VERSION ""

NS_ :

BS_:

BU_: PowertrainControlModule AtmosphericSensor SafetyRestraintSystem2 Aftertreatment_2_GasOutlet Aftertreatment_2_GasIntake DieselParticulateFilterControl Turbocharger SafetyRestraintSystem1 CabDisplay2 Aftertreatment_1_GasOutlet Aftertreatment_1_GasIntake OnBoardDataLogger OffBoardDiagnosticTool2 OffBoardDiagnosticTool1 FileServer ParkingBrakeController SeatController2 FanDriveController SteeringColumnUnit CommunicationUnitRadio CommunicationUnitSatellite CommunicationUnitCellular PropulsionBatteryCharger ChassisController2 ChassisController1 EngineValveControl AuxiliaryHeater2 AuxiliaryHeater1 ClutchUnit RampControl InformationSystem1 SuspensionSystemController2 OilSensor VehicleDynamicStability ExhaustEmissionController TransmissionDisplay2 TransmissionDisplay1 ClimateControl2 WaterPumpController RearAxleSteeringController LightingOperatorControl SeatController1 IgnitionController2 IgnitionController1 TirePressureController CabController2 CabController1 PneumaticSystemController SuspensionSystemController1 HydraulicPumpController EnduranceBrakingSystem RetarderExhaustEngine2 OnBoardDiagnosticUnit HeadwayController RetarderExhaustEngine1 CabDisplay1 ManagementComputer VirtualTerminal OffVehicleGateway PowerTakeOffFront HitchControl AuxiliaryValveControl BodyController TractorTrailerBridge1 StarterSystem ElectricalSystem VehicleSecurity VehicleNavigation AerodynamicControl ElectricalChargingSystem ClimateControl1 TripRecorder InstrumentCluster SuspensionDriveAxle2 SuspensionDriveAxle1 SuspensionSteerAxle SteeringController FuelSystem CruiseControl RetarderDriveline RetarderEngine BrakesDriveAxle2 BrakesDriveAxle1 BrakesSystemController BrakesSteerAxle AxleDrive2 AxleDrive1 AxleSteering PowerTakeOff ShiftConsoleSecondary ShiftConsolePrimary Transmission2 Transmission1 Engine2 Engine1

BO_ 2566834942 DM01: 22 Vector__XXX
 SG_ FlashRedStopLamp : 12|2@1+ (1,0) [0|3] "" Vector__XXX
 SG_ FlashProtectLamp : 8|2@1+ (1,0) [0|3] "" Vector__XXX
 SG_ FlashMalfuncIndicatorLamp : 14|2@1+ (1,0) [0|3] "" Vector__XXX
 SG_ FlashAmberWarningLamp : 10|2@1+ (1,0) [0|3] "" Vector__XXX
 SG_ MalfunctionIndicatorLampStatus : 6|2@1+ (1,0) [0|3] "" Vector__XXX
 SG_ AmberWarningLampStatus : 2|2@1+ (1,0) [0|3] "" Vector__XXX
 SG_ RedStopLampState : 4|2@1+ (1,0) [0|3] "" Vector__XXX
 SG_ ProtectLampStatus : 0|2@1+ (1,0) [0|3] "" Vector__XXX
 SG_ DTC5 : 144|32@1+ (1,0) [0|4294967295] "" Vector__XXX
 SG_ DTC4 : 112|32@1+ (1,0) [0|4294967295] "" Vector__XXX
 SG_ DTC3 : 80|32@1+ (1,0) [0|4294967295] "" Vector__XXX
 SG_ DTC2 : 48|32@1+ (1,0) [0|4294967295] "" Vector__XXX
 SG_ DTC1 : 16|32@1+ (1,0) [0|4294967295] "" Vector__XXX

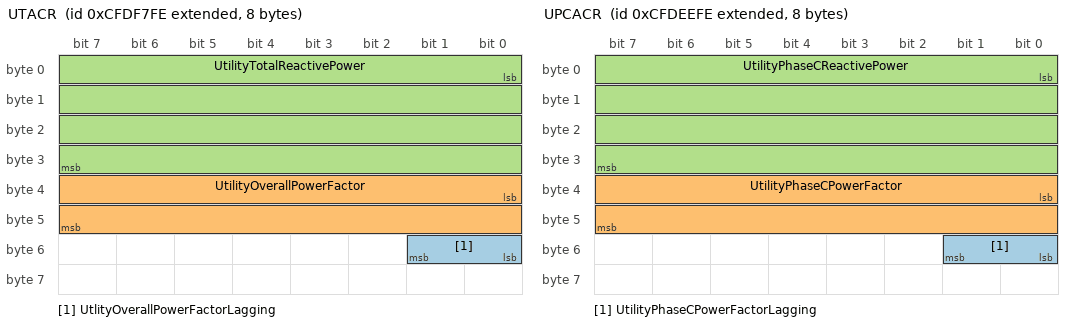
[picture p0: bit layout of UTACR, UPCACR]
BO_ 2365454334 UTACR: 8 Vector__XXX
 SG_ UtlityOverallPowerFactorLagging : 48|2@1+ (1,0) [0|3] "" Vector__XXX
 SG_ UtilityOverallPowerFactor : 32|16@1+ (6.103515625E-005,-1) [-1|2.921814] "" Vector__XXX
 SG_ UtilityTotalReactivePower : 0|32@1+ (1,-2000000000) [-2000000000|2211081215] "VAr" Vector__XXX

BO_ 2365454590 UTACP: 8 Vector__XXX
 SG_ UtilityTotalApparentPower : 32|32@1+ (1,-2000000000) [-2000000000|2211081215] "VA" Vector__XXX
 SG_ UtilityTotalRealPower : 0|32@1+ (1,-2000000000) [-2000000000|2211081215] "W" Vector__XXX

BO_ 2365451774 UTACE: 8 Vector__XXX
 SG_ UtilityTotalKWHoursImport : 32|32@1+ (1,0) [0|4211081215] "kWh" Vector__XXX
 SG_ UtilityTotalKWHoursExport : 0|32@1+ (1,0) [0|4211081215] "kWh" Vector__XXX

BO_ 2365452030 UPCACR: 8 Vector__XXX
 SG_ UtilityPhaseCPowerFactorLagging : 48|2@1+ (1,0) [0|3] "" Vector__XXX
 SG_ UtilityPhaseCPowerFactor : 32|16@1+ (6.103515625E-005,-1) [-1|2.921814] "" Vector__XXX
 SG_ UtilityPhaseCReactivePower : 0|32@1+ (1,-2000000000) [-2000000000|2211081215] "VAr" Vector__XXX

BO_ 2365452286 UPCACP: 8 Vector__XXX
 SG_ UtilityPhaseCApparentPower : 32|32@1+ (1,-2000000000) [-2000000000|2211081215] "VA" Vector__XXX
 SG_ UtilityPhaseCRealPower : 0|32@1+ (1,-2000000000) [-2000000000|2211081215] "W" Vector__XXX

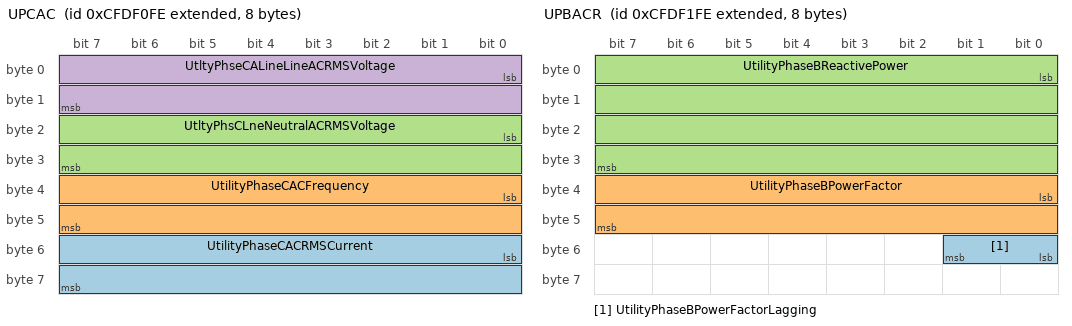
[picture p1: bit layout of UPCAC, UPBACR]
BO_ 2365452542 UPCAC: 8 Vector__XXX
 SG_ UtilityPhaseCACRMSCurrent : 48|16@1+ (1,0) [0|64255] "A" Vector__XXX
 SG_ UtilityPhaseCACFrequency : 32|16@1+ (0.0078125,0) [0|501.9921875] "Hz" Vector__XXX
 SG_ UtltyPhsCLneNeutralACRMSVoltage : 16|16@1+ (1,0) [0|64255] "V" Vector__XXX
 SG_ UtltyPhseCALineLineACRMSVoltage : 0|16@1+ (1,0) [0|64255] "V" Vector__XXX

BO_ 2365452798 UPBACR: 8 Vector__XXX
 SG_ UtilityPhaseBPowerFactorLagging : 48|2@1+ (1,0) [0|3] "" Vector__XXX
 SG_ UtilityPhaseBPowerFactor : 32|16@1+ (6.103515625E-005,-1) [-1|2.921814] "" Vector__XXX
 SG_ UtilityPhaseBReactivePower : 0|32@1+ (1,-2000000000) [-2000000000|2211081215] "VAr" Vector__XXX

BO_ 2365453054 UPBACP: 8 Vector__XXX
 SG_ UtilityPhaseBApparentPower : 32|32@1+ (1,-2000000000) [-2000000000|2211081215] "VA" Vector__XXX
 SG_ UtilityPhaseBRealPower : 0|32@1+ (1,-2000000000) [-2000000000|2211081215] "W" Vector__XXX

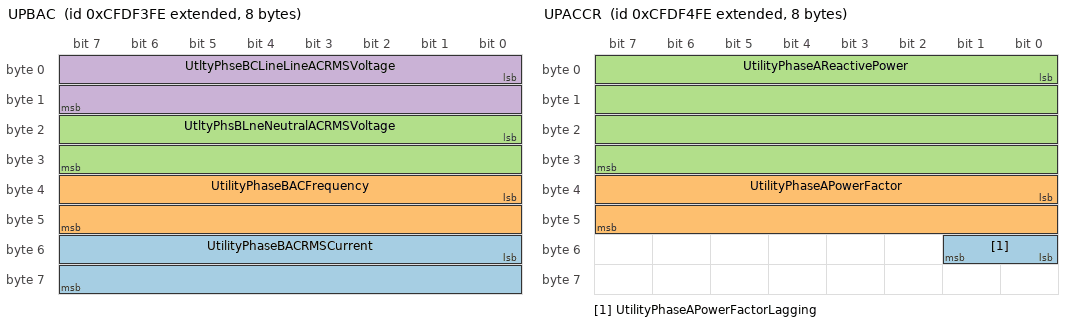
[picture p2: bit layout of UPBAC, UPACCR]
BO_ 2365453310 UPBAC: 8 Vector__XXX
 SG_ UtilityPhaseBACRMSCurrent : 48|16@1+ (1,0) [0|64255] "A" Vector__XXX
 SG_ UtilityPhaseBACFrequency : 32|16@1+ (0.0078125,0) [0|501.9921875] "Hz" Vector__XXX
 SG_ UtltyPhsBLneNeutralACRMSVoltage : 16|16@1+ (1,0) [0|64255] "V" Vector__XXX
 SG_ UtltyPhseBCLineLineACRMSVoltage : 0|16@1+ (1,0) [0|64255] "V" Vector__XXX

BO_ 2365453566 UPACCR: 8 Vector__XXX
 SG_ UtilityPhaseAPowerFactorLagging : 48|2@1+ (1,0) [0|3] "" Vector__XXX
 SG_ UtilityPhaseAPowerFactor : 32|16@1+ (6.103515625E-005,-1) [-1|2.921814] "" Vector__XXX
 SG_ UtilityPhaseAReactivePower : 0|32@1+ (1,-2000000000) [-2000000000|2211081215] "VAr" Vector__XXX

BO_ 2365453822 UPAACP: 8 Vector__XXX
 SG_ UtilityPhaseAApparentPower : 32|32@1+ (1,-2000000000) [-2000000000|2211081215] "VA" Vector__XXX
 SG_ UtilityPhaseARealPower : 0|32@1+ (1,-2000000000) [-2000000000|2211081215] "W" Vector__XXX

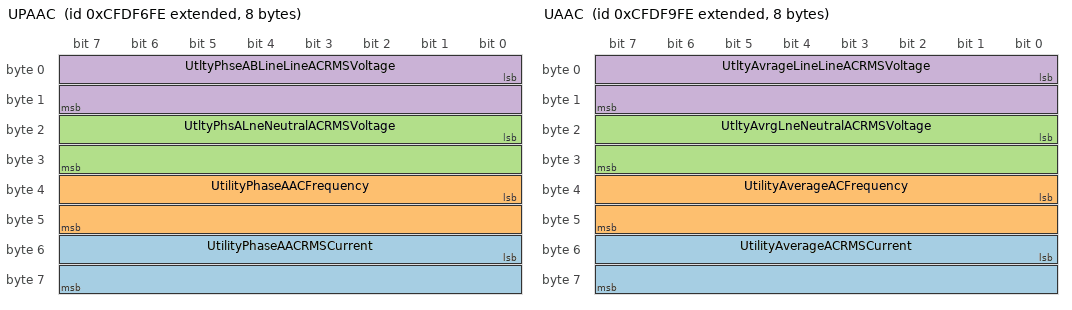
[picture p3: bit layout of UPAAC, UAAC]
BO_ 2365454078 UPAAC: 8 Vector__XXX
 SG_ UtilityPhaseAACRMSCurrent : 48|16@1+ (1,0) [0|64255] "A" Vector__XXX
 SG_ UtilityPhaseAACFrequency : 32|16@1+ (0.0078125,0) [0|501.9921875] "Hz" Vector__XXX
 SG_ UtltyPhsALneNeutralACRMSVoltage : 16|16@1+ (1,0) [0|64255] "V" Vector__XXX
 SG_ UtltyPhseABLineLineACRMSVoltage : 0|16@1+ (1,0) [0|64255] "V" Vector__XXX

BO_ 2365454846 UAAC: 8 Vector__XXX
 SG_ UtilityAverageACRMSCurrent : 48|16@1+ (1,0) [0|64255] "A" Vector__XXX
 SG_ UtilityAverageACFrequency : 32|16@1+ (0.0078125,0) [0|501.9921875] "Hz" Vector__XXX
 SG_ UtltyAvrgLneNeutralACRMSVoltage : 16|16@1+ (1,0) [0|64255] "V" Vector__XXX
 SG_ UtltyAvrageLineLineACRMSVoltage : 0|16@1+ (1,0) [0|64255] "V" Vector__XXX

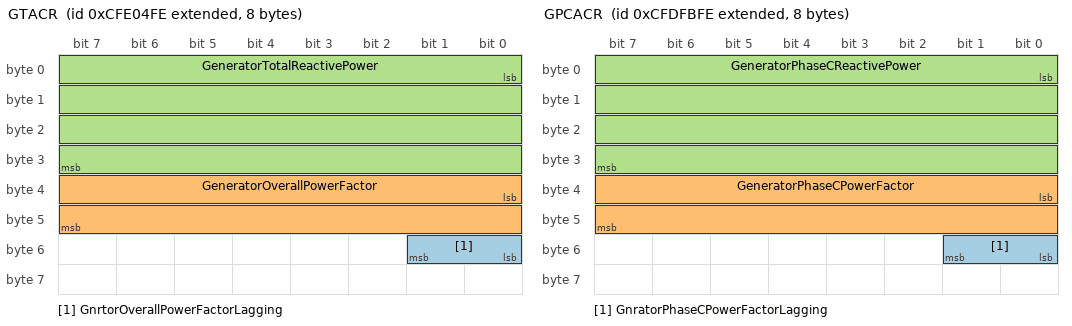
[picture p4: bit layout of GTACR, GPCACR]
BO_ 2365457662 GTACR: 8 Vector__XXX
 SG_ GnrtorOverallPowerFactorLagging : 48|2@1+ (1,0) [0|3] "" Vector__XXX
 SG_ GeneratorOverallPowerFactor : 32|16@1+ (6.103515625E-005,-1) [-1|1] "" Vector__XXX
 SG_ GeneratorTotalReactivePower : 0|32@1+ (1,-2000000000) [-2000000000|2211081215] "VAr" Vector__XXX

BO_ 2365457918 GTACP: 8 Vector__XXX
 SG_ GeneratorTotalApparentPower : 32|32@1+ (1,-2000000000) [-2000000000|2211081215] "VA" Vector__XXX
 SG_ GeneratorTotalRealPower : 0|32@1+ (1,-2000000000) [-2000000000|2211081215] "W" Vector__XXX

BO_ 2365455102 GTACE: 8 Vector__XXX
 SG_ GeneratorTotalKWHoursImport : 32|32@1+ (1,0) [0|4211081215] "kWh" Vector__XXX
 SG_ GeneratorTotalKWHoursExport : 0|32@1+ (1,0) [0|4211081215] "kWh" Vector__XXX

BO_ 2365455358 GPCACR: 8 Vector__XXX
 SG_ GnratorPhaseCPowerFactorLagging : 48|2@1+ (1,0) [0|3] "" Vector__XXX
 SG_ GeneratorPhaseCPowerFactor : 32|16@1+ (6.103515625E-005,-1) [-1|1] "" Vector__XXX
 SG_ GeneratorPhaseCReactivePower : 0|32@1+ (1,-2000000000) [-2000000000|2211081215] "VAr" Vector__XXX

BO_ 2365455614 GPCACP: 8 Vector__XXX
 SG_ GeneratorPhaseCApparentPower : 32|32@1+ (1,-2000000000) [-2000000000|2211081215] "VA" Vector__XXX
 SG_ GeneratorPhaseCRealPower : 0|32@1+ (1,-2000000000) [-2000000000|2211081215] "W" Vector__XXX

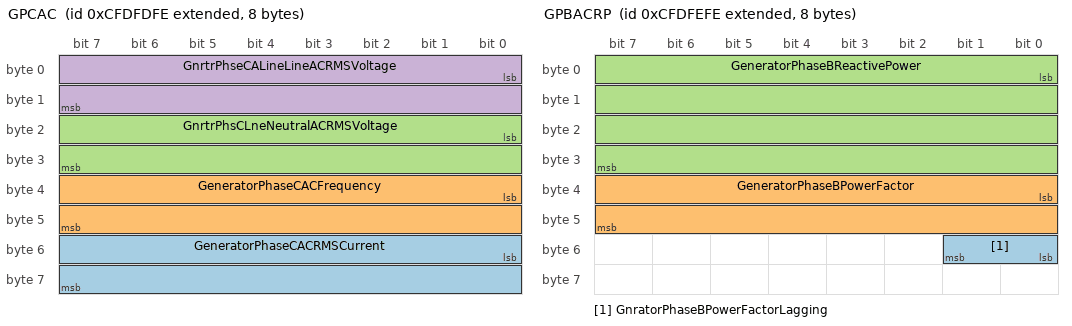
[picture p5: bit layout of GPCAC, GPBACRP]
BO_ 2365455870 GPCAC: 8 Vector__XXX
 SG_ GeneratorPhaseCACRMSCurrent : 48|16@1+ (1,0) [0|64255] "A" Vector__XXX
 SG_ GeneratorPhaseCACFrequency : 32|16@1+ (0.0078125,0) [0|501.9921875] "Hz" Vector__XXX
 SG_ GnrtrPhsCLneNeutralACRMSVoltage : 16|16@1+ (1,0) [0|64255] "V" Vector__XXX
 SG_ GnrtrPhseCALineLineACRMSVoltage : 0|16@1+ (1,0) [0|64255] "V" Vector__XXX

BO_ 2365456126 GPBACRP: 8 Vector__XXX
 SG_ GnratorPhaseBPowerFactorLagging : 48|2@1+ (1,0) [0|3] "" Vector__XXX
 SG_ GeneratorPhaseBPowerFactor : 32|16@1+ (6.103515625E-005,-1) [-1|1] "" Vector__XXX
 SG_ GeneratorPhaseBReactivePower : 0|32@1+ (1,-2000000000) [-2000000000|2211081215] "VAr" Vector__XXX

BO_ 2365456382 GPBACP: 8 Vector__XXX
 SG_ GeneratorPhaseBApparentPower : 32|32@1+ (1,-2000000000) [-2000000000|2211081215] "VA" Vector__XXX
 SG_ GeneratorPhaseBRealPower : 0|32@1+ (1,-2000000000) [-2000000000|2211081215] "W" Vector__XXX

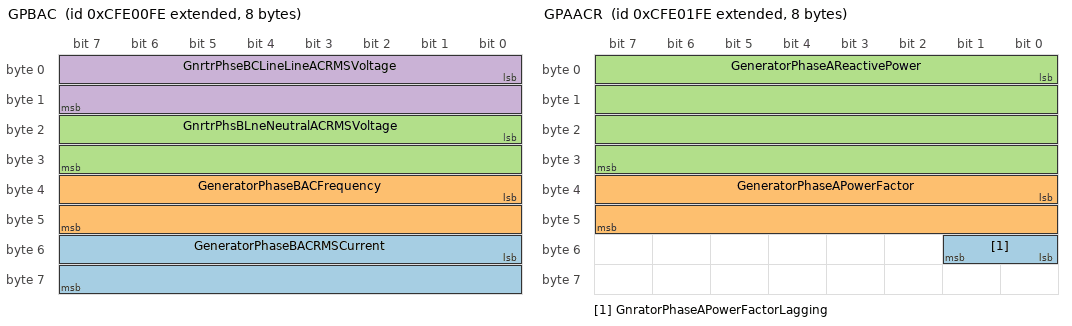
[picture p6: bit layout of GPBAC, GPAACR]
BO_ 2365456638 GPBAC: 8 Vector__XXX
 SG_ GeneratorPhaseBACRMSCurrent : 48|16@1+ (1,0) [0|64255] "A" Vector__XXX
 SG_ GeneratorPhaseBACFrequency : 32|16@1+ (0.0078125,0) [0|501.9921875] "Hz" Vector__XXX
 SG_ GnrtrPhsBLneNeutralACRMSVoltage : 16|16@1+ (1,0) [0|64255] "V" Vector__XXX
 SG_ GnrtrPhseBCLineLineACRMSVoltage : 0|16@1+ (1,0) [0|64255] "V" Vector__XXX

BO_ 2365456894 GPAACR: 8 Vector__XXX
 SG_ GnratorPhaseAPowerFactorLagging : 48|2@1+ (1,0) [0|3] "" Vector__XXX
 SG_ GeneratorPhaseAPowerFactor : 32|16@1+ (6.103515625E-005,-1) [-1|1] "" Vector__XXX
 SG_ GeneratorPhaseAReactivePower : 0|32@1+ (1,-2000000000) [-2000000000|2211081215] "VAr" Vector__XXX

BO_ 2365457150 GPAACP: 8 Vector__XXX
 SG_ GeneratorPhaseAApparentPower : 32|32@1+ (1,-2000000000) [-2000000000|2211081215] "VA" Vector__XXX
 SG_ GeneratorPhaseARealPower : 0|32@1+ (1,-2000000000) [-2000000000|2211081215] "W" Vector__XXX

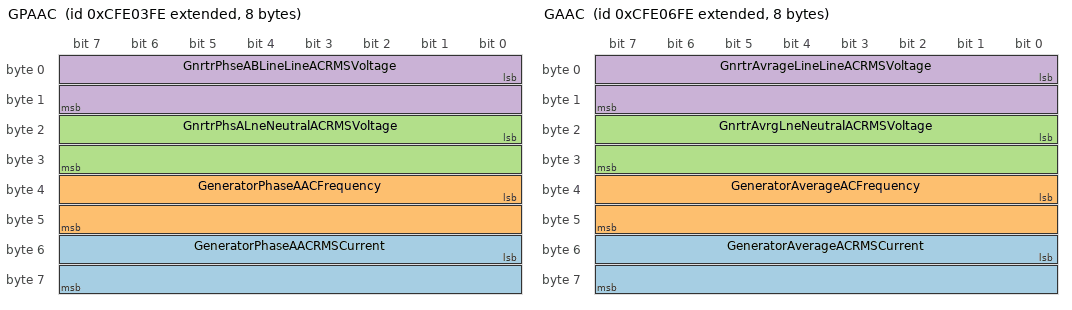
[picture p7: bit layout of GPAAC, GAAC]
BO_ 2365457406 GPAAC: 8 Vector__XXX
 SG_ GeneratorPhaseAACRMSCurrent : 48|16@1+ (1,0) [0|64255] "A" Vector__XXX
 SG_ GeneratorPhaseAACFrequency : 32|16@1+ (0.0078125,0) [0|501.9921875] "Hz" Vector__XXX
 SG_ GnrtrPhsALneNeutralACRMSVoltage : 16|16@1+ (1,0) [0|64255] "V" Vector__XXX
 SG_ GnrtrPhseABLineLineACRMSVoltage : 0|16@1+ (1,0) [0|64255] "V" Vector__XXX

BO_ 2365458174 GAAC: 8 Vector__XXX
 SG_ GeneratorAverageACRMSCurrent : 48|16@1+ (1,0) [0|64255] "A" Vector__XXX
 SG_ GeneratorAverageACFrequency : 32|16@1+ (0.0078125,0) [0|501.9921875] "Hz" Vector__XXX
 SG_ GnrtrAvrgLneNeutralACRMSVoltage : 16|16@1+ (1,0) [0|64255] "V" Vector__XXX
 SG_ GnrtrAvrageLineLineACRMSVoltage : 0|16@1+ (1,0) [0|64255] "V" Vector__XXX

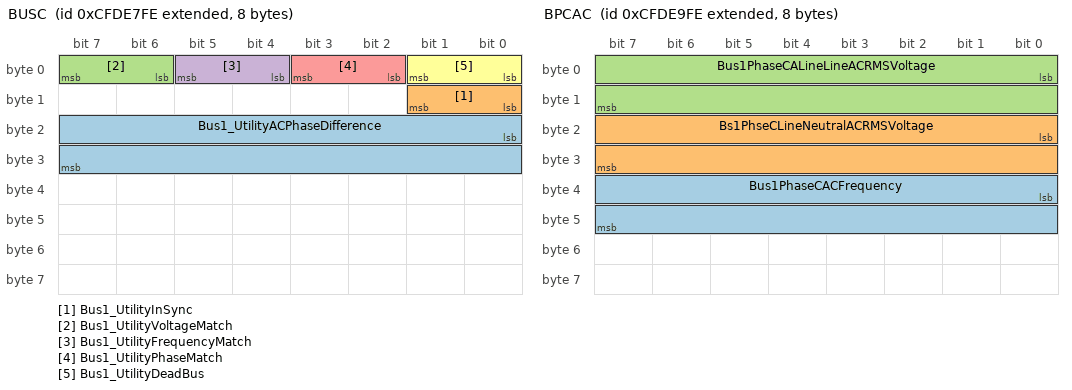
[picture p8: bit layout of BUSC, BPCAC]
BO_ 2365450238 BUSC: 8 Vector__XXX
 SG_ Bus1_UtilityACPhaseDifference : 16|16@1+ (0.0078125,-200) [-200|301.99] "deg" Vector__XXX
 SG_ Bus1_UtilityInSync : 8|2@1+ (1,0) [0|3] "" Vector__XXX
 SG_ Bus1_UtilityVoltageMatch : 6|2@1+ (1,0) [0|3] "" Vector__XXX
 SG_ Bus1_UtilityFrequencyMatch : 4|2@1+ (1,0) [0|3] "" Vector__XXX
 SG_ Bus1_UtilityPhaseMatch : 2|2@1+ (1,0) [0|3] "" Vector__XXX
 SG_ Bus1_UtilityDeadBus : 0|2@1+ (1,0) [0|3] "" Vector__XXX

BO_ 2365450750 BPCAC: 8 Vector__XXX
 SG_ Bus1PhaseCACFrequency : 32|16@1+ (0.0078125,0) [0|501.9921875] "Hz" Vector__XXX
 SG_ Bs1PhseCLineNeutralACRMSVoltage : 16|16@1+ (1,0) [0|64255] "V" Vector__XXX
 SG_ Bus1PhaseCALineLineACRMSVoltage : 0|16@1+ (1,0) [0|64255] "V" Vector__XXX

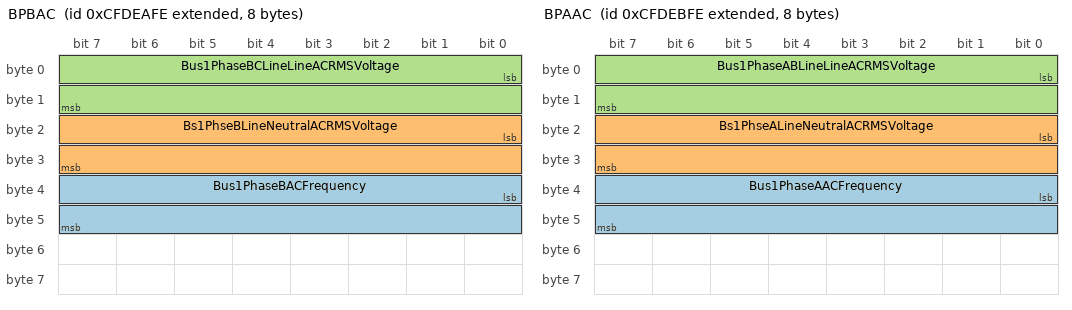
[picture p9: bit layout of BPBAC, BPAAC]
BO_ 2365451006 BPBAC: 8 Vector__XXX
 SG_ Bus1PhaseBACFrequency : 32|16@1+ (0.0078125,0) [0|501.9921875] "Hz" Vector__XXX
 SG_ Bs1PhseBLineNeutralACRMSVoltage : 16|16@1+ (1,0) [0|64255] "V" Vector__XXX
 SG_ Bus1PhaseBCLineLineACRMSVoltage : 0|16@1+ (1,0) [0|64255] "V" Vector__XXX

BO_ 2365451262 BPAAC: 8 Vector__XXX
 SG_ Bus1PhaseAACFrequency : 32|16@1+ (0.0078125,0) [0|501.9921875] "Hz" Vector__XXX
 SG_ Bs1PhseALineNeutralACRMSVoltage : 16|16@1+ (1,0) [0|64255] "V" Vector__XXX
 SG_ Bus1PhaseABLineLineACRMSVoltage : 0|16@1+ (1,0) [0|64255] "V" Vector__XXX

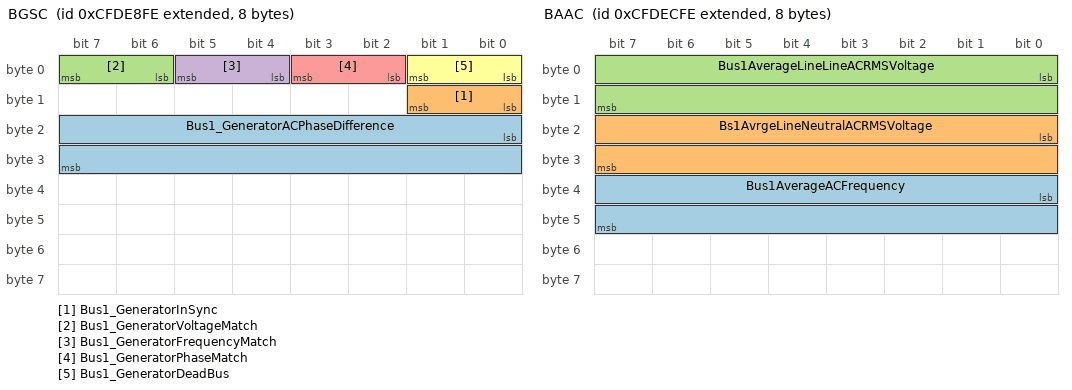
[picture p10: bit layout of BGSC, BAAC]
BO_ 2365450494 BGSC: 8 Vector__XXX
 SG_ Bus1_GeneratorACPhaseDifference : 16|16@1+ (0.0078125,-200) [-200|301.99] "deg" Vector__XXX
 SG_ Bus1_GeneratorInSync : 8|2@1+ (1,0) [0|3] "" Vector__XXX
 SG_ Bus1_GeneratorVoltageMatch : 6|2@1+ (1,0) [0|3] "" Vector__XXX
 SG_ Bus1_GeneratorFrequencyMatch : 4|2@1+ (1,0) [0|3] "" Vector__XXX
 SG_ Bus1_GeneratorPhaseMatch : 2|2@1+ (1,0) [0|3] "" Vector__XXX
 SG_ Bus1_GeneratorDeadBus : 0|2@1+ (1,0) [0|3] "" Vector__XXX

BO_ 2365451518 BAAC: 8 Vector__XXX
 SG_ Bus1AverageACFrequency : 32|16@1+ (0.0078125,0) [0|501.9921875] "Hz" Vector__XXX
 SG_ Bs1AvrgeLineNeutralACRMSVoltage : 16|16@1+ (1,0) [0|64255] "V" Vector__XXX
 SG_ Bus1AverageLineLineACRMSVoltage : 0|16@1+ (1,0) [0|64255] "V" Vector__XXX

BO_ 2566786558 WSMSTR: 8 Vector__XXX
 SG_ NumberOfMembers : 0|8@1+ (1,0) [0|0] "" Vector__XXX

BO_ 2566838526 CA: 9 Vector__XXX
 SG_ ReservedBit : 48|1@1+ (1,0) [0|0] "" Vector__XXX
 SG_ AddressAssignment : 64|8@1+ (1,0) [0|255] "" Vector__XXX
 SG_ ArbitraryAddressCapable : 63|1@1+ (1,0) [0|1] "" Vector__XXX
 SG_ IndustryGroup M : 60|3@1+ (1,0) [0|7] "" Vector__XXX
 SG_ VehicleSystemInstance : 56|4@1+ (1,0) [0|15] "" Vector__XXX
 SG_ Function : 40|8@1+ (1,0) [0|255] "" Vector__XXX
 SG_ VehicleSystem m0 : 49|7@1+ (1,0) [0|127] "" Vector__XXX
 SG_ FunctionInstance : 35|5@1+ (1,0) [0|31] "" Vector__XXX
 SG_ ECUInstance : 32|3@1+ (1,0) [0|7] "" Vector__XXX
 SG_ ManufacturerCode : 21|11@1+ (1,0) [0|2047] "" Vector__XXX
 SG_ IdentityNumber : 0|21@1+ (1,0) [0|2097152] "" Vector__XXX
 SG_ VehicleSystem5 m5 : 49|7@1+ (1,0) [0|127] "" Vector__XXX
 SG_ VehicleSystem4 m4 : 49|7@1+ (1,0) [0|127] "" Vector__XXX
 SG_ VehicleSystem3 m3 : 49|7@1+ (1,0) [0|127] "" Vector__XXX
 SG_ VehicleSystem2 m2 : 49|7@1+ (1,0) [0|127] "" Vector__XXX
 SG_ VehicleSystem1 m1 : 49|7@1+ (1,0) [0|127] "" Vector__XXX

BO_ 2565799678 AC: 8 Vector__XXX
 SG_ ReservedBit : 48|1@1+ (1,0) [0|0] "" Vector__XXX
 SG_ ArbitraryAddressCapable : 63|1@1+ (1,0) [0|1] "" Vector__XXX
 SG_ IndustryGroup M : 60|3@1+ (1,0) [0|7] "" Vector__XXX
 SG_ VehicleSystemInstance : 56|4@1+ (1,0) [0|15] "" Vector__XXX
 SG_ Function : 40|8@1+ (1,0) [0|255] "" Vector__XXX
 SG_ FunctionInstance : 35|5@1+ (1,0) [0|31] "" Vector__XXX
 SG_ ECUInstance : 32|3@1+ (1,0) [0|7] "" Vector__XXX
 SG_ ManufacturerCode : 21|11@1+ (1,0) [0|2047] "" Vector__XXX
 SG_ IdentityNumber : 0|21@1+ (1,0) [0|2097152] "" Vector__XXX
 SG_ VehicleSystem m0 : 49|7@1+ (1,0) [0|127] "" Vector__XXX
 SG_ VehicleSystem5 m5 : 49|7@1+ (1,0) [0|127] "" Vector__XXX
 SG_ VehicleSystem4 m4 : 49|7@1+ (1,0) [0|127] "" Vector__XXX
 SG_ VehicleSystem3 m3 : 49|7@1+ (1,0) [0|127] "" Vector__XXX
 SG_ VehicleSystem2 m2 : 49|7@1+ (1,0) [0|127] "" Vector__XXX
 SG_ VehicleSystem1 m1 : 49|7@1+ (1,0) [0|127] "" Vector__XXX

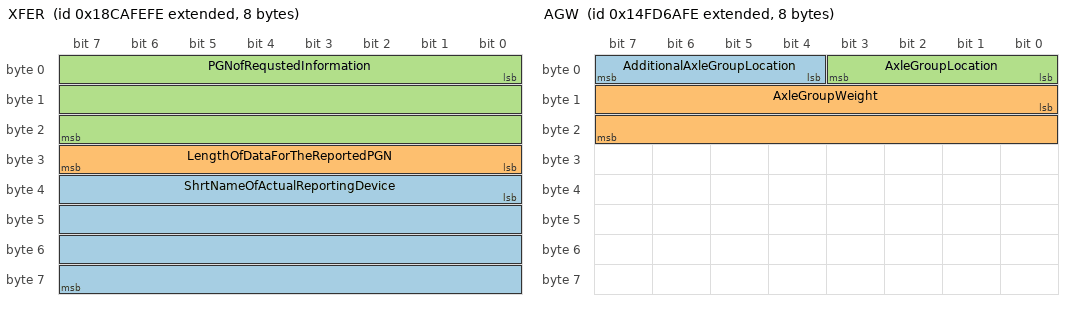
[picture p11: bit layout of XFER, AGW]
BO_ 2563440382 XFER: 8 Vector__XXX
 SG_ ShrtNameOfActualReportingDevice : 32|32@1+ (1,0) [0|0] "" Vector__XXX
 SG_ LengthOfDataForTheReportedPGN : 24|8@1+ (1,0) [0|255] "" Vector__XXX
 SG_ PGNofRequstedInformation : 0|24@1+ (1,0) [0|16777215] "" Vector__XXX

BO_ 2565603070 TPDT: 8 Vector__XXX
 SG_ SequenceNumber : 0|8@1+ (1,0) [0|255] "" Vector__XXX

BO_ 2565668606 TPCMxx: 8 Vector__XXX
 SG_ TotalNumberOfPacketsEoMA m19 : 24|8@1+ (1,0) [0|255] "" Vector__XXX
 SG_ TotalMessageSizeEoMA m19 : 8|16@1+ (1,0) [0|64255] "" Vector__XXX
 SG_ TotalMessageSizeBAM m32 : 8|16@1+ (1,0) [0|64255] "" Vector__XXX
 SG_ TotalNumberOfPacketsBAM m32 : 24|8@1+ (1,0) [0|255] "" Vector__XXX
 SG_ ConnectionAbortReason m255 : 8|8@1+ (1,0) [0|255] "" Vector__XXX
 SG_ NextPacketNumberToBeSent m17 : 16|8@1+ (1,0) [0|255] "" Vector__XXX
 SG_ NumberOfPacketsThatCanBeSent m17 : 8|8@1+ (1,0) [0|255] "" Vector__XXX
 SG_ PGNumber : 40|24@1+ (1,0) [0|16777200] "" Vector__XXX
 SG_ MaximumNumberOfPackets m16 : 32|8@1+ (1,0) [0|255] "" Vector__XXX
 SG_ TotalNumberOfPackets m16 : 24|8@1+ (1,0) [0|255] "" Vector__XXX
 SG_ TotalMessageSize m16 : 8|16@1+ (1,0) [0|64255] "" Vector__XXX
 SG_ ControlByte M : 0|8@1+ (1,0) [0|255] "" Vector__XXX

BO_ 2563374846 RQST2: 8 Vector__XXX
 SG_ ParameterGroupNumber : 0|24@1+ (1,0) [0|16777215] "" Vector__XXX
 SG_ UseTransferMode : 24|2@1+ (1,0) [0|3] "" Vector__XXX

BO_ 2565537534 RQST: 3 Vector__XXX
 SG_ ParameterGroupNumber : 0|24@1+ (1,0) [0|16777215] "" Vector__XXX

BO_ 2499635966 AGW: 8 Vector__XXX
 SG_ AdditionalAxleGroupLocation : 4|4@1+ (1,0) [0|15] "" Vector__XXX
 SG_ AxleGroupWeight : 8|16@1+ (2,0) [0|128510] "kg" Vector__XXX
 SG_ AxleGroupLocation : 0|4@1+ (1,0) [0|15] "" Vector__XXX

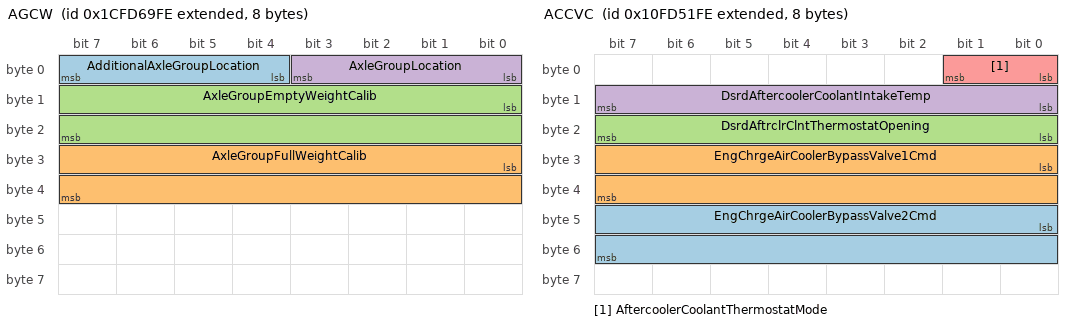
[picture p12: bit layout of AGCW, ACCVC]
BO_ 2633853438 AGCW: 8 Vector__XXX
 SG_ AdditionalAxleGroupLocation : 4|4@1+ (1,0) [0|15] "" Vector__XXX
 SG_ AxleGroupFullWeightCalib : 24|16@1+ (2,0) [0|128510] "kg" Vector__XXX
 SG_ AxleGroupEmptyWeightCalib : 8|16@1+ (2,0) [0|128510] "kg" Vector__XXX
 SG_ AxleGroupLocation : 0|4@1+ (1,0) [0|15] "" Vector__XXX

BO_ 2432520702 ACCVC: 8 Vector__XXX
 SG_ EngChrgeAirCoolerBypassValve2Cmd : 40|16@1+ (0.0025,0) [0|160.6375] "%" Vector__XXX
 SG_ EngChrgeAirCoolerBypassValve1Cmd : 24|16@1+ (0.0025,0) [0|160.6375] "%" Vector__XXX
 SG_ DsrdAftrclrClntThermostatOpening : 16|8@1+ (0.4,0) [0|100] "%" Vector__XXX
 SG_ DsrdAftercoolerCoolantIntakeTemp : 8|8@1+ (1,-40) [-40|210] "캜" Vector__XXX
 SG_ AftercoolerCoolantThermostatMode : 0|2@1+ (1,0) [0|3] "" Vector__XXX

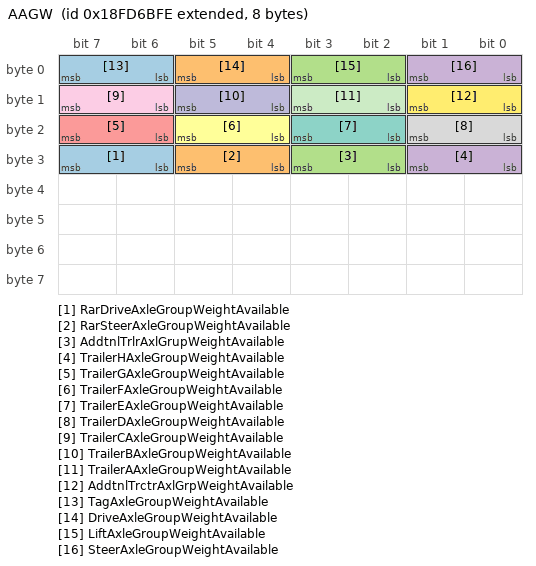
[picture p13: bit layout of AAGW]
BO_ 2566745086 AAGW: 8 Vector__XXX
 SG_ RarDriveAxleGroupWeightAvailable : 30|2@1+ (1,0) [0|3] "" Vector__XXX
 SG_ RarSteerAxleGroupWeightAvailable : 28|2@1+ (1,0) [0|3] "" Vector__XXX
 SG_ AddtnlTrlrAxlGrupWeightAvailable : 26|2@1+ (1,0) [0|3] "" Vector__XXX
 SG_ TrailerHAxleGroupWeightAvailable : 24|2@1+ (1,0) [0|3] "" Vector__XXX
 SG_ TrailerGAxleGroupWeightAvailable : 22|2@1+ (1,0) [0|3] "" Vector__XXX
 SG_ TrailerFAxleGroupWeightAvailable : 20|2@1+ (1,0) [0|3] "" Vector__XXX
 SG_ TrailerEAxleGroupWeightAvailable : 18|2@1+ (1,0) [0|3] "" Vector__XXX
 SG_ TrailerDAxleGroupWeightAvailable : 16|2@1+ (1,0) [0|3] "" Vector__XXX
 SG_ TrailerCAxleGroupWeightAvailable : 14|2@1+ (1,0) [0|3] "" Vector__XXX
 SG_ TrailerBAxleGroupWeightAvailable : 12|2@1+ (1,0) [0|3] "" Vector__XXX
 SG_ TrailerAAxleGroupWeightAvailable : 10|2@1+ (1,0) [0|3] "" Vector__XXX
 SG_ AddtnlTrctrAxlGrpWeightAvailable : 8|2@1+ (1,0) [0|3] "" Vector__XXX
 SG_ TagAxleGroupWeightAvailable : 6|2@1+ (1,0) [0|3] "" Vector__XXX
 SG_ DriveAxleGroupWeightAvailable : 4|2@1+ (1,0) [0|3] "" Vector__XXX
 SG_ LiftAxleGroupWeightAvailable : 2|2@1+ (1,0) [0|3] "" Vector__XXX
 SG_ SteerAxleGroupWeightAvailable : 0|2@1+ (1,0) [0|3] "" Vector__XXX

BO_ 2566739198 DM52: 22 Vector__XXX
 SG_ FlashRedStopLamp : 12|2@1+ (1,0) [0|3] "" Vector__XXX
 SG_ FlashProtectLamp : 8|2@1+ (1,0) [0|3] "" Vector__XXX
 SG_ FlashMalfuncIndicatorLamp : 14|2@1+ (1,0) [0|3] "" Vector__XXX
 SG_ FlashAmberWarningLamp : 10|2@1+ (1,0) [0|3] "" Vector__XXX
 SG_ MalfunctionIndicatorLampStatus : 6|2@1+ (1,0) [0|3] "" Vector__XXX
 SG_ AmberWarningLampStatus : 2|2@1+ (1,0) [0|3] "" Vector__XXX
 SG_ RedStopLampState : 4|2@1+ (1,0) [0|3] "" Vector__XXX
 SG_ ProtectLampStatus : 0|2@1+ (1,0) [0|3] "" Vector__XXX
 SG_ DTC5 : 144|32@1+ (1,0) [0|4294967295] "" Vector__XXX
 SG_ DTC4 : 112|32@1+ (1,0) [0|4294967295] "" Vector__XXX
 SG_ DTC3 : 80|32@1+ (1,0) [0|4294967295] "" Vector__XXX
 SG_ DTC2 : 48|32@1+ (1,0) [0|4294967295] "" Vector__XXX
 SG_ DTC1 : 16|32@1+ (1,0) [0|4294967295] "" Vector__XXX

BO_ 2566739454 DM51: 22 Vector__XXX
 SG_ FlashRedStopLamp : 12|2@1+ (1,0) [0|3] "" Vector__XXX
 SG_ FlashProtectLamp : 8|2@1+ (1,0) [0|3] "" Vector__XXX
 SG_ FlashMalfuncIndicatorLamp : 14|2@1+ (1,0) [0|3] "" Vector__XXX
 SG_ FlashAmberWarningLamp : 10|2@1+ (1,0) [0|3] "" Vector__XXX
 SG_ MalfunctionIndicatorLampStatus : 6|2@1+ (1,0) [0|3] "" Vector__XXX
 SG_ AmberWarningLampStatus : 2|2@1+ (1,0) [0|3] "" Vector__XXX
 SG_ RedStopLampState : 4|2@1+ (1,0) [0|3] "" Vector__XXX
 SG_ ProtectLampStatus : 0|2@1+ (1,0) [0|3] "" Vector__XXX
 SG_ DTC5 : 144|32@1+ (1,0) [0|4294967295] "" Vector__XXX
 SG_ DTC4 : 112|32@1+ (1,0) [0|4294967295] "" Vector__XXX
 SG_ DTC3 : 80|32@1+ (1,0) [0|4294967295] "" Vector__XXX
 SG_ DTC2 : 48|32@1+ (1,0) [0|4294967295] "" Vector__XXX
 SG_ DTC1 : 16|32@1+ (1,0) [0|4294967295] "" Vector__XXX

BO_ 2566739710 DM50: 22 Vector__XXX
 SG_ FlashRedStopLamp : 12|2@1+ (1,0) [0|3] "" Vector__XXX
 SG_ FlashProtectLamp : 8|2@1+ (1,0) [0|3] "" Vector__XXX
 SG_ FlashMalfuncIndicatorLamp : 14|2@1+ (1,0) [0|3] "" Vector__XXX
 SG_ FlashAmberWarningLamp : 10|2@1+ (1,0) [0|3] "" Vector__XXX
 SG_ MalfunctionIndicatorLampStatus : 6|2@1+ (1,0) [0|3] "" Vector__XXX
 SG_ AmberWarningLampStatus : 2|2@1+ (1,0) [0|3] "" Vector__XXX
 SG_ RedStopLampState : 4|2@1+ (1,0) [0|3] "" Vector__XXX
 SG_ ProtectLampStatus : 0|2@1+ (1,0) [0|3] "" Vector__XXX
 SG_ DTC5 : 144|32@1+ (1,0) [0|4294967295] "" Vector__XXX
 SG_ DTC4 : 112|32@1+ (1,0) [0|4294967295] "" Vector__XXX
 SG_ DTC3 : 80|32@1+ (1,0) [0|4294967295] "" Vector__XXX
 SG_ DTC2 : 48|32@1+ (1,0) [0|4294967295] "" Vector__XXX
 SG_ DTC1 : 16|32@1+ (1,0) [0|4294967295] "" Vector__XXX

BO_ 2566739966 DM49: 22 Vector__XXX
 SG_ FlashRedStopLamp : 12|2@1+ (1,0) [0|3] "" Vector__XXX
 SG_ FlashProtectLamp : 8|2@1+ (1,0) [0|3] "" Vector__XXX
 SG_ FlashMalfuncIndicatorLamp : 14|2@1+ (1,0) [0|3] "" Vector__XXX
 SG_ FlashAmberWarningLamp : 10|2@1+ (1,0) [0|3] "" Vector__XXX
 SG_ MalfunctionIndicatorLampStatus : 6|2@1+ (1,0) [0|3] "" Vector__XXX
 SG_ AmberWarningLampStatus : 2|2@1+ (1,0) [0|3] "" Vector__XXX
 SG_ RedStopLampState : 4|2@1+ (1,0) [0|3] "" Vector__XXX
 SG_ ProtectLampStatus : 0|2@1+ (1,0) [0|3] "" Vector__XXX
 SG_ DTC5 : 144|32@1+ (1,0) [0|4294967295] "" Vector__XXX
 SG_ DTC4 : 112|32@1+ (1,0) [0|4294967295] "" Vector__XXX
 SG_ DTC3 : 80|32@1+ (1,0) [0|4294967295] "" Vector__XXX
 SG_ DTC2 : 48|32@1+ (1,0) [0|4294967295] "" Vector__XXX
 SG_ DTC1 : 16|32@1+ (1,0) [0|4294967295] "" Vector__XXX

BO_ 2566740222 DM48: 22 Vector__XXX
 SG_ FlashRedStopLamp : 12|2@1+ (1,0) [0|3] "" Vector__XXX
 SG_ FlashProtectLamp : 8|2@1+ (1,0) [0|3] "" Vector__XXX
 SG_ FlashMalfuncIndicatorLamp : 14|2@1+ (1,0) [0|3] "" Vector__XXX
 SG_ FlashAmberWarningLamp : 10|2@1+ (1,0) [0|3] "" Vector__XXX
 SG_ MalfunctionIndicatorLampStatus : 6|2@1+ (1,0) [0|3] "" Vector__XXX
 SG_ AmberWarningLampStatus : 2|2@1+ (1,0) [0|3] "" Vector__XXX
 SG_ RedStopLampState : 4|2@1+ (1,0) [0|3] "" Vector__XXX
 SG_ ProtectLampStatus : 0|2@1+ (1,0) [0|3] "" Vector__XXX
 SG_ DTC5 : 144|32@1+ (1,0) [0|4294967295] "" Vector__XXX
 SG_ DTC4 : 112|32@1+ (1,0) [0|4294967295] "" Vector__XXX
 SG_ DTC3 : 80|32@1+ (1,0) [0|4294967295] "" Vector__XXX
 SG_ DTC2 : 48|32@1+ (1,0) [0|4294967295] "" Vector__XXX
 SG_ DTC1 : 16|32@1+ (1,0) [0|4294967295] "" Vector__XXX

BO_ 2566740478 DM47: 22 Vector__XXX
 SG_ FlashRedStopLamp : 12|2@1+ (1,0) [0|3] "" Vector__XXX
 SG_ FlashProtectLamp : 8|2@1+ (1,0) [0|3] "" Vector__XXX
 SG_ FlashMalfuncIndicatorLamp : 14|2@1+ (1,0) [0|3] "" Vector__XXX
 SG_ FlashAmberWarningLamp : 10|2@1+ (1,0) [0|3] "" Vector__XXX
 SG_ MalfunctionIndicatorLampStatus : 6|2@1+ (1,0) [0|3] "" Vector__XXX
 SG_ AmberWarningLampStatus : 2|2@1+ (1,0) [0|3] "" Vector__XXX
 SG_ RedStopLampState : 4|2@1+ (1,0) [0|3] "" Vector__XXX
 SG_ ProtectLampStatus : 0|2@1+ (1,0) [0|3] "" Vector__XXX
 SG_ DTC5 : 144|32@1+ (1,0) [0|4294967295] "" Vector__XXX
 SG_ DTC4 : 112|32@1+ (1,0) [0|4294967295] "" Vector__XXX
 SG_ DTC3 : 80|32@1+ (1,0) [0|4294967295] "" Vector__XXX
 SG_ DTC2 : 48|32@1+ (1,0) [0|4294967295] "" Vector__XXX
 SG_ DTC1 : 16|32@1+ (1,0) [0|4294967295] "" Vector__XXX

BO_ 2566740734 DM46: 22 Vector__XXX
 SG_ FlashRedStopLamp : 12|2@1+ (1,0) [0|3] "" Vector__XXX
 SG_ FlashProtectLamp : 8|2@1+ (1,0) [0|3] "" Vector__XXX
 SG_ FlashMalfuncIndicatorLamp : 14|2@1+ (1,0) [0|3] "" Vector__XXX
 SG_ FlashAmberWarningLamp : 10|2@1+ (1,0) [0|3] "" Vector__XXX
 SG_ MalfunctionIndicatorLampStatus : 6|2@1+ (1,0) [0|3] "" Vector__XXX
 SG_ AmberWarningLampStatus : 2|2@1+ (1,0) [0|3] "" Vector__XXX
 SG_ RedStopLampState : 4|2@1+ (1,0) [0|3] "" Vector__XXX
 SG_ ProtectLampStatus : 0|2@1+ (1,0) [0|3] "" Vector__XXX
 SG_ DTC5 : 144|32@1+ (1,0) [0|4294967295] "" Vector__XXX
 SG_ DTC4 : 112|32@1+ (1,0) [0|4294967295] "" Vector__XXX
 SG_ DTC3 : 80|32@1+ (1,0) [0|4294967295] "" Vector__XXX
 SG_ DTC2 : 48|32@1+ (1,0) [0|4294967295] "" Vector__XXX
 SG_ DTC1 : 16|32@1+ (1,0) [0|4294967295] "" Vector__XXX

BO_ 2566740990 DM45: 22 Vector__XXX
 SG_ FlashRedStopLamp : 12|2@1+ (1,0) [0|3] "" Vector__XXX
 SG_ FlashProtectLamp : 8|2@1+ (1,0) [0|3] "" Vector__XXX
 SG_ FlashMalfuncIndicatorLamp : 14|2@1+ (1,0) [0|3] "" Vector__XXX
 SG_ FlashAmberWarningLamp : 10|2@1+ (1,0) [0|3] "" Vector__XXX
 SG_ MalfunctionIndicatorLampStatus : 6|2@1+ (1,0) [0|3] "" Vector__XXX
 SG_ AmberWarningLampStatus : 2|2@1+ (1,0) [0|3] "" Vector__XXX
 SG_ RedStopLampState : 4|2@1+ (1,0) [0|3] "" Vector__XXX
 SG_ ProtectLampStatus : 0|2@1+ (1,0) [0|3] "" Vector__XXX
 SG_ DTC5 : 144|32@1+ (1,0) [0|4294967295] "" Vector__XXX
 SG_ DTC4 : 112|32@1+ (1,0) [0|4294967295] "" Vector__XXX
 SG_ DTC3 : 80|32@1+ (1,0) [0|4294967295] "" Vector__XXX
 SG_ DTC2 : 48|32@1+ (1,0) [0|4294967295] "" Vector__XXX
 SG_ DTC1 : 16|32@1+ (1,0) [0|4294967295] "" Vector__XXX

BO_ 2566741246 DM44: 22 Vector__XXX
 SG_ FlashRedStopLamp : 12|2@1+ (1,0) [0|3] "" Vector__XXX
 SG_ FlashProtectLamp : 8|2@1+ (1,0) [0|3] "" Vector__XXX
 SG_ FlashMalfuncIndicatorLamp : 14|2@1+ (1,0) [0|3] "" Vector__XXX
 SG_ FlashAmberWarningLamp : 10|2@1+ (1,0) [0|3] "" Vector__XXX
 SG_ MalfunctionIndicatorLampStatus : 6|2@1+ (1,0) [0|3] "" Vector__XXX
 SG_ AmberWarningLampStatus : 2|2@1+ (1,0) [0|3] "" Vector__XXX
 SG_ RedStopLampState : 4|2@1+ (1,0) [0|3] "" Vector__XXX
 SG_ ProtectLampStatus : 0|2@1+ (1,0) [0|3] "" Vector__XXX
 SG_ DTC5 : 144|32@1+ (1,0) [0|4294967295] "" Vector__XXX
 SG_ DTC4 : 112|32@1+ (1,0) [0|4294967295] "" Vector__XXX
 SG_ DTC3 : 80|32@1+ (1,0) [0|4294967295] "" Vector__XXX
 SG_ DTC2 : 48|32@1+ (1,0) [0|4294967295] "" Vector__XXX
 SG_ DTC1 : 16|32@1+ (1,0) [0|4294967295] "" Vector__XXX

BO_ 2566741502 DM43: 22 Vector__XXX
 SG_ FlashRedStopLamp : 12|2@1+ (1,0) [0|3] "" Vector__XXX
 SG_ FlashProtectLamp : 8|2@1+ (1,0) [0|3] "" Vector__XXX
 SG_ FlashMalfuncIndicatorLamp : 14|2@1+ (1,0) [0|3] "" Vector__XXX
 SG_ FlashAmberWarningLamp : 10|2@1+ (1,0) [0|3] "" Vector__XXX
 SG_ MalfunctionIndicatorLampStatus : 6|2@1+ (1,0) [0|3] "" Vector__XXX
 SG_ AmberWarningLampStatus : 2|2@1+ (1,0) [0|3] "" Vector__XXX
 SG_ RedStopLampState : 4|2@1+ (1,0) [0|3] "" Vector__XXX
 SG_ ProtectLampStatus : 0|2@1+ (1,0) [0|3] "" Vector__XXX
 SG_ DTC5 : 144|32@1+ (1,0) [0|4294967295] "" Vector__XXX
 SG_ DTC4 : 112|32@1+ (1,0) [0|4294967295] "" Vector__XXX
 SG_ DTC3 : 80|32@1+ (1,0) [0|4294967295] "" Vector__XXX
 SG_ DTC2 : 48|32@1+ (1,0) [0|4294967295] "" Vector__XXX
 SG_ DTC1 : 16|32@1+ (1,0) [0|4294967295] "" Vector__XXX

BO_ 2566741758 DM42: 22 Vector__XXX
 SG_ FlashRedStopLamp : 12|2@1+ (1,0) [0|3] "" Vector__XXX
 SG_ FlashProtectLamp : 8|2@1+ (1,0) [0|3] "" Vector__XXX
 SG_ FlashMalfuncIndicatorLamp : 14|2@1+ (1,0) [0|3] "" Vector__XXX
 SG_ FlashAmberWarningLamp : 10|2@1+ (1,0) [0|3] "" Vector__XXX
 SG_ MalfunctionIndicatorLampStatus : 6|2@1+ (1,0) [0|3] "" Vector__XXX
 SG_ AmberWarningLampStatus : 2|2@1+ (1,0) [0|3] "" Vector__XXX
 SG_ RedStopLampState : 4|2@1+ (1,0) [0|3] "" Vector__XXX
 SG_ ProtectLampStatus : 0|2@1+ (1,0) [0|3] "" Vector__XXX
 SG_ DTC5 : 144|32@1+ (1,0) [0|4294967295] "" Vector__XXX
 SG_ DTC4 : 112|32@1+ (1,0) [0|4294967295] "" Vector__XXX
 SG_ DTC3 : 80|32@1+ (1,0) [0|4294967295] "" Vector__XXX
 SG_ DTC2 : 48|32@1+ (1,0) [0|4294967295] "" Vector__XXX
 SG_ DTC1 : 16|32@1+ (1,0) [0|4294967295] "" Vector__XXX

CM_ BO_ 2566834942 "Active Diagnostic Trouble Codes
Active Diagnostic Trouble Codes";
CM_ SG_ 2566834942 FlashRedStopLamp "This parameter provides the capability to flash the RSL


00 - Slow Flash (1 Hz, 50 % duty cycle)
01 - Fast Flash (2 Hz or faster, 50% duty cycle)
10 - Reserved
11 - Unavailable / Do Not Flash";
CM_ SG_ 2566834942 FlashProtectLamp "This parameter provides the capability to flash the engine protect lamp


00 - Slow Flash (1 Hz, 50 % duty cycle)
01 - Fast Flash (2 Hz or faster, 50% duty cycle)
10 - Reserved
11 - Unavailable / Do Not Flash";
CM_ SG_ 2566834942 FlashMalfuncIndicatorLamp "This parameter provides the capability to flash the MIL
00 - Slow Flash (1 Hz, 50 % duty cycle)
01 - Fast Flash (2 Hz or faster, 50% duty cycle)
10 - Class C DTC
11 - Unavailable / Do Not Flash
Note:  State 10 is for WWH OBD discriminatory ...";
CM_ SG_ 2566834942 FlashAmberWarningLamp "This parameter provides the capability to flash the AWL

00 - Slow Flash (1 Hz, 50 % duty cycle)
01 - Fast Flash (2 Hz or faster, 50% duty cycle)
10 - Reserved
11 - Unavailable / Do Not Flash";
CM_ SG_ 2566834942 MalfunctionIndicatorLampStatus "A lamp used to relay only emissions-related trouble code information. This lamp is only illuminated when there is an emission-related trouble code active.
00     Lamp Off
01     Lamp On
10     Short MIL for WWH OBD
11     Not available
Note ...";
CM_ SG_ 2566834942 AmberWarningLampStatus "This lamp is used to relay trouble code information that is reporting a problem with the vehicle system but the vehicle need not be immediately stopped. 

00     Lamp Off
01     Lamp On
10     Reserved
11     Not available";
CM_ SG_ 2566834942 RedStopLampState "This lamp is used to relay trouble code information that is of a severe enough condition that it warrants stopping the vehicle.

00     Lamp Off
01     Lamp On
10     Reserved
11     Not available";
CM_ SG_ 2566834942 ProtectLampStatus "This lamp is used to relay trouble code information that is reporting a problem with a vehicle system that is most probably not electronic subsystem related. For instance, engine coolant temperature is exceeding its prescribed temperature range.
00 ...";
CM_ SG_ 2566834942 DTC5 "Diagnostic Trouble Code";
CM_ SG_ 2566834942 DTC4 "Diagnostic Trouble Code";
CM_ SG_ 2566834942 DTC3 "Diagnostic Trouble Code";
CM_ SG_ 2566834942 DTC2 "Diagnostic Trouble Code";
CM_ SG_ 2566834942 DTC1 "Diagnostic Trouble Code";
CM_ BO_ 2365454334 "Utility Total AC Reactive Power";
CM_ SG_ 2365454334 UtlityOverallPowerFactorLagging "Lead/lag status for utility incomer average power factor.

00 Leading
01 Lagging
10 Error
11 Not Available or Not Installed";
CM_ SG_ 2365454334 UtilityOverallPowerFactor "The average power factor of the utility incomer.";
CM_ SG_ 2365454334 UtilityTotalReactivePower "The total reactive power delivered by the utility incomer";
CM_ BO_ 2365454590 "Utility Total AC Power";
CM_ SG_ 2365454590 UtilityTotalApparentPower "The total apparent power delivered by the utility incomer.";
CM_ SG_ 2365454590 UtilityTotalRealPower "Total real power delivered by the utility incomer.";
CM_ BO_ 2365451774 "Utility Total AC Energy";
CM_ SG_ 2365451774 UtilityTotalKWHoursImport "The total kilowatt-hours that have been imported by the utility incomer.";
CM_ SG_ 2365451774 UtilityTotalKWHoursExport "The total kilowatt-hours that have been exported by the utility incomer.";
CM_ BO_ 2365452030 "Utility Phase C AC Reactive Power";
CM_ SG_ 2365452030 UtilityPhaseCPowerFactorLagging "Lead/lag status for utility incomer phase C power factor.

00 Leading
01 Lagging
10 Error
11 Not Available or Not Installed";
CM_ SG_ 2365452030 UtilityPhaseCPowerFactor "The power factor of phases C of the utility incomer.";
CM_ SG_ 2365452030 UtilityPhaseCReactivePower "The reactive power delivered by phase C of the utility incomer";
CM_ BO_ 2365452286 "Utility Phase C AC Power";
CM_ SG_ 2365452286 UtilityPhaseCApparentPower "The apparent power delivered by phase C of the utility incomer.";
CM_ SG_ 2365452286 UtilityPhaseCRealPower "The real power delivered by phase C of the utility incomer.";
CM_ BO_ 2365452542 "Utility Phase C AC Basic Quantities";
CM_ SG_ 2365452542 UtilityPhaseCACRMSCurrent "RMS current measured at the utility incomer phase C.";
CM_ SG_ 2365452542 UtilityPhaseCACFrequency "AC frequency measured at the utility incomer phase C.";
CM_ SG_ 2365452542 UtltyPhsCLneNeutralACRMSVoltage "Line to Neutral RMS voltage measured at the utility incomer phase C.";
CM_ SG_ 2365452542 UtltyPhseCALineLineACRMSVoltage "Line to Line RMS voltage measured at the utility incomer phase CA.";
CM_ BO_ 2365452798 "Utility Phase B AC Reactive Power";
CM_ SG_ 2365452798 UtilityPhaseBPowerFactorLagging "Lead/lag status for utility incomer phase B power factor.

00 Leading
01 Lagging
10 Error
11 Not Available or Not Installed";
CM_ SG_ 2365452798 UtilityPhaseBPowerFactor "The power factor of phases B of the utility incomer.";
CM_ SG_ 2365452798 UtilityPhaseBReactivePower "The reactive power delivered by phase B of the utility incomer";
CM_ BO_ 2365453054 "Utility Phase B AC Power";
CM_ SG_ 2365453054 UtilityPhaseBApparentPower "The apparent power delivered by phase B of the utility incomer.";
CM_ SG_ 2365453054 UtilityPhaseBRealPower "The real power delivered by phase B of the utility incomer.";
CM_ BO_ 2365453310 "Utility Phase B AC Basic Quantities";
CM_ SG_ 2365453310 UtilityPhaseBACRMSCurrent "RMS current measured at the utility incomer phase B.";
CM_ SG_ 2365453310 UtilityPhaseBACFrequency "AC frequency measured at the utility incomer phase B.";
CM_ SG_ 2365453310 UtltyPhsBLneNeutralACRMSVoltage "Line to Neutral RMS voltage measured at the utility incomer phase B.";
CM_ SG_ 2365453310 UtltyPhseBCLineLineACRMSVoltage "Line to Line RMS voltage measured at the utility incomer phase BC.";
CM_ BO_ 2365453566 "Utility Phase A AC Reactive Power";
CM_ SG_ 2365453566 UtilityPhaseAPowerFactorLagging "Lead/lag status for utility incomer phase A power factor.

00 Leading
01 Lagging
10 Error
11 Not Available or Not Installed";
CM_ SG_ 2365453566 UtilityPhaseAPowerFactor "The power factor of phase A of the utility incomer.";
CM_ SG_ 2365453566 UtilityPhaseAReactivePower "The reactive power delivered by phase A of the utility incomer";
CM_ BO_ 2365453822 "Utility Phase A AC Power";
CM_ SG_ 2365453822 UtilityPhaseAApparentPower "The apparent power delivered by phase A of the utility incomer.";
CM_ SG_ 2365453822 UtilityPhaseARealPower "The real power delivered by phase A of the utility incomer.";
CM_ BO_ 2365454078 "Utility Phase A Basic AC Quantities";
CM_ SG_ 2365454078 UtilityPhaseAACRMSCurrent "RMS current measured at the utility incomer phase A.";
CM_ SG_ 2365454078 UtilityPhaseAACFrequency "AC frequency measured at the utility incomer phase A.";
CM_ SG_ 2365454078 UtltyPhsALneNeutralACRMSVoltage "Line to Neutral RMS voltage measured at the utility incomer phase A.";
CM_ SG_ 2365454078 UtltyPhseABLineLineACRMSVoltage "Line to Line RMS voltage measured at the utility incomer phase AB.";
CM_ BO_ 2365454846 "Utility Average Basic AC Quantities";
CM_ SG_ 2365454846 UtilityAverageACRMSCurrent "Average RMS current measured at the utility incomer.";
CM_ SG_ 2365454846 UtilityAverageACFrequency "Average AC frequency measured at the utility incomer.";
CM_ SG_ 2365454846 UtltyAvrgLneNeutralACRMSVoltage "The average Line to Neutral AC RMS voltage measured at the utility incomer .";
CM_ SG_ 2365454846 UtltyAvrageLineLineACRMSVoltage "Average Line to Line RMS voltage measured at the utility incomer .";
CM_ BO_ 2365457662 "Generator Total AC Reactive Power";
CM_ SG_ 2365457662 GnrtorOverallPowerFactorLagging "Lead/lag status for generator average power factor.

00 Leading
01 Lagging
10 Error
11 Not Available or Not Installed";
CM_ SG_ 2365457662 GeneratorOverallPowerFactor "The average power factor of the generator.";
CM_ SG_ 2365457662 GeneratorTotalReactivePower "The total reactive power delivered by the generator";
CM_ BO_ 2365457918 "Generator Total AC Power";
CM_ SG_ 2365457918 GeneratorTotalApparentPower "The total apparent power delivered by the generator.";
CM_ SG_ 2365457918 GeneratorTotalRealPower "Total real power delivered by the generator.";
CM_ BO_ 2365455102 "Generator Total AC Energy";
CM_ SG_ 2365455102 GeneratorTotalKWHoursImport "The total kilowatt-hours that have been imported by the generator.";
CM_ SG_ 2365455102 GeneratorTotalKWHoursExport "The total kilowatt-hours that have been exported by the generator.";
CM_ BO_ 2365455358 "Generator Phase C AC Reactive Power";
CM_ SG_ 2365455358 GnratorPhaseCPowerFactorLagging "Lead/lag status for generator phase C power factor.

00 Leading
01 Lagging
10 Error
11 Not Available or Not Installed";
CM_ SG_ 2365455358 GeneratorPhaseCPowerFactor "The power factor of phases C of the generator.";
CM_ SG_ 2365455358 GeneratorPhaseCReactivePower "The reactive power delivered by phase C of the generator";
CM_ BO_ 2365455614 "Generator Phase C AC Power";
CM_ SG_ 2365455614 GeneratorPhaseCApparentPower "The apparent power delivered by phase C of the generator.";
CM_ SG_ 2365455614 GeneratorPhaseCRealPower "The real power delivered by phase C of the generator.";
CM_ BO_ 2365455870 "Generator Phase C Basic AC Quantities";
CM_ SG_ 2365455870 GeneratorPhaseCACRMSCurrent "RMS current measured at the generator phase C output.";
CM_ SG_ 2365455870 GeneratorPhaseCACFrequency "AC frequency measured at the generator phase C output.";
CM_ SG_ 2365455870 GnrtrPhsCLneNeutralACRMSVoltage "Line to Neutral RMS voltage measured at the generator phase C output.";
CM_ SG_ 2365455870 GnrtrPhseCALineLineACRMSVoltage "Line to Line RMS voltage measured at the generator phase CA output.";
CM_ BO_ 2365456126 "Generator Phase B AC Reactive Power";
CM_ SG_ 2365456126 GnratorPhaseBPowerFactorLagging "Lead/lag status for generator phase B power factor.

00 Leading
01 Lagging
10 Error
11 Not Available or Not Installed";
CM_ SG_ 2365456126 GeneratorPhaseBPowerFactor "The power factor of phases B of the generator.";
CM_ SG_ 2365456126 GeneratorPhaseBReactivePower "The reactive power delivered by phase B of the generator";
CM_ BO_ 2365456382 "Generator Phase B AC Power";
CM_ SG_ 2365456382 GeneratorPhaseBApparentPower "The apparent power delivered by phase B of the generator.";
CM_ SG_ 2365456382 GeneratorPhaseBRealPower "The real power delivered by phase B of the generator.";
CM_ BO_ 2365456638 "Generator Phase B Basic AC Quantities";
CM_ SG_ 2365456638 GeneratorPhaseBACRMSCurrent "RMS current measured at the generator phase B output.";
CM_ SG_ 2365456638 GeneratorPhaseBACFrequency "AC frequency measured at the generator phase B output.";
CM_ SG_ 2365456638 GnrtrPhsBLneNeutralACRMSVoltage "Line to Neutral RMS voltage measured at the generator phase B output.";
CM_ SG_ 2365456638 GnrtrPhseBCLineLineACRMSVoltage "Line to Line RMS voltage measured at the generator phase BC output.";
CM_ BO_ 2365456894 "Generator Phase A AC Reactive Power";
CM_ SG_ 2365456894 GnratorPhaseAPowerFactorLagging "Lead/lag status for generator phase A power factor.

00 Leading
01 Lagging
10 Error
11 Not Available or Not Installed";
CM_ SG_ 2365456894 GeneratorPhaseAPowerFactor "The power factor of phase A of the generator.";
CM_ SG_ 2365456894 GeneratorPhaseAReactivePower "The reactive power delivered by phase A of the generator";
CM_ BO_ 2365457150 "Generator Phase A AC Power";
CM_ SG_ 2365457150 GeneratorPhaseAApparentPower "The apparent power delivered by phase A of the generator.";
CM_ SG_ 2365457150 GeneratorPhaseARealPower "The real power delivered by phase A of the generator.";
CM_ BO_ 2365457406 "Generator Phase A Basic AC Quantities";
CM_ SG_ 2365457406 GeneratorPhaseAACRMSCurrent "RMS current measured at the generator phase A output.";
CM_ SG_ 2365457406 GeneratorPhaseAACFrequency "AC frequency measured at the generator phase A output.";
CM_ SG_ 2365457406 GnrtrPhsALneNeutralACRMSVoltage "Line to Neutral RMS voltage measured at the generator phase A output.";
CM_ SG_ 2365457406 GnrtrPhseABLineLineACRMSVoltage "Line to Line RMS voltage measured at the generator phase AB output.";
CM_ BO_ 2365458174 "Generator Average Basic AC Quantities";
CM_ SG_ 2365458174 GeneratorAverageACRMSCurrent "Average RMS current measured at the generator output.";
CM_ SG_ 2365458174 GeneratorAverageACFrequency "Average AC frequency measured at the generator output.";
CM_ SG_ 2365458174 GnrtrAvrgLneNeutralACRMSVoltage "The average Line to Neutral AC RMS voltage measured at the Generator output.";
CM_ SG_ 2365458174 GnrtrAvrageLineLineACRMSVoltage "Average Line to Line RMS voltage measured at the generator output.";
CM_ BO_ 2365450238 "Bus #1/Utility Sync Check Status";
CM_ SG_ 2365450238 Bus1_UtilityACPhaseDifference "The phase difference between the Bus #1 voltage and Utility voltage.";
CM_ SG_ 2365450238 Bus1_UtilityInSync "Indicator of whether Bus #1 and Utility are properly synchronized for paralleling. This indicator will be based on parameters such as Voltage Match, Frequency Match, and Phase Match.
00 Not synchronized
01 Synchronized
10 Error
11 Not Available ...";
CM_ SG_ 2365450238 Bus1_UtilityVoltageMatch "Indicator of whether voltage difference between Bus #1 and Utility is adequate for paralleling. This indicator will be based on the measured AC voltages qualified using parameters such as Voltage Tolerance.
00 Voltages do not match
01 Voltages ...";
CM_ SG_ 2365450238 Bus1_UtilityFrequencyMatch "Indicator of whether frequency difference between Bus #1 and Utility is adequate for paralleling. This indicator will be based on the measured AC frequencies qualified using parameters such as Frequency Tolerance, Phase Tolerance, and Dwell Time.
 ...";
CM_ SG_ 2365450238 Bus1_UtilityPhaseMatch "Indicator of whether phase difference between Bus #1 and Utility is adequate for paralleling. This indicator will be based on the measured AC phase difference qualified using parameters such as Phase Tolerance and Dwell Time.
00 Phases do not match
 ...";
CM_ SG_ 2365450238 Bus1_UtilityDeadBus "Indicator of whether Bus #1 is considered dead for closing to the utility. This indicator will be based on parameters such as Bus #1 Voltage and dead bus threshold values.
00 Bus is not dead
01 Bus is dead
10 Error
11 Not Available or Not ...";
CM_ BO_ 2365450750 "Bus #1 Phase C  Basic AC Quantities";
CM_ SG_ 2365450750 Bus1PhaseCACFrequency "AC frequency measured at bus #1 phase C.";
CM_ SG_ 2365450750 Bs1PhseCLineNeutralACRMSVoltage "Line to Neutral RMS voltage measured at bus #1 phase C.";
CM_ SG_ 2365450750 Bus1PhaseCALineLineACRMSVoltage "Line to Line RMS voltage measured at bus #1 phase CA.";
CM_ BO_ 2365451006 "Bus #1 Phase B  Basic AC Quantities";
CM_ SG_ 2365451006 Bus1PhaseBACFrequency "AC frequency measured at bus #1 phase B.";
CM_ SG_ 2365451006 Bs1PhseBLineNeutralACRMSVoltage "Line to Neutral RMS voltage measured at bus #1 phase B.";
CM_ SG_ 2365451006 Bus1PhaseBCLineLineACRMSVoltage "Line to Line RMS voltage measured at bus #1 phase BC.";
CM_ BO_ 2365451262 "Bus #1 Phase A  Basic AC Quantities";
CM_ SG_ 2365451262 Bus1PhaseAACFrequency "AC frequency measured at bus #1 phase A.";
CM_ SG_ 2365451262 Bs1PhseALineNeutralACRMSVoltage "Line to Neutral RMS voltage measured at bus #1 phase A.";
CM_ SG_ 2365451262 Bus1PhaseABLineLineACRMSVoltage "Line to Line RMS voltage measured at bus #1 phase AB.";
CM_ BO_ 2365450494 "Bus #1/Generator Sync Check Status";
CM_ SG_ 2365450494 Bus1_GeneratorACPhaseDifference "The phase difference between the Bus #1 voltage and Generator voltage.";
CM_ SG_ 2365450494 Bus1_GeneratorInSync "Indicator of whether Bus #1 and Generator are properly synchronized for paralleling. This indicator will be based on parameters such as Voltage Match, Frequency Match, and Phase Match.
00 Not synchronized
01 Synchronized
10 Error
11 Not ...";
CM_ SG_ 2365450494 Bus1_GeneratorVoltageMatch "Indicator of whether voltage difference between Bus #1 and Generator is adequate for paralleling. This indicator will be based on the measured AC voltages qualified using parameters such as Voltage Tolerance.
00 Voltages do not match
01 Voltages ...";
CM_ SG_ 2365450494 Bus1_GeneratorFrequencyMatch "Indicator of whether frequency difference between Bus #1 and Generator is adequate for paralleling. This indicator will be based on the measured AC frequencies qualified using parameters such as Frequency Tolerance, Phase Tolerance, and Dwell Time.
 ...";
CM_ SG_ 2365450494 Bus1_GeneratorPhaseMatch "Indicator of whether phase difference between Bus #1 and Generator is adequate for paralleling. This indicator will be based on the measured AC phase difference qualified using parameters such as Phase Tolerance and Dwell Time.
00 Phases do not ...";
CM_ SG_ 2365450494 Bus1_GeneratorDeadBus "Indicator of whether Bus #1 is considered dead for closing to the generator. This indicator will be based on parameters such as Bus #1 Voltage and dead bus threshold values.
00 Bus is not dead
01 Bus is dead
10 Error
11 Not Available or Not ...";
CM_ BO_ 2365451518 "Bus #1 Average Basic AC Quantities";
CM_ SG_ 2365451518 Bus1AverageACFrequency "Average AC frequency measured at bus #1.";
CM_ SG_ 2365451518 Bs1AvrgeLineNeutralACRMSVoltage "The average Line to Neutral AC RMS voltage measured at bus #1 .";
CM_ SG_ 2365451518 Bus1AverageLineLineACRMSVoltage "Average Line to Line RMS voltage measured at bus #1 .";
CM_ BO_ 2566786558 "Working Set Master
This message is sent by the Master of a Working Set to identify how many members there are in said set.";
CM_ BO_ 2566838526 "Commanded Address
Message that is used to assign a source address to a specific Controller Application Name.";
CM_ SG_ 2566838526 AddressAssignment "This 8 bit field is the 9th byte of the data field of the Commanded Address message.  It contains the source address that is to be assigned to the CA that has the NAME corresponding to the one conveyed in the first eight bytes of this Commanded ...";
CM_ SG_ 2566838526 IndustryGroup "0 = Global; 
   1  = On-Highway; 
   2  = Agricultural and Forestry; 
   3  = Construction; 
   4  = Marine;
   5  = Industrial - Process
          Control - Stationary (Gen-Sets)
   6  = Reserve for SAE
   7  = Reserve for SAE";
CM_ SG_ 2566838526 ManufacturerCode "Assigned by NMEA 2000 Committee";
CM_ BO_ 2565799678 "Address Claimed
Message used to claim an address for a Controller Application.";
CM_ SG_ 2565799678 IndustryGroup "0 = Global; 
   1  = On-Highway; 
   2  = Agricultural and Forestry; 
   3  = Construction; 
   4  = Marine;
   5  = Industrial - Process
          Control - Stationary (Gen-Sets)
   6  = Reserve for SAE
   7  = Reserve for SAE";
CM_ SG_ 2565799678 ManufacturerCode "Assigned by NMEA 2000 Committee";
CM_ BO_ 2563440382 "Transfer
The Transfer PGN provides a mechanism for reporting multiple data sets for a given PGN.";
CM_ SG_ 2563440382 ShrtNameOfActualReportingDevice "Subset of the 64-bit NAME (SPN 2848), consisting of the most significant 32 bits, which identifies the controller application.  It excludes the manufacturer code and identity number.  It is sometimes used to identify a device for instance in the ...";
CM_ SG_ 2563440382 LengthOfDataForTheReportedPGN "Length of data reported with the associated PGN via the Transfer PGN.";
CM_ SG_ 2563440382 PGNofRequstedInformation "PGN associated with this transfer message";
CM_ BO_ 2565603070 "Transport Protocol - Data Transfer
Used for the transfer of data associated with Parameter Groups that have more than 8 bytes of data.";
CM_ SG_ 2565603070 SequenceNumber "Sequence Number (TP.DT)";
CM_ BO_ 2565668606 "Transport Protocol - Connection Mgmt
Used for the transfer of Parameter Groups that have 9 or more bytes of data.";
CM_ SG_ 2565668606 TotalNumberOfPacketsEoMA "Total number of packets received for RTS/CTS message.  Zero and one are not valid values.";
CM_ SG_ 2565668606 TotalMessageSizeEoMA "Total message size (in bytes) received for RTS/CTS message.  Messages shorter than 9 data bytes should be sent without utilizing the transport protocol.  Messages longer than 1785 can not use the RTS/CTS transport protocol.";
CM_ SG_ 2565668606 TotalMessageSizeBAM "Total message size (in bytes) for BAM  message.  Messages shorter than 9 data bytes should be sent without utilizing the transport protocol.  Messages longer than 1785 can not use the BAM transport protocol.";
CM_ SG_ 2565668606 TotalNumberOfPacketsBAM "Total number of packets for BAM message.  Zero and one are not valid values.";
CM_ SG_ 2565668606 ConnectionAbortReason "Reason for connection abort message.
1 Already in one or more connection managed sessions and cannot support another.
2 System resources were needed for another task so this connection managed session was terminated.
3 A timeout occurred and this ...";
CM_ SG_ 2565668606 NextPacketNumberToBeSent "Next Packet Number to be sent (TP.CM_CTS)";
CM_ SG_ 2565668606 NumberOfPacketsThatCanBeSent "Number of Packets that can be sent (TP.CM_CTS)";
CM_ SG_ 2565668606 PGNumber "Requested PGN in the TP.CM_RTS message";
CM_ SG_ 2565668606 MaximumNumberOfPackets "Maximum number of packets for RTS/CTS message.  zero through four are not allowed";
CM_ SG_ 2565668606 TotalNumberOfPackets "Total number of packets for RTS/CTS message.  Zero and one are not valid values.";
CM_ SG_ 2565668606 TotalMessageSize "Total message size (in bytes) for RTS/CTS message.  Messages shorter than 9 data bytes should be sent without utilizing the transport protocol.  Messages longer than 1785 can not use the RTS/CTS transport protocol.";
CM_ SG_ 2565668606 ControlByte "Control byte (I.e. Group Function) associated with the Transport Protocol - Connection Management (PGN 60,416)
16 (dec) - Request to Send
17 (dec) - Clear to Send
19 (dec) - End of Message ACK
32 (dec) - Broadcast Announce Message
255 (dec) - ...";
CM_ BO_ 2563374846 "Request 2
Used to Request a PGN from network device or devices and to specify whether the response should use the Transfer PGN or not. PGN and data set for all devices it is tasked with reporting.";
CM_ SG_ 2563374846 ParameterGroupNumber "PGN which is requested by Request2 message";
CM_ SG_ 2563374846 UseTransferMode "Requester is to respond the Request 2 message via the Transfer PGN

00 No
01 Yes
10 Undefined
11 NA";
CM_ BO_ 2565537534 "Request
This message type, identified by the PGN, provides the capability to request information globally or from a specific destination.";
CM_ SG_ 2565537534 ParameterGroupNumber "Whenever it is necessary to identify a Parameter Group in the data field of a CAN data frame, it will be expressed in 24 bits.  The Parameter Group Number is a 24 bit value that has the following constituent components:  Reserved bit, Data Page bit, ...";
CM_ BO_ 2499635966 "Axle Group Weight
Combination of specific axle group and the weight imposed on that axle group.
NOTE � Multiple instances of this message will be required to transmit data for all available axle group weights. When reporting data for multiple axle ...";
CM_ SG_ 2499635966 AdditionalAxleGroupLocation "Location of the axle group, listed from front of the vehicle to rear.  If the value of SPN 4073 is 15, then this SPN is used to indicate the axle group referred to by this PGN. Otherwise, this SPN should be broadcast as 15.
0 = Reserved
1 = Rear ...";
CM_ SG_ 2499635966 AxleGroupWeight "Total mass imposed on the road surface by all the tires in the axle group";
CM_ SG_ 2499635966 AxleGroupLocation "Specific axle group used in conjunction with and when communicating the axle group weight, listed from the front of the vehicle to the rear.
If the value of SPN 5935 is 15, then this SPN is used to indicate the axle group referred to by this PGN ...";
CM_ BO_ 2633853438 "Axle Group Calibration Weights
Indicates axle group calibration weights";
CM_ SG_ 2633853438 AdditionalAxleGroupLocation "Location of the axle group, listed from front of the vehicle to rear.  If the value of SPN 4074 is 15, then this SPN is used to indicate the axle group referred to by this PGN. Otherwise, this SPN should be broadcast as 15.
0 = Reserved
1 = Rear ...";
CM_ SG_ 2633853438 AxleGroupFullWeightCalib "The full weight calibration measurement of an axle group";
CM_ SG_ 2633853438 AxleGroupEmptyWeightCalib "The empty weight calibration measurement of an axle group";
CM_ SG_ 2633853438 AxleGroupLocation "Specific axle group used in conjunction with and when communicating the axle group calibration, listed from the front of the vehicle to the rear.
If the value of SPN 5936 is 15, then this SPN is used to indicate the axle group referred to by this ...";
CM_ BO_ 2432520702 "Aftercooler Coolant Control Valve Command
Transmit status information of the Aftercooler Temperature Control";
CM_ SG_ 2432520702 EngChrgeAirCoolerBypassValve2Cmd "Desired percentage of charge air cooler Bypass Valve 2 opening. 0% means no air is bypassed. 100% means full bypass capacity.";
CM_ SG_ 2432520702 EngChrgeAirCoolerBypassValve1Cmd "Desired percentage of charge air cooler Bypass Valve 1 opening. 0% means no air is bypassed. 100% means full bypass capacity.";
CM_ SG_ 2432520702 DsrdAftrclrClntThermostatOpening "Used to transmit the desired position of the low temperature aftercooler temperature control valve.  0% represents the thermostat allows flow to completely bypass the aftercooler and 100% represents the flow is fully through the aftercooler.   If ...";
CM_ SG_ 2432520702 DsrdAftercoolerCoolantIntakeTemp "Indicates the desired temperature of the fluid in the low temperature aftercooler circuit to an electronic thermostat.  If the aftercooler coolant thermostat valve is operating in position control mode (see SPN 4198) then this value should be 0xFF.";
CM_ SG_ 2432520702 AftercoolerCoolantThermostatMode "Specifies if the aftercooler coolant thermostat valve will operate in temperature control mode or position control mode.

00 = temperature control mode
01 = position control mode (used for service only)
10 = reserved
11 = don't care/reserved";
CM_ BO_ 2566745086 "Available Axle Group Weights
Indicates which axle groups are included in the current weight calculation";
CM_ SG_ 2566745086 RarDriveAxleGroupWeightAvailable "Indicates if a second (or rear) drive axle group weight is available.
00 = Rear drive axle group not present
01 = Rear drive axle group present
10 = Reserved
11 = Not available / not applicable
Note:  If there is only one drive axle, use SPN ...";
CM_ SG_ 2566745086 RarSteerAxleGroupWeightAvailable "Indicates if a second (or rear) steer axle group weight is available.
00 = Rear Steer axle group not present
01 = Rear Steer axle group present
10 = Reserved
11 = Not available / not applicable
Note:  If there is only one steer axle, use SPN ...";
CM_ SG_ 2566745086 AddtnlTrlrAxlGrupWeightAvailable "Indicates the availability of the additional trailer axle group for purposes of weight measurement

00 = Additional trailer axle group not present
01 = Additional trailer axle group present
10 = Reserved
11 = Not available / not applicable";
CM_ SG_ 2566745086 TrailerHAxleGroupWeightAvailable "Indicates the availability of the trailer H axle group for purposes of weight measurement

00 = Trailer H axle group not present
01 = Trailer H axle group present
10 = Reserved
11 = Not available / not applicable";
CM_ SG_ 2566745086 TrailerGAxleGroupWeightAvailable "Indicates the availability of the trailer G axle group for purposes of weight measurement

00 = Trailer G axle group not present
01 = Trailer G axle group present
10 = Reserved
11 = Not available / not applicable";
CM_ SG_ 2566745086 TrailerFAxleGroupWeightAvailable "Indicates the availability of the trailer F axle group for purposes of weight measurement

00 = Trailer F axle group not present
01 = Trailer F axle group present
10 = Reserved
11 = Not available / not applicable";
CM_ SG_ 2566745086 TrailerEAxleGroupWeightAvailable "Indicates the availability of the trailer E axle group for purposes of weight measurement

00 = Trailer E axle group not present
01 = Trailer E axle group present
10 = Reserved
11 = Not available / not applicable";
CM_ SG_ 2566745086 TrailerDAxleGroupWeightAvailable "Indicates the availability of the trailer D axle group for purposes of weight measurement

00 = Trailer D axle group not present
01 = Trailer D axle group present
10 = Reserved
11 = Not available / not applicable";
CM_ SG_ 2566745086 TrailerCAxleGroupWeightAvailable "Indicates the availability of the trailer C axle group for purposes of weight measurement

00 = Trailer C axle group not present
01 = Trailer C axle group present
10 = Reserved
11 = Not available / not applicable";
CM_ SG_ 2566745086 TrailerBAxleGroupWeightAvailable "Indicates the availability of the trailer B axle group for purposes of weight measurement

00 = Trailer B axle group not present
01 = Trailer B axle group present
10 = Reserved
11 = Not available / not applicable";
CM_ SG_ 2566745086 TrailerAAxleGroupWeightAvailable "Indicates the availability of the trailer A axle group for purposes of weight measurement

00 = Trailer A axle group not present
01 = Trailer A axle group present
10 = Reserved
11 = Not available / not applicable";
CM_ SG_ 2566745086 AddtnlTrctrAxlGrpWeightAvailable "Indicates the availability of the additional tractor axle group for purposes of weight measurement

00 = Additional tractor axle group not present
01 = Additional tractor axle group present
10 = Reserved
11 = Not available / not applicable";
CM_ SG_ 2566745086 TagAxleGroupWeightAvailable "Indicates the availability of the tag axle group for purposes of weight measurement

00 = Tag axle group not present
01 = Tag axle group present
10 = Reserved
11 = Not available / not applicable";
CM_ SG_ 2566745086 DriveAxleGroupWeightAvailable "Indicates the availability of the sole or forward-most drive axle group for purposes of weight measurement
00 = Drive axle group not present
01 = Drive axle group present
10 = Reserved
11 = Not available / not applicable
If there is only one ...";
CM_ SG_ 2566745086 LiftAxleGroupWeightAvailable "Indicates the availability of the lift axle group for purposes of weight measurement

00 = Lift axle group not present
01 = Lift axle group present
10 = Reserved
11 = Not available / not applicable";
CM_ SG_ 2566745086 SteerAxleGroupWeightAvailable "Indicates the availability of the sole or forward-most steer axle group for purposes of weight measurement
00 = Steer axle group not present
01 = Steer axle group present
10 = Reserved
11 = Not available / not applicable
If there is only one ...";
CM_ BO_ 2566739198 "DTCs - C, Previously Active
Previously Active DTCs that are classified as class C severity.";
CM_ SG_ 2566739198 FlashRedStopLamp "This parameter provides the capability to flash the RSL


00 - Slow Flash (1 Hz, 50 % duty cycle)
01 - Fast Flash (2 Hz or faster, 50% duty cycle)
10 - Reserved
11 - Unavailable / Do Not Flash";
CM_ SG_ 2566739198 FlashProtectLamp "This parameter provides the capability to flash the engine protect lamp


00 - Slow Flash (1 Hz, 50 % duty cycle)
01 - Fast Flash (2 Hz or faster, 50% duty cycle)
10 - Reserved
11 - Unavailable / Do Not Flash";
CM_ SG_ 2566739198 FlashMalfuncIndicatorLamp "This parameter provides the capability to flash the MIL
00 - Slow Flash (1 Hz, 50 % duty cycle)
01 - Fast Flash (2 Hz or faster, 50% duty cycle)
10 - Class C DTC
11 - Unavailable / Do Not Flash
Note:  State 10 is for WWH OBD discriminatory ...";
CM_ SG_ 2566739198 FlashAmberWarningLamp "This parameter provides the capability to flash the AWL

00 - Slow Flash (1 Hz, 50 % duty cycle)
01 - Fast Flash (2 Hz or faster, 50% duty cycle)
10 - Reserved
11 - Unavailable / Do Not Flash";
CM_ SG_ 2566739198 MalfunctionIndicatorLampStatus "A lamp used to relay only emissions-related trouble code information. This lamp is only illuminated when there is an emission-related trouble code active.
00     Lamp Off
01     Lamp On
10     Short MIL for WWH OBD
11     Not available
Note ...";
CM_ SG_ 2566739198 AmberWarningLampStatus "This lamp is used to relay trouble code information that is reporting a problem with the vehicle system but the vehicle need not be immediately stopped. 

00     Lamp Off
01     Lamp On
10     Reserved
11     Not available";
CM_ SG_ 2566739198 RedStopLampState "This lamp is used to relay trouble code information that is of a severe enough condition that it warrants stopping the vehicle.

00     Lamp Off
01     Lamp On
10     Reserved
11     Not available";
CM_ SG_ 2566739198 ProtectLampStatus "This lamp is used to relay trouble code information that is reporting a problem with a vehicle system that is most probably not electronic subsystem related. For instance, engine coolant temperature is exceeding its prescribed temperature range.
00 ...";
CM_ SG_ 2566739198 DTC5 "Diagnostic Trouble Code";
CM_ SG_ 2566739198 DTC4 "Diagnostic Trouble Code";
CM_ SG_ 2566739198 DTC3 "Diagnostic Trouble Code";
CM_ SG_ 2566739198 DTC2 "Diagnostic Trouble Code";
CM_ SG_ 2566739198 DTC1 "Diagnostic Trouble Code";
CM_ BO_ 2566739454 "DTCs - C, Confirmed and Active
Confirmed and Active DTCs that are classified as class C severity.";
CM_ SG_ 2566739454 FlashRedStopLamp "This parameter provides the capability to flash the RSL


00 - Slow Flash (1 Hz, 50 % duty cycle)
01 - Fast Flash (2 Hz or faster, 50% duty cycle)
10 - Reserved
11 - Unavailable / Do Not Flash";
CM_ SG_ 2566739454 FlashProtectLamp "This parameter provides the capability to flash the engine protect lamp


00 - Slow Flash (1 Hz, 50 % duty cycle)
01 - Fast Flash (2 Hz or faster, 50% duty cycle)
10 - Reserved
11 - Unavailable / Do Not Flash";
CM_ SG_ 2566739454 FlashMalfuncIndicatorLamp "This parameter provides the capability to flash the MIL
00 - Slow Flash (1 Hz, 50 % duty cycle)
01 - Fast Flash (2 Hz or faster, 50% duty cycle)
10 - Class C DTC
11 - Unavailable / Do Not Flash
Note:  State 10 is for WWH OBD discriminatory ...";
CM_ SG_ 2566739454 FlashAmberWarningLamp "This parameter provides the capability to flash the AWL

00 - Slow Flash (1 Hz, 50 % duty cycle)
01 - Fast Flash (2 Hz or faster, 50% duty cycle)
10 - Reserved
11 - Unavailable / Do Not Flash";
CM_ SG_ 2566739454 MalfunctionIndicatorLampStatus "A lamp used to relay only emissions-related trouble code information. This lamp is only illuminated when there is an emission-related trouble code active.
00     Lamp Off
01     Lamp On
10     Short MIL for WWH OBD
11     Not available
Note ...";
CM_ SG_ 2566739454 AmberWarningLampStatus "This lamp is used to relay trouble code information that is reporting a problem with the vehicle system but the vehicle need not be immediately stopped. 

00     Lamp Off
01     Lamp On
10     Reserved
11     Not available";
CM_ SG_ 2566739454 RedStopLampState "This lamp is used to relay trouble code information that is of a severe enough condition that it warrants stopping the vehicle.

00     Lamp Off
01     Lamp On
10     Reserved
11     Not available";
CM_ SG_ 2566739454 ProtectLampStatus "This lamp is used to relay trouble code information that is reporting a problem with a vehicle system that is most probably not electronic subsystem related. For instance, engine coolant temperature is exceeding its prescribed temperature range.
00 ...";
CM_ SG_ 2566739454 DTC5 "Diagnostic Trouble Code";
CM_ SG_ 2566739454 DTC4 "Diagnostic Trouble Code";
CM_ SG_ 2566739454 DTC3 "Diagnostic Trouble Code";
CM_ SG_ 2566739454 DTC2 "Diagnostic Trouble Code";
CM_ SG_ 2566739454 DTC1 "Diagnostic Trouble Code";
CM_ BO_ 2566739710 "DTCs - C, Pending
Pending DTCs that are classified as class C severity.";
CM_ SG_ 2566739710 FlashRedStopLamp "This parameter provides the capability to flash the RSL


00 - Slow Flash (1 Hz, 50 % duty cycle)
01 - Fast Flash (2 Hz or faster, 50% duty cycle)
10 - Reserved
11 - Unavailable / Do Not Flash";
CM_ SG_ 2566739710 FlashProtectLamp "This parameter provides the capability to flash the engine protect lamp


00 - Slow Flash (1 Hz, 50 % duty cycle)
01 - Fast Flash (2 Hz or faster, 50% duty cycle)
10 - Reserved
11 - Unavailable / Do Not Flash";
CM_ SG_ 2566739710 FlashMalfuncIndicatorLamp "This parameter provides the capability to flash the MIL
00 - Slow Flash (1 Hz, 50 % duty cycle)
01 - Fast Flash (2 Hz or faster, 50% duty cycle)
10 - Class C DTC
11 - Unavailable / Do Not Flash
Note:  State 10 is for WWH OBD discriminatory ...";
CM_ SG_ 2566739710 FlashAmberWarningLamp "This parameter provides the capability to flash the AWL

00 - Slow Flash (1 Hz, 50 % duty cycle)
01 - Fast Flash (2 Hz or faster, 50% duty cycle)
10 - Reserved
11 - Unavailable / Do Not Flash";
CM_ SG_ 2566739710 MalfunctionIndicatorLampStatus "A lamp used to relay only emissions-related trouble code information. This lamp is only illuminated when there is an emission-related trouble code active.
00     Lamp Off
01     Lamp On
10     Short MIL for WWH OBD
11     Not available
Note ...";
CM_ SG_ 2566739710 AmberWarningLampStatus "This lamp is used to relay trouble code information that is reporting a problem with the vehicle system but the vehicle need not be immediately stopped. 

00     Lamp Off
01     Lamp On
10     Reserved
11     Not available";
CM_ SG_ 2566739710 RedStopLampState "This lamp is used to relay trouble code information that is of a severe enough condition that it warrants stopping the vehicle.

00     Lamp Off
01     Lamp On
10     Reserved
11     Not available";
CM_ SG_ 2566739710 ProtectLampStatus "This lamp is used to relay trouble code information that is reporting a problem with a vehicle system that is most probably not electronic subsystem related. For instance, engine coolant temperature is exceeding its prescribed temperature range.
00 ...";
CM_ SG_ 2566739710 DTC5 "Diagnostic Trouble Code";
CM_ SG_ 2566739710 DTC4 "Diagnostic Trouble Code";
CM_ SG_ 2566739710 DTC3 "Diagnostic Trouble Code";
CM_ SG_ 2566739710 DTC2 "Diagnostic Trouble Code";
CM_ SG_ 2566739710 DTC1 "Diagnostic Trouble Code";
CM_ BO_ 2566739966 "DTCs - B2, Previously Active
Previously Active DTCs that are classified as class B2 severity.";
CM_ SG_ 2566739966 FlashRedStopLamp "This parameter provides the capability to flash the RSL


00 - Slow Flash (1 Hz, 50 % duty cycle)
01 - Fast Flash (2 Hz or faster, 50% duty cycle)
10 - Reserved
11 - Unavailable / Do Not Flash";
CM_ SG_ 2566739966 FlashProtectLamp "This parameter provides the capability to flash the engine protect lamp


00 - Slow Flash (1 Hz, 50 % duty cycle)
01 - Fast Flash (2 Hz or faster, 50% duty cycle)
10 - Reserved
11 - Unavailable / Do Not Flash";
CM_ SG_ 2566739966 FlashMalfuncIndicatorLamp "This parameter provides the capability to flash the MIL
00 - Slow Flash (1 Hz, 50 % duty cycle)
01 - Fast Flash (2 Hz or faster, 50% duty cycle)
10 - Class C DTC
11 - Unavailable / Do Not Flash
Note:  State 10 is for WWH OBD discriminatory ...";
CM_ SG_ 2566739966 FlashAmberWarningLamp "This parameter provides the capability to flash the AWL

00 - Slow Flash (1 Hz, 50 % duty cycle)
01 - Fast Flash (2 Hz or faster, 50% duty cycle)
10 - Reserved
11 - Unavailable / Do Not Flash";
CM_ SG_ 2566739966 MalfunctionIndicatorLampStatus "A lamp used to relay only emissions-related trouble code information. This lamp is only illuminated when there is an emission-related trouble code active.
00     Lamp Off
01     Lamp On
10     Short MIL for WWH OBD
11     Not available
Note ...";
CM_ SG_ 2566739966 AmberWarningLampStatus "This lamp is used to relay trouble code information that is reporting a problem with the vehicle system but the vehicle need not be immediately stopped. 

00     Lamp Off
01     Lamp On
10     Reserved
11     Not available";
CM_ SG_ 2566739966 RedStopLampState "This lamp is used to relay trouble code information that is of a severe enough condition that it warrants stopping the vehicle.

00     Lamp Off
01     Lamp On
10     Reserved
11     Not available";
CM_ SG_ 2566739966 ProtectLampStatus "This lamp is used to relay trouble code information that is reporting a problem with a vehicle system that is most probably not electronic subsystem related. For instance, engine coolant temperature is exceeding its prescribed temperature range.
00 ...";
CM_ SG_ 2566739966 DTC5 "Diagnostic Trouble Code";
CM_ SG_ 2566739966 DTC4 "Diagnostic Trouble Code";
CM_ SG_ 2566739966 DTC3 "Diagnostic Trouble Code";
CM_ SG_ 2566739966 DTC2 "Diagnostic Trouble Code";
CM_ SG_ 2566739966 DTC1 "Diagnostic Trouble Code";
CM_ BO_ 2566740222 "DTCs - B2, Confirmed and Active
Confirmed and Active DTCs that are classified as class B2 severity.";
CM_ SG_ 2566740222 FlashRedStopLamp "This parameter provides the capability to flash the RSL


00 - Slow Flash (1 Hz, 50 % duty cycle)
01 - Fast Flash (2 Hz or faster, 50% duty cycle)
10 - Reserved
11 - Unavailable / Do Not Flash";
CM_ SG_ 2566740222 FlashProtectLamp "This parameter provides the capability to flash the engine protect lamp


00 - Slow Flash (1 Hz, 50 % duty cycle)
01 - Fast Flash (2 Hz or faster, 50% duty cycle)
10 - Reserved
11 - Unavailable / Do Not Flash";
CM_ SG_ 2566740222 FlashMalfuncIndicatorLamp "This parameter provides the capability to flash the MIL
00 - Slow Flash (1 Hz, 50 % duty cycle)
01 - Fast Flash (2 Hz or faster, 50% duty cycle)
10 - Class C DTC
11 - Unavailable / Do Not Flash
Note:  State 10 is for WWH OBD discriminatory ...";
CM_ SG_ 2566740222 FlashAmberWarningLamp "This parameter provides the capability to flash the AWL

00 - Slow Flash (1 Hz, 50 % duty cycle)
01 - Fast Flash (2 Hz or faster, 50% duty cycle)
10 - Reserved
11 - Unavailable / Do Not Flash";
CM_ SG_ 2566740222 MalfunctionIndicatorLampStatus "A lamp used to relay only emissions-related trouble code information. This lamp is only illuminated when there is an emission-related trouble code active.
00     Lamp Off
01     Lamp On
10     Short MIL for WWH OBD
11     Not available
Note ...";
CM_ SG_ 2566740222 AmberWarningLampStatus "This lamp is used to relay trouble code information that is reporting a problem with the vehicle system but the vehicle need not be immediately stopped. 

00     Lamp Off
01     Lamp On
10     Reserved
11     Not available";
CM_ SG_ 2566740222 RedStopLampState "This lamp is used to relay trouble code information that is of a severe enough condition that it warrants stopping the vehicle.

00     Lamp Off
01     Lamp On
10     Reserved
11     Not available";
CM_ SG_ 2566740222 ProtectLampStatus "This lamp is used to relay trouble code information that is reporting a problem with a vehicle system that is most probably not electronic subsystem related. For instance, engine coolant temperature is exceeding its prescribed temperature range.
00 ...";
CM_ SG_ 2566740222 DTC5 "Diagnostic Trouble Code";
CM_ SG_ 2566740222 DTC4 "Diagnostic Trouble Code";
CM_ SG_ 2566740222 DTC3 "Diagnostic Trouble Code";
CM_ SG_ 2566740222 DTC2 "Diagnostic Trouble Code";
CM_ SG_ 2566740222 DTC1 "Diagnostic Trouble Code";
CM_ BO_ 2566740478 "DTCs - B2, Pending
Pending DTCs that are classified as class B2 severity.";
CM_ SG_ 2566740478 FlashRedStopLamp "This parameter provides the capability to flash the RSL


00 - Slow Flash (1 Hz, 50 % duty cycle)
01 - Fast Flash (2 Hz or faster, 50% duty cycle)
10 - Reserved
11 - Unavailable / Do Not Flash";
CM_ SG_ 2566740478 FlashProtectLamp "This parameter provides the capability to flash the engine protect lamp


00 - Slow Flash (1 Hz, 50 % duty cycle)
01 - Fast Flash (2 Hz or faster, 50% duty cycle)
10 - Reserved
11 - Unavailable / Do Not Flash";
CM_ SG_ 2566740478 FlashMalfuncIndicatorLamp "This parameter provides the capability to flash the MIL
00 - Slow Flash (1 Hz, 50 % duty cycle)
01 - Fast Flash (2 Hz or faster, 50% duty cycle)
10 - Class C DTC
11 - Unavailable / Do Not Flash
Note:  State 10 is for WWH OBD discriminatory ...";
CM_ SG_ 2566740478 FlashAmberWarningLamp "This parameter provides the capability to flash the AWL

00 - Slow Flash (1 Hz, 50 % duty cycle)
01 - Fast Flash (2 Hz or faster, 50% duty cycle)
10 - Reserved
11 - Unavailable / Do Not Flash";
CM_ SG_ 2566740478 MalfunctionIndicatorLampStatus "A lamp used to relay only emissions-related trouble code information. This lamp is only illuminated when there is an emission-related trouble code active.
00     Lamp Off
01     Lamp On
10     Short MIL for WWH OBD
11     Not available
Note ...";
CM_ SG_ 2566740478 AmberWarningLampStatus "This lamp is used to relay trouble code information that is reporting a problem with the vehicle system but the vehicle need not be immediately stopped. 

00     Lamp Off
01     Lamp On
10     Reserved
11     Not available";
CM_ SG_ 2566740478 RedStopLampState "This lamp is used to relay trouble code information that is of a severe enough condition that it warrants stopping the vehicle.

00     Lamp Off
01     Lamp On
10     Reserved
11     Not available";
CM_ SG_ 2566740478 ProtectLampStatus "This lamp is used to relay trouble code information that is reporting a problem with a vehicle system that is most probably not electronic subsystem related. For instance, engine coolant temperature is exceeding its prescribed temperature range.
00 ...";
CM_ SG_ 2566740478 DTC5 "Diagnostic Trouble Code";
CM_ SG_ 2566740478 DTC4 "Diagnostic Trouble Code";
CM_ SG_ 2566740478 DTC3 "Diagnostic Trouble Code";
CM_ SG_ 2566740478 DTC2 "Diagnostic Trouble Code";
CM_ SG_ 2566740478 DTC1 "Diagnostic Trouble Code";
CM_ BO_ 2566740734 "DTCs - B1, Previously Active
Previously Active DTCs that are classified as class B1 severity.";
CM_ SG_ 2566740734 FlashRedStopLamp "This parameter provides the capability to flash the RSL


00 - Slow Flash (1 Hz, 50 % duty cycle)
01 - Fast Flash (2 Hz or faster, 50% duty cycle)
10 - Reserved
11 - Unavailable / Do Not Flash";
CM_ SG_ 2566740734 FlashProtectLamp "This parameter provides the capability to flash the engine protect lamp


00 - Slow Flash (1 Hz, 50 % duty cycle)
01 - Fast Flash (2 Hz or faster, 50% duty cycle)
10 - Reserved
11 - Unavailable / Do Not Flash";
CM_ SG_ 2566740734 FlashMalfuncIndicatorLamp "This parameter provides the capability to flash the MIL
00 - Slow Flash (1 Hz, 50 % duty cycle)
01 - Fast Flash (2 Hz or faster, 50% duty cycle)
10 - Class C DTC
11 - Unavailable / Do Not Flash
Note:  State 10 is for WWH OBD discriminatory ...";
CM_ SG_ 2566740734 FlashAmberWarningLamp "This parameter provides the capability to flash the AWL

00 - Slow Flash (1 Hz, 50 % duty cycle)
01 - Fast Flash (2 Hz or faster, 50% duty cycle)
10 - Reserved
11 - Unavailable / Do Not Flash";
CM_ SG_ 2566740734 MalfunctionIndicatorLampStatus "A lamp used to relay only emissions-related trouble code information. This lamp is only illuminated when there is an emission-related trouble code active.
00     Lamp Off
01     Lamp On
10     Short MIL for WWH OBD
11     Not available
Note ...";
CM_ SG_ 2566740734 AmberWarningLampStatus "This lamp is used to relay trouble code information that is reporting a problem with the vehicle system but the vehicle need not be immediately stopped. 

00     Lamp Off
01     Lamp On
10     Reserved
11     Not available";
CM_ SG_ 2566740734 RedStopLampState "This lamp is used to relay trouble code information that is of a severe enough condition that it warrants stopping the vehicle.

00     Lamp Off
01     Lamp On
10     Reserved
11     Not available";
CM_ SG_ 2566740734 ProtectLampStatus "This lamp is used to relay trouble code information that is reporting a problem with a vehicle system that is most probably not electronic subsystem related. For instance, engine coolant temperature is exceeding its prescribed temperature range.
00 ...";
CM_ SG_ 2566740734 DTC5 "Diagnostic Trouble Code";
CM_ SG_ 2566740734 DTC4 "Diagnostic Trouble Code";
CM_ SG_ 2566740734 DTC3 "Diagnostic Trouble Code";
CM_ SG_ 2566740734 DTC2 "Diagnostic Trouble Code";
CM_ SG_ 2566740734 DTC1 "Diagnostic Trouble Code";
CM_ BO_ 2566740990 "DTCs - B1, Confirmed and Active
Confirmed and Active DTCs that are classified as class B1 severity.";
CM_ SG_ 2566740990 FlashRedStopLamp "This parameter provides the capability to flash the RSL


00 - Slow Flash (1 Hz, 50 % duty cycle)
01 - Fast Flash (2 Hz or faster, 50% duty cycle)
10 - Reserved
11 - Unavailable / Do Not Flash";
CM_ SG_ 2566740990 FlashProtectLamp "This parameter provides the capability to flash the engine protect lamp


00 - Slow Flash (1 Hz, 50 % duty cycle)
01 - Fast Flash (2 Hz or faster, 50% duty cycle)
10 - Reserved
11 - Unavailable / Do Not Flash";
CM_ SG_ 2566740990 FlashMalfuncIndicatorLamp "This parameter provides the capability to flash the MIL
00 - Slow Flash (1 Hz, 50 % duty cycle)
01 - Fast Flash (2 Hz or faster, 50% duty cycle)
10 - Class C DTC
11 - Unavailable / Do Not Flash
Note:  State 10 is for WWH OBD discriminatory ...";
CM_ SG_ 2566740990 FlashAmberWarningLamp "This parameter provides the capability to flash the AWL

00 - Slow Flash (1 Hz, 50 % duty cycle)
01 - Fast Flash (2 Hz or faster, 50% duty cycle)
10 - Reserved
11 - Unavailable / Do Not Flash";
CM_ SG_ 2566740990 MalfunctionIndicatorLampStatus "A lamp used to relay only emissions-related trouble code information. This lamp is only illuminated when there is an emission-related trouble code active.
00     Lamp Off
01     Lamp On
10     Short MIL for WWH OBD
11     Not available
Note ...";
CM_ SG_ 2566740990 AmberWarningLampStatus "This lamp is used to relay trouble code information that is reporting a problem with the vehicle system but the vehicle need not be immediately stopped. 

00     Lamp Off
01     Lamp On
10     Reserved
11     Not available";
CM_ SG_ 2566740990 RedStopLampState "This lamp is used to relay trouble code information that is of a severe enough condition that it warrants stopping the vehicle.

00     Lamp Off
01     Lamp On
10     Reserved
11     Not available";
CM_ SG_ 2566740990 ProtectLampStatus "This lamp is used to relay trouble code information that is reporting a problem with a vehicle system that is most probably not electronic subsystem related. For instance, engine coolant temperature is exceeding its prescribed temperature range.
00 ...";
CM_ SG_ 2566740990 DTC5 "Diagnostic Trouble Code";
CM_ SG_ 2566740990 DTC4 "Diagnostic Trouble Code";
CM_ SG_ 2566740990 DTC3 "Diagnostic Trouble Code";
CM_ SG_ 2566740990 DTC2 "Diagnostic Trouble Code";
CM_ SG_ 2566740990 DTC1 "Diagnostic Trouble Code";
CM_ BO_ 2566741246 "DTCs - B1, Pending
Pending DTCs that are classified as class B1 severity.";
CM_ SG_ 2566741246 FlashRedStopLamp "This parameter provides the capability to flash the RSL


00 - Slow Flash (1 Hz, 50 % duty cycle)
01 - Fast Flash (2 Hz or faster, 50% duty cycle)
10 - Reserved
11 - Unavailable / Do Not Flash";
CM_ SG_ 2566741246 FlashProtectLamp "This parameter provides the capability to flash the engine protect lamp


00 - Slow Flash (1 Hz, 50 % duty cycle)
01 - Fast Flash (2 Hz or faster, 50% duty cycle)
10 - Reserved
11 - Unavailable / Do Not Flash";
CM_ SG_ 2566741246 FlashMalfuncIndicatorLamp "This parameter provides the capability to flash the MIL
00 - Slow Flash (1 Hz, 50 % duty cycle)
01 - Fast Flash (2 Hz or faster, 50% duty cycle)
10 - Class C DTC
11 - Unavailable / Do Not Flash
Note:  State 10 is for WWH OBD discriminatory ...";
CM_ SG_ 2566741246 FlashAmberWarningLamp "This parameter provides the capability to flash the AWL

00 - Slow Flash (1 Hz, 50 % duty cycle)
01 - Fast Flash (2 Hz or faster, 50% duty cycle)
10 - Reserved
11 - Unavailable / Do Not Flash";
CM_ SG_ 2566741246 MalfunctionIndicatorLampStatus "A lamp used to relay only emissions-related trouble code information. This lamp is only illuminated when there is an emission-related trouble code active.
00     Lamp Off
01     Lamp On
10     Short MIL for WWH OBD
11     Not available
Note ...";
CM_ SG_ 2566741246 AmberWarningLampStatus "This lamp is used to relay trouble code information that is reporting a problem with the vehicle system but the vehicle need not be immediately stopped. 

00     Lamp Off
01     Lamp On
10     Reserved
11     Not available";
CM_ SG_ 2566741246 RedStopLampState "This lamp is used to relay trouble code information that is of a severe enough condition that it warrants stopping the vehicle.

00     Lamp Off
01     Lamp On
10     Reserved
11     Not available";
CM_ SG_ 2566741246 ProtectLampStatus "This lamp is used to relay trouble code information that is reporting a problem with a vehicle system that is most probably not electronic subsystem related. For instance, engine coolant temperature is exceeding its prescribed temperature range.
00 ...";
CM_ SG_ 2566741246 DTC5 "Diagnostic Trouble Code";
CM_ SG_ 2566741246 DTC4 "Diagnostic Trouble Code";
CM_ SG_ 2566741246 DTC3 "Diagnostic Trouble Code";
CM_ SG_ 2566741246 DTC2 "Diagnostic Trouble Code";
CM_ SG_ 2566741246 DTC1 "Diagnostic Trouble Code";
CM_ BO_ 2566741502 "DTCs - A, Previously Active
Previously Active DTCs that are classified as class A severity.";
CM_ SG_ 2566741502 FlashRedStopLamp "This parameter provides the capability to flash the RSL


00 - Slow Flash (1 Hz, 50 % duty cycle)
01 - Fast Flash (2 Hz or faster, 50% duty cycle)
10 - Reserved
11 - Unavailable / Do Not Flash";
CM_ SG_ 2566741502 FlashProtectLamp "This parameter provides the capability to flash the engine protect lamp


00 - Slow Flash (1 Hz, 50 % duty cycle)
01 - Fast Flash (2 Hz or faster, 50% duty cycle)
10 - Reserved
11 - Unavailable / Do Not Flash";
CM_ SG_ 2566741502 FlashMalfuncIndicatorLamp "This parameter provides the capability to flash the MIL
00 - Slow Flash (1 Hz, 50 % duty cycle)
01 - Fast Flash (2 Hz or faster, 50% duty cycle)
10 - Class C DTC
11 - Unavailable / Do Not Flash
Note:  State 10 is for WWH OBD discriminatory ...";
CM_ SG_ 2566741502 FlashAmberWarningLamp "This parameter provides the capability to flash the AWL

00 - Slow Flash (1 Hz, 50 % duty cycle)
01 - Fast Flash (2 Hz or faster, 50% duty cycle)
10 - Reserved
11 - Unavailable / Do Not Flash";
CM_ SG_ 2566741502 MalfunctionIndicatorLampStatus "A lamp used to relay only emissions-related trouble code information. This lamp is only illuminated when there is an emission-related trouble code active.
00     Lamp Off
01     Lamp On
10     Short MIL for WWH OBD
11     Not available
Note ...";
CM_ SG_ 2566741502 AmberWarningLampStatus "This lamp is used to relay trouble code information that is reporting a problem with the vehicle system but the vehicle need not be immediately stopped. 

00     Lamp Off
01     Lamp On
10     Reserved
11     Not available";
CM_ SG_ 2566741502 RedStopLampState "This lamp is used to relay trouble code information that is of a severe enough condition that it warrants stopping the vehicle.

00     Lamp Off
01     Lamp On
10     Reserved
11     Not available";
CM_ SG_ 2566741502 ProtectLampStatus "This lamp is used to relay trouble code information that is reporting a problem with a vehicle system that is most probably not electronic subsystem related. For instance, engine coolant temperature is exceeding its prescribed temperature range.
00 ...";
CM_ SG_ 2566741502 DTC5 "Diagnostic Trouble Code";
CM_ SG_ 2566741502 DTC4 "Diagnostic Trouble Code";
CM_ SG_ 2566741502 DTC3 "Diagnostic Trouble Code";
CM_ SG_ 2566741502 DTC2 "Diagnostic Trouble Code";
CM_ SG_ 2566741502 DTC1 "Diagnostic Trouble Code";
CM_ BO_ 2566741758 "DTCs - A, Confirmed and Active
Confirmed and Active DTCs that are classified as class A severity.";
CM_ SG_ 2566741758 FlashRedStopLamp "This parameter provides the capability to flash the RSL


00 - Slow Flash (1 Hz, 50 % duty cycle)
01 - Fast Flash (2 Hz or faster, 50% duty cycle)
10 - Reserved
11 - Unavailable / Do Not Flash";
CM_ SG_ 2566741758 FlashProtectLamp "This parameter provides the capability to flash the engine protect lamp


00 - Slow Flash (1 Hz, 50 % duty cycle)
01 - Fast Flash (2 Hz or faster, 50% duty cycle)
10 - Reserved
11 - Unavailable / Do Not Flash";
CM_ SG_ 2566741758 FlashMalfuncIndicatorLamp "This parameter provides the capability to flash the MIL
00 - Slow Flash (1 Hz, 50 % duty cycle)
01 - Fast Flash (2 Hz or faster, 50% duty cycle)
10 - Class C DTC
11 - Unavailable / Do Not Flash
Note:  State 10 is for WWH OBD discriminatory ...";
CM_ SG_ 2566741758 FlashAmberWarningLamp "This parameter provides the capability to flash the AWL

00 - Slow Flash (1 Hz, 50 % duty cycle)
01 - Fast Flash (2 Hz or faster, 50% duty cycle)
10 - Reserved
11 - Unavailable / Do Not Flash";
CM_ SG_ 2566741758 MalfunctionIndicatorLampStatus "A lamp used to relay only emissions-related trouble code information. This lamp is only illuminated when there is an emission-related trouble code active.
00     Lamp Off
01     Lamp On
10     Short MIL for WWH OBD
11     Not available
Note ...";
CM_ SG_ 2566741758 AmberWarningLampStatus "This lamp is used to relay trouble code information that is reporting a problem with the vehicle system but the vehicle need not be immediately stopped. 

00     Lamp Off
01     Lamp On
10     Reserved
11     Not available";
CM_ SG_ 2566741758 RedStopLampState "This lamp is used to relay trouble code information that is of a severe enough condition that it warrants stopping the vehicle.

00     Lamp Off
01     Lamp On
10     Reserved
11     Not available";
CM_ SG_ 2566741758 ProtectLampStatus "This lamp is used to relay trouble code information that is reporting a problem with a vehicle system that is most probably not electronic subsystem related. For instance, engine coolant temperature is exceeding its prescribed temperature range.
00 ...";
CM_ SG_ 2566741758 DTC5 "Diagnostic Trouble Code";
CM_ SG_ 2566741758 DTC4 "Diagnostic Trouble Code";
CM_ SG_ 2566741758 DTC3 "Diagnostic Trouble Code";
CM_ SG_ 2566741758 DTC2 "Diagnostic Trouble Code";
CM_ SG_ 2566741758 DTC1 "Diagnostic Trouble Code";
BA_DEF_ SG_  "SigType" ENUM  "Default","Range","RangeSigned","ASCII","Discrete","Control","ReferencePGN","DTC","StringDelimiter","StringLength","StringLengthControl","MessageCounter","MessageChecksum";
BA_DEF_ SG_  "GenSigStartValue" INT 0 2147483647;
BA_DEF_ SG_  "GenSigSendType" ENUM  "Cyclic","OnWrite","OnWriteWithRepetition","OnChange","OnChangeWithRepetition","IfActive","IfActiveWithRepetition","NoSigSendType";
BA_DEF_ SG_  "GenSigILSupport" ENUM  "No","Yes";
BA_DEF_ SG_  "GenSigEVName" STRING ;
BA_DEF_ SG_  "SPN" INT 0 524287;
BA_DEF_ BO_  "TpJ1939VarDlc" ENUM  "No","Yes";
BA_DEF_ BO_  "GenMsgStartDelayTime" INT 0 100000;
BA_DEF_ BO_  "GenMsgILSupport" ENUM  "No","Yes";
BA_DEF_ BO_  "GenMsgDelayTime" INT 0 1000;
BA_DEF_ BO_  "GenMsgRequestable" INT 0 1;
BA_DEF_ BO_  "GenMsgSendType" ENUM  "cyclic","NotUsed","NotUsed","NotUsed","NotUsed","NotUsed","NotUsed","IfActive","noMsgSendType";
BA_DEF_ BO_  "VFrameFormat" ENUM  "StandardCAN","ExtendedCAN","reserved","J1939PG";
BA_DEF_ BO_  "GenMsgCycleTime" INT 0 3600000;
BA_DEF_ SG_  "SystemSignalLongSymbol" STRING ;
BA_DEF_DEF_  "SigType" "Default";
BA_DEF_DEF_  "GenSigStartValue" 0;
BA_DEF_DEF_  "GenSigSendType" "NoSigSendType";
BA_DEF_DEF_  "GenSigILSupport" "Yes";
BA_DEF_DEF_  "GenSigEVName" "Env@Nodename_@Signame";
BA_DEF_DEF_  "SPN" 0;
BA_DEF_DEF_  "TpJ1939VarDlc" "No";
BA_DEF_DEF_  "GenMsgStartDelayTime" 0;
BA_DEF_DEF_  "GenMsgILSupport" "Yes";
BA_DEF_DEF_  "GenMsgDelayTime" 0;
BA_DEF_DEF_  "GenMsgRequestable" 1;
BA_DEF_DEF_  "GenMsgSendType" "noMsgSendType";
BA_DEF_DEF_  "VFrameFormat" "J1939PG";
BA_DEF_DEF_  "GenMsgCycleTime" 0;
BA_DEF_DEF_  "SystemSignalLongSymbol" "";
BA_ "TpJ1939VarDlc" BO_ 2566834942 1;
BA_ "GenMsgCycleTime" BO_ 2365454334 100;
BA_ "GenMsgSendType" BO_ 2365454334 0;
BA_ "GenMsgCycleTime" BO_ 2365454590 100;
BA_ "GenMsgSendType" BO_ 2365454590 0;
BA_ "GenMsgCycleTime" BO_ 2365451774 100;
BA_ "GenMsgSendType" BO_ 2365451774 0;
BA_ "GenMsgCycleTime" BO_ 2365452030 100;
BA_ "GenMsgSendType" BO_ 2365452030 0;
BA_ "GenMsgCycleTime" BO_ 2365452286 100;
BA_ "GenMsgSendType" BO_ 2365452286 0;
BA_ "GenMsgCycleTime" BO_ 2365452542 100;
BA_ "GenMsgSendType" BO_ 2365452542 0;
BA_ "GenMsgCycleTime" BO_ 2365452798 100;
BA_ "GenMsgSendType" BO_ 2365452798 0;
BA_ "GenMsgCycleTime" BO_ 2365453054 100;
BA_ "GenMsgSendType" BO_ 2365453054 0;
BA_ "GenMsgCycleTime" BO_ 2365453310 100;
BA_ "GenMsgSendType" BO_ 2365453310 0;
BA_ "GenMsgCycleTime" BO_ 2365453566 100;
BA_ "GenMsgSendType" BO_ 2365453566 0;
BA_ "GenMsgCycleTime" BO_ 2365453822 100;
BA_ "GenMsgSendType" BO_ 2365453822 0;
BA_ "GenMsgCycleTime" BO_ 2365454078 100;
BA_ "GenMsgSendType" BO_ 2365454078 0;
BA_ "GenMsgCycleTime" BO_ 2365454846 100;
BA_ "GenMsgSendType" BO_ 2365454846 0;
BA_ "GenMsgCycleTime" BO_ 2365457662 100;
BA_ "GenMsgSendType" BO_ 2365457662 0;
BA_ "GenMsgCycleTime" BO_ 2365457918 100;
BA_ "GenMsgSendType" BO_ 2365457918 0;
BA_ "GenMsgCycleTime" BO_ 2365455102 100;
BA_ "GenMsgSendType" BO_ 2365455102 0;
BA_ "GenMsgCycleTime" BO_ 2365455358 100;
BA_ "GenMsgSendType" BO_ 2365455358 0;
BA_ "GenMsgCycleTime" BO_ 2365455614 100;
BA_ "GenMsgSendType" BO_ 2365455614 0;
BA_ "GenMsgCycleTime" BO_ 2365455870 100;
BA_ "GenMsgSendType" BO_ 2365455870 0;
BA_ "GenMsgCycleTime" BO_ 2365456126 100;
BA_ "GenMsgSendType" BO_ 2365456126 0;
BA_ "GenMsgCycleTime" BO_ 2365456382 100;
BA_ "GenMsgSendType" BO_ 2365456382 0;
BA_ "GenMsgCycleTime" BO_ 2365456638 100;
BA_ "GenMsgSendType" BO_ 2365456638 0;
BA_ "GenMsgCycleTime" BO_ 2365456894 100;
BA_ "GenMsgSendType" BO_ 2365456894 0;
BA_ "GenMsgCycleTime" BO_ 2365457150 100;
BA_ "GenMsgSendType" BO_ 2365457150 0;
BA_ "GenMsgCycleTime" BO_ 2365457406 100;
BA_ "GenMsgSendType" BO_ 2365457406 0;
BA_ "GenMsgCycleTime" BO_ 2365458174 100;
BA_ "GenMsgSendType" BO_ 2365458174 0;
BA_ "GenMsgCycleTime" BO_ 2365450238 100;
BA_ "GenMsgSendType" BO_ 2365450238 0;
BA_ "GenMsgCycleTime" BO_ 2365450750 100;
BA_ "GenMsgSendType" BO_ 2365450750 0;
BA_ "GenMsgCycleTime" BO_ 2365451006 100;
BA_ "GenMsgSendType" BO_ 2365451006 0;
BA_ "GenMsgCycleTime" BO_ 2365451262 100;
BA_ "GenMsgSendType" BO_ 2365451262 0;
BA_ "GenMsgCycleTime" BO_ 2365450494 100;
BA_ "GenMsgSendType" BO_ 2365450494 0;
BA_ "GenMsgCycleTime" BO_ 2365451518 100;
BA_ "GenMsgSendType" BO_ 2365451518 0;
BA_ "GenMsgRequestable" BO_ 2566838526 0;
BA_ "GenMsgRequestable" BO_ 2565603070 0;
BA_ "GenMsgRequestable" BO_ 2565668606 0;
BA_ "GenMsgRequestable" BO_ 2563374846 0;
BA_ "GenMsgRequestable" BO_ 2565537534 0;
BA_ "GenMsgCycleTime" BO_ 2432520702 1000;
BA_ "GenMsgSendType" BO_ 2432520702 0;
BA_ "TpJ1939VarDlc" BO_ 2566739198 1;
BA_ "TpJ1939VarDlc" BO_ 2566739454 1;
BA_ "TpJ1939VarDlc" BO_ 2566739710 1;
BA_ "TpJ1939VarDlc" BO_ 2566739966 1;
BA_ "TpJ1939VarDlc" BO_ 2566740222 1;
BA_ "TpJ1939VarDlc" BO_ 2566740478 1;
BA_ "TpJ1939VarDlc" BO_ 2566740734 1;
BA_ "TpJ1939VarDlc" BO_ 2566740990 1;
BA_ "TpJ1939VarDlc" BO_ 2566741246 1;
BA_ "TpJ1939VarDlc" BO_ 2566741502 1;
BA_ "TpJ1939VarDlc" BO_ 2566741758 1;
BA_ "SPN" SG_ 2566834942 FlashRedStopLamp 3039;
BA_ "SigType" SG_ 2566834942 FlashRedStopLamp 5;
BA_ "SPN" SG_ 2566834942 FlashProtectLamp 3041;
BA_ "SigType" SG_ 2566834942 FlashProtectLamp 5;
BA_ "SPN" SG_ 2566834942 FlashMalfuncIndicatorLamp 3038;
BA_ "SigType" SG_ 2566834942 FlashMalfuncIndicatorLamp 5;
BA_ "SPN" SG_ 2566834942 FlashAmberWarningLamp 3040;
BA_ "SigType" SG_ 2566834942 FlashAmberWarningLamp 5;
BA_ "SPN" SG_ 2566834942 MalfunctionIndicatorLampStatus 1213;
BA_ "SigType" SG_ 2566834942 MalfunctionIndicatorLampStatus 5;
BA_ "SPN" SG_ 2566834942 AmberWarningLampStatus 624;
BA_ "SigType" SG_ 2566834942 AmberWarningLampStatus 5;
BA_ "SPN" SG_ 2566834942 RedStopLampState 623;
BA_ "SigType" SG_ 2566834942 RedStopLampState 4;
BA_ "SPN" SG_ 2566834942 ProtectLampStatus 987;
BA_ "SigType" SG_ 2566834942 ProtectLampStatus 5;
BA_ "SigType" SG_ 2566834942 DTC5 7;
BA_ "SigType" SG_ 2566834942 DTC4 7;
BA_ "SigType" SG_ 2566834942 DTC3 7;
BA_ "SigType" SG_ 2566834942 DTC2 7;
BA_ "SigType" SG_ 2566834942 DTC1 7;
BA_ "SPN" SG_ 2365454334 UtlityOverallPowerFactorLagging 2522;
BA_ "SigType" SG_ 2365454334 UtlityOverallPowerFactorLagging 4;
BA_ "SPN" SG_ 2365454334 UtilityOverallPowerFactor 2498;
BA_ "SigType" SG_ 2365454334 UtilityOverallPowerFactor 1;
BA_ "SPN" SG_ 2365454334 UtilityTotalReactivePower 2490;
BA_ "SigType" SG_ 2365454334 UtilityTotalReactivePower 1;
BA_ "SPN" SG_ 2365454590 UtilityTotalApparentPower 2494;
BA_ "SigType" SG_ 2365454590 UtilityTotalApparentPower 1;
BA_ "SPN" SG_ 2365454590 UtilityTotalRealPower 2486;
BA_ "SigType" SG_ 2365454590 UtilityTotalRealPower 1;
BA_ "SPN" SG_ 2365451774 UtilityTotalKWHoursImport 2503;
BA_ "SigType" SG_ 2365451774 UtilityTotalKWHoursImport 1;
BA_ "SPN" SG_ 2365451774 UtilityTotalKWHoursExport 2502;
BA_ "SigType" SG_ 2365451774 UtilityTotalKWHoursExport 1;
BA_ "SPN" SG_ 2365452030 UtilityPhaseCPowerFactorLagging 2525;
BA_ "SigType" SG_ 2365452030 UtilityPhaseCPowerFactorLagging 4;
BA_ "SPN" SG_ 2365452030 UtilityPhaseCPowerFactor 2501;
BA_ "SigType" SG_ 2365452030 UtilityPhaseCPowerFactor 1;
BA_ "SPN" SG_ 2365452030 UtilityPhaseCReactivePower 2493;
BA_ "SigType" SG_ 2365452030 UtilityPhaseCReactivePower 1;
BA_ "SPN" SG_ 2365452286 UtilityPhaseCApparentPower 2497;
BA_ "SigType" SG_ 2365452286 UtilityPhaseCApparentPower 1;
BA_ "SPN" SG_ 2365452286 UtilityPhaseCRealPower 2489;
BA_ "SigType" SG_ 2365452286 UtilityPhaseCRealPower 1;
BA_ "SPN" SG_ 2365452542 UtilityPhaseCACRMSCurrent 2485;
BA_ "SigType" SG_ 2365452542 UtilityPhaseCACRMSCurrent 1;
BA_ "SPN" SG_ 2365452542 UtilityPhaseCACFrequency 2473;
BA_ "SigType" SG_ 2365452542 UtilityPhaseCACFrequency 1;
BA_ "SPN" SG_ 2365452542 UtltyPhsCLneNeutralACRMSVoltage 2481;
BA_ "SigType" SG_ 2365452542 UtltyPhsCLneNeutralACRMSVoltage 1;
BA_ "SPN" SG_ 2365452542 UtltyPhseCALineLineACRMSVoltage 2477;
BA_ "SigType" SG_ 2365452542 UtltyPhseCALineLineACRMSVoltage 1;
BA_ "SPN" SG_ 2365452798 UtilityPhaseBPowerFactorLagging 2524;
BA_ "SigType" SG_ 2365452798 UtilityPhaseBPowerFactorLagging 4;
BA_ "SPN" SG_ 2365452798 UtilityPhaseBPowerFactor 2500;
BA_ "SigType" SG_ 2365452798 UtilityPhaseBPowerFactor 1;
BA_ "SPN" SG_ 2365452798 UtilityPhaseBReactivePower 2492;
BA_ "SigType" SG_ 2365452798 UtilityPhaseBReactivePower 1;
BA_ "SPN" SG_ 2365453054 UtilityPhaseBApparentPower 2496;
BA_ "SigType" SG_ 2365453054 UtilityPhaseBApparentPower 1;
BA_ "SPN" SG_ 2365453054 UtilityPhaseBRealPower 2488;
BA_ "SigType" SG_ 2365453054 UtilityPhaseBRealPower 1;
BA_ "SPN" SG_ 2365453310 UtilityPhaseBACRMSCurrent 2484;
BA_ "SigType" SG_ 2365453310 UtilityPhaseBACRMSCurrent 1;
BA_ "SPN" SG_ 2365453310 UtilityPhaseBACFrequency 2472;
BA_ "SigType" SG_ 2365453310 UtilityPhaseBACFrequency 1;
BA_ "SPN" SG_ 2365453310 UtltyPhsBLneNeutralACRMSVoltage 2480;
BA_ "SigType" SG_ 2365453310 UtltyPhsBLneNeutralACRMSVoltage 1;
BA_ "SPN" SG_ 2365453310 UtltyPhseBCLineLineACRMSVoltage 2476;
BA_ "SigType" SG_ 2365453310 UtltyPhseBCLineLineACRMSVoltage 1;
BA_ "SPN" SG_ 2365453566 UtilityPhaseAPowerFactorLagging 2523;
BA_ "SigType" SG_ 2365453566 UtilityPhaseAPowerFactorLagging 4;
BA_ "SPN" SG_ 2365453566 UtilityPhaseAPowerFactor 2499;
BA_ "SigType" SG_ 2365453566 UtilityPhaseAPowerFactor 1;
BA_ "SPN" SG_ 2365453566 UtilityPhaseAReactivePower 2491;
BA_ "SigType" SG_ 2365453566 UtilityPhaseAReactivePower 1;
BA_ "SPN" SG_ 2365453822 UtilityPhaseAApparentPower 2495;
BA_ "SigType" SG_ 2365453822 UtilityPhaseAApparentPower 1;
BA_ "SPN" SG_ 2365453822 UtilityPhaseARealPower 2487;
BA_ "SigType" SG_ 2365453822 UtilityPhaseARealPower 1;
BA_ "SPN" SG_ 2365454078 UtilityPhaseAACRMSCurrent 2483;
BA_ "SigType" SG_ 2365454078 UtilityPhaseAACRMSCurrent 1;
BA_ "SPN" SG_ 2365454078 UtilityPhaseAACFrequency 2471;
BA_ "SigType" SG_ 2365454078 UtilityPhaseAACFrequency 1;
BA_ "SPN" SG_ 2365454078 UtltyPhsALneNeutralACRMSVoltage 2479;
BA_ "SigType" SG_ 2365454078 UtltyPhsALneNeutralACRMSVoltage 1;
BA_ "SPN" SG_ 2365454078 UtltyPhseABLineLineACRMSVoltage 2475;
BA_ "SigType" SG_ 2365454078 UtltyPhseABLineLineACRMSVoltage 1;
BA_ "SPN" SG_ 2365454846 UtilityAverageACRMSCurrent 2482;
BA_ "SigType" SG_ 2365454846 UtilityAverageACRMSCurrent 1;
BA_ "SPN" SG_ 2365454846 UtilityAverageACFrequency 2470;
BA_ "SigType" SG_ 2365454846 UtilityAverageACFrequency 1;
BA_ "SPN" SG_ 2365454846 UtltyAvrgLneNeutralACRMSVoltage 2478;
BA_ "SigType" SG_ 2365454846 UtltyAvrgLneNeutralACRMSVoltage 1;
BA_ "SPN" SG_ 2365454846 UtltyAvrageLineLineACRMSVoltage 2474;
BA_ "SigType" SG_ 2365454846 UtltyAvrageLineLineACRMSVoltage 1;
BA_ "SPN" SG_ 2365457662 GnrtorOverallPowerFactorLagging 2518;
BA_ "SigType" SG_ 2365457662 GnrtorOverallPowerFactorLagging 4;
BA_ "SPN" SG_ 2365457662 GeneratorOverallPowerFactor 2464;
BA_ "SigType" SG_ 2365457662 GeneratorOverallPowerFactor 1;
BA_ "SPN" SG_ 2365457662 GeneratorTotalReactivePower 2456;
BA_ "SigType" SG_ 2365457662 GeneratorTotalReactivePower 1;
BA_ "SPN" SG_ 2365457918 GeneratorTotalApparentPower 2460;
BA_ "SigType" SG_ 2365457918 GeneratorTotalApparentPower 1;
BA_ "SPN" SG_ 2365457918 GeneratorTotalRealPower 2452;
BA_ "SigType" SG_ 2365457918 GeneratorTotalRealPower 1;
BA_ "SPN" SG_ 2365455102 GeneratorTotalKWHoursImport 2469;
BA_ "SigType" SG_ 2365455102 GeneratorTotalKWHoursImport 1;
BA_ "SPN" SG_ 2365455102 GeneratorTotalKWHoursExport 2468;
BA_ "SigType" SG_ 2365455102 GeneratorTotalKWHoursExport 1;
BA_ "SPN" SG_ 2365455358 GnratorPhaseCPowerFactorLagging 2521;
BA_ "SigType" SG_ 2365455358 GnratorPhaseCPowerFactorLagging 4;
BA_ "SPN" SG_ 2365455358 GeneratorPhaseCPowerFactor 2467;
BA_ "SigType" SG_ 2365455358 GeneratorPhaseCPowerFactor 1;
BA_ "SPN" SG_ 2365455358 GeneratorPhaseCReactivePower 2459;
BA_ "SigType" SG_ 2365455358 GeneratorPhaseCReactivePower 1;
BA_ "SPN" SG_ 2365455614 GeneratorPhaseCApparentPower 2463;
BA_ "SigType" SG_ 2365455614 GeneratorPhaseCApparentPower 1;
BA_ "SPN" SG_ 2365455614 GeneratorPhaseCRealPower 2455;
BA_ "SigType" SG_ 2365455614 GeneratorPhaseCRealPower 1;
BA_ "SPN" SG_ 2365455870 GeneratorPhaseCACRMSCurrent 2451;
BA_ "SigType" SG_ 2365455870 GeneratorPhaseCACRMSCurrent 1;
BA_ "SPN" SG_ 2365455870 GeneratorPhaseCACFrequency 2439;
BA_ "SigType" SG_ 2365455870 GeneratorPhaseCACFrequency 1;
BA_ "SPN" SG_ 2365455870 GnrtrPhsCLneNeutralACRMSVoltage 2447;
BA_ "SigType" SG_ 2365455870 GnrtrPhsCLneNeutralACRMSVoltage 1;
BA_ "SPN" SG_ 2365455870 GnrtrPhseCALineLineACRMSVoltage 2443;
BA_ "SigType" SG_ 2365455870 GnrtrPhseCALineLineACRMSVoltage 1;
BA_ "SPN" SG_ 2365456126 GnratorPhaseBPowerFactorLagging 2520;
BA_ "SigType" SG_ 2365456126 GnratorPhaseBPowerFactorLagging 4;
BA_ "SPN" SG_ 2365456126 GeneratorPhaseBPowerFactor 2466;
BA_ "SigType" SG_ 2365456126 GeneratorPhaseBPowerFactor 1;
BA_ "SPN" SG_ 2365456126 GeneratorPhaseBReactivePower 2458;
BA_ "SigType" SG_ 2365456126 GeneratorPhaseBReactivePower 1;
BA_ "SPN" SG_ 2365456382 GeneratorPhaseBApparentPower 2462;
BA_ "SigType" SG_ 2365456382 GeneratorPhaseBApparentPower 1;
BA_ "SPN" SG_ 2365456382 GeneratorPhaseBRealPower 2454;
BA_ "SigType" SG_ 2365456382 GeneratorPhaseBRealPower 1;
BA_ "SPN" SG_ 2365456638 GeneratorPhaseBACRMSCurrent 2450;
BA_ "SigType" SG_ 2365456638 GeneratorPhaseBACRMSCurrent 1;
BA_ "SPN" SG_ 2365456638 GeneratorPhaseBACFrequency 2438;
BA_ "SigType" SG_ 2365456638 GeneratorPhaseBACFrequency 1;
BA_ "SPN" SG_ 2365456638 GnrtrPhsBLneNeutralACRMSVoltage 2446;
BA_ "SigType" SG_ 2365456638 GnrtrPhsBLneNeutralACRMSVoltage 1;
BA_ "SPN" SG_ 2365456638 GnrtrPhseBCLineLineACRMSVoltage 2442;
BA_ "SigType" SG_ 2365456638 GnrtrPhseBCLineLineACRMSVoltage 1;
BA_ "SPN" SG_ 2365456894 GnratorPhaseAPowerFactorLagging 2519;
BA_ "SigType" SG_ 2365456894 GnratorPhaseAPowerFactorLagging 4;
BA_ "SPN" SG_ 2365456894 GeneratorPhaseAPowerFactor 2465;
BA_ "SigType" SG_ 2365456894 GeneratorPhaseAPowerFactor 1;
BA_ "SPN" SG_ 2365456894 GeneratorPhaseAReactivePower 2457;
BA_ "SigType" SG_ 2365456894 GeneratorPhaseAReactivePower 1;
BA_ "SPN" SG_ 2365457150 GeneratorPhaseAApparentPower 2461;
BA_ "SigType" SG_ 2365457150 GeneratorPhaseAApparentPower 1;
BA_ "SPN" SG_ 2365457150 GeneratorPhaseARealPower 2453;
BA_ "SigType" SG_ 2365457150 GeneratorPhaseARealPower 1;
BA_ "SPN" SG_ 2365457406 GeneratorPhaseAACRMSCurrent 2449;
BA_ "SigType" SG_ 2365457406 GeneratorPhaseAACRMSCurrent 1;
BA_ "SPN" SG_ 2365457406 GeneratorPhaseAACFrequency 2437;
BA_ "SigType" SG_ 2365457406 GeneratorPhaseAACFrequency 1;
BA_ "SPN" SG_ 2365457406 GnrtrPhsALneNeutralACRMSVoltage 2445;
BA_ "SigType" SG_ 2365457406 GnrtrPhsALneNeutralACRMSVoltage 1;
BA_ "SPN" SG_ 2365457406 GnrtrPhseABLineLineACRMSVoltage 2441;
BA_ "SigType" SG_ 2365457406 GnrtrPhseABLineLineACRMSVoltage 1;
BA_ "SPN" SG_ 2365458174 GeneratorAverageACRMSCurrent 2448;
BA_ "SigType" SG_ 2365458174 GeneratorAverageACRMSCurrent 1;
BA_ "SPN" SG_ 2365458174 GeneratorAverageACFrequency 2436;
BA_ "SigType" SG_ 2365458174 GeneratorAverageACFrequency 1;
BA_ "SPN" SG_ 2365458174 GnrtrAvrgLneNeutralACRMSVoltage 2444;
BA_ "SigType" SG_ 2365458174 GnrtrAvrgLneNeutralACRMSVoltage 1;
BA_ "SPN" SG_ 2365458174 GnrtrAvrageLineLineACRMSVoltage 2440;
BA_ "SigType" SG_ 2365458174 GnrtrAvrageLineLineACRMSVoltage 1;
BA_ "SPN" SG_ 2365450238 Bus1_UtilityACPhaseDifference 2517;
BA_ "SigType" SG_ 2365450238 Bus1_UtilityACPhaseDifference 1;
BA_ "SPN" SG_ 2365450238 Bus1_UtilityInSync 2534;
BA_ "SigType" SG_ 2365450238 Bus1_UtilityInSync 4;
BA_ "SPN" SG_ 2365450238 Bus1_UtilityVoltageMatch 2532;
BA_ "SigType" SG_ 2365450238 Bus1_UtilityVoltageMatch 4;
BA_ "SPN" SG_ 2365450238 Bus1_UtilityFrequencyMatch 2533;
BA_ "SigType" SG_ 2365450238 Bus1_UtilityFrequencyMatch 4;
BA_ "SPN" SG_ 2365450238 Bus1_UtilityPhaseMatch 2531;
BA_ "SigType" SG_ 2365450238 Bus1_UtilityPhaseMatch 4;
BA_ "SPN" SG_ 2365450238 Bus1_UtilityDeadBus 2535;
BA_ "SigType" SG_ 2365450238 Bus1_UtilityDeadBus 4;
BA_ "SPN" SG_ 2365450750 Bus1PhaseCACFrequency 2507;
BA_ "SigType" SG_ 2365450750 Bus1PhaseCACFrequency 1;
BA_ "SPN" SG_ 2365450750 Bs1PhseCLineNeutralACRMSVoltage 2515;
BA_ "SigType" SG_ 2365450750 Bs1PhseCLineNeutralACRMSVoltage 1;
BA_ "SPN" SG_ 2365450750 Bus1PhaseCALineLineACRMSVoltage 2511;
BA_ "SigType" SG_ 2365450750 Bus1PhaseCALineLineACRMSVoltage 1;
BA_ "SPN" SG_ 2365451006 Bus1PhaseBACFrequency 2506;
BA_ "SigType" SG_ 2365451006 Bus1PhaseBACFrequency 1;
BA_ "SPN" SG_ 2365451006 Bs1PhseBLineNeutralACRMSVoltage 2514;
BA_ "SigType" SG_ 2365451006 Bs1PhseBLineNeutralACRMSVoltage 1;
BA_ "SPN" SG_ 2365451006 Bus1PhaseBCLineLineACRMSVoltage 2510;
BA_ "SigType" SG_ 2365451006 Bus1PhaseBCLineLineACRMSVoltage 1;
BA_ "SPN" SG_ 2365451262 Bus1PhaseAACFrequency 2505;
BA_ "SigType" SG_ 2365451262 Bus1PhaseAACFrequency 1;
BA_ "SPN" SG_ 2365451262 Bs1PhseALineNeutralACRMSVoltage 2513;
BA_ "SigType" SG_ 2365451262 Bs1PhseALineNeutralACRMSVoltage 1;
BA_ "SPN" SG_ 2365451262 Bus1PhaseABLineLineACRMSVoltage 2509;
BA_ "SigType" SG_ 2365451262 Bus1PhaseABLineLineACRMSVoltage 1;
BA_ "SPN" SG_ 2365450494 Bus1_GeneratorACPhaseDifference 2516;
BA_ "SigType" SG_ 2365450494 Bus1_GeneratorACPhaseDifference 1;
BA_ "SPN" SG_ 2365450494 Bus1_GeneratorInSync 2529;
BA_ "SigType" SG_ 2365450494 Bus1_GeneratorInSync 4;
BA_ "SPN" SG_ 2365450494 Bus1_GeneratorVoltageMatch 2527;
BA_ "SigType" SG_ 2365450494 Bus1_GeneratorVoltageMatch 4;
BA_ "SPN" SG_ 2365450494 Bus1_GeneratorFrequencyMatch 2528;
BA_ "SigType" SG_ 2365450494 Bus1_GeneratorFrequencyMatch 4;
BA_ "SPN" SG_ 2365450494 Bus1_GeneratorPhaseMatch 2526;
BA_ "SigType" SG_ 2365450494 Bus1_GeneratorPhaseMatch 4;
BA_ "SPN" SG_ 2365450494 Bus1_GeneratorDeadBus 2530;
BA_ "SigType" SG_ 2365450494 Bus1_GeneratorDeadBus 4;
BA_ "SPN" SG_ 2365451518 Bus1AverageACFrequency 2504;
BA_ "SigType" SG_ 2365451518 Bus1AverageACFrequency 1;
BA_ "SPN" SG_ 2365451518 Bs1AvrgeLineNeutralACRMSVoltage 2512;
BA_ "SigType" SG_ 2365451518 Bs1AvrgeLineNeutralACRMSVoltage 1;
BA_ "SPN" SG_ 2365451518 Bus1AverageLineLineACRMSVoltage 2508;
BA_ "SigType" SG_ 2365451518 Bus1AverageLineLineACRMSVoltage 1;
BA_ "SigType" SG_ 2566786558 NumberOfMembers 3;
BA_ "SPN" SG_ 2566838526 AddressAssignment 2847;
BA_ "SPN" SG_ 2566838526 ArbitraryAddressCapable 2844;
BA_ "SPN" SG_ 2566838526 IndustryGroup 2846;
BA_ "SPN" SG_ 2566838526 VehicleSystemInstance 2843;
BA_ "SPN" SG_ 2566838526 Function 2841;
BA_ "SPN" SG_ 2566838526 FunctionInstance 2839;
BA_ "SPN" SG_ 2566838526 ECUInstance 2840;
BA_ "SPN" SG_ 2566838526 ManufacturerCode 2838;
BA_ "SigType" SG_ 2566838526 ManufacturerCode 1;
BA_ "SPN" SG_ 2566838526 IdentityNumber 2837;
BA_ "SPN" SG_ 2565799678 ArbitraryAddressCapable 2844;
BA_ "SPN" SG_ 2565799678 IndustryGroup 2846;
BA_ "SPN" SG_ 2565799678 VehicleSystemInstance 2843;
BA_ "SPN" SG_ 2565799678 Function 2841;
BA_ "SPN" SG_ 2565799678 FunctionInstance 2839;
BA_ "SPN" SG_ 2565799678 ECUInstance 2840;
BA_ "SPN" SG_ 2565799678 ManufacturerCode 2838;
BA_ "SigType" SG_ 2565799678 ManufacturerCode 1;
BA_ "SPN" SG_ 2565799678 IdentityNumber 2837;
BA_ "SPN" SG_ 2563440382 ShrtNameOfActualReportingDevice 2554;
BA_ "SigType" SG_ 2563440382 ShrtNameOfActualReportingDevice 4;
BA_ "SPN" SG_ 2563440382 LengthOfDataForTheReportedPGN 2553;
BA_ "SigType" SG_ 2563440382 LengthOfDataForTheReportedPGN 1;
BA_ "SPN" SG_ 2563440382 PGNofRequstedInformation 2552;
BA_ "SigType" SG_ 2563440382 PGNofRequstedInformation 6;
BA_ "SPN" SG_ 2565603070 SequenceNumber 2572;
BA_ "SPN" SG_ 2565668606 TotalNumberOfPacketsEoMA 2565;
BA_ "SPN" SG_ 2565668606 TotalMessageSizeEoMA 2564;
BA_ "SigType" SG_ 2565668606 TotalMessageSizeEoMA 1;
BA_ "SPN" SG_ 2565668606 TotalMessageSizeBAM 2567;
BA_ "SigType" SG_ 2565668606 TotalMessageSizeBAM 1;
BA_ "SPN" SG_ 2565668606 TotalNumberOfPacketsBAM 2568;
BA_ "SPN" SG_ 2565668606 ConnectionAbortReason 2570;
BA_ "SPN" SG_ 2565668606 NextPacketNumberToBeSent 2562;
BA_ "SPN" SG_ 2565668606 NumberOfPacketsThatCanBeSent 2561;
BA_ "SPN" SG_ 2565668606 PGNumber 2560;
BA_ "SigType" SG_ 2565668606 PGNumber 6;
BA_ "SPN" SG_ 2565668606 MaximumNumberOfPackets 2559;
BA_ "SPN" SG_ 2565668606 TotalNumberOfPackets 2558;
BA_ "SPN" SG_ 2565668606 TotalMessageSize 2557;
BA_ "SigType" SG_ 2565668606 TotalMessageSize 1;
BA_ "SPN" SG_ 2565668606 ControlByte 2556;
BA_ "SPN" SG_ 2563374846 ParameterGroupNumber 2574;
BA_ "SigType" SG_ 2563374846 ParameterGroupNumber 6;
BA_ "SPN" SG_ 2563374846 UseTransferMode 2575;
BA_ "SigType" SG_ 2563374846 UseTransferMode 4;
BA_ "SPN" SG_ 2565537534 ParameterGroupNumber 2540;
BA_ "SigType" SG_ 2565537534 ParameterGroupNumber 6;
BA_ "SPN" SG_ 2499635966 AdditionalAxleGroupLocation 5935;
BA_ "SPN" SG_ 2499635966 AxleGroupWeight 409;
BA_ "SigType" SG_ 2499635966 AxleGroupWeight 1;
BA_ "SPN" SG_ 2499635966 AxleGroupLocation 4073;
BA_ "SPN" SG_ 2633853438 AdditionalAxleGroupLocation 5936;
BA_ "SPN" SG_ 2633853438 AxleGroupFullWeightCalib 407;
BA_ "SigType" SG_ 2633853438 AxleGroupFullWeightCalib 1;
BA_ "SPN" SG_ 2633853438 AxleGroupEmptyWeightCalib 408;
BA_ "SigType" SG_ 2633853438 AxleGroupEmptyWeightCalib 1;
BA_ "SPN" SG_ 2633853438 AxleGroupLocation 4074;
BA_ "SPN" SG_ 2432520702 EngChrgeAirCoolerBypassValve2Cmd 7422;
BA_ "SigType" SG_ 2432520702 EngChrgeAirCoolerBypassValve2Cmd 1;
BA_ "SPN" SG_ 2432520702 EngChrgeAirCoolerBypassValve1Cmd 7421;
BA_ "SigType" SG_ 2432520702 EngChrgeAirCoolerBypassValve1Cmd 1;
BA_ "SPN" SG_ 2432520702 DsrdAftrclrClntThermostatOpening 4200;
BA_ "SigType" SG_ 2432520702 DsrdAftrclrClntThermostatOpening 1;
BA_ "SPN" SG_ 2432520702 DsrdAftercoolerCoolantIntakeTemp 4199;
BA_ "SigType" SG_ 2432520702 DsrdAftercoolerCoolantIntakeTemp 1;
BA_ "SPN" SG_ 2432520702 AftercoolerCoolantThermostatMode 4198;
BA_ "SigType" SG_ 2432520702 AftercoolerCoolantThermostatMode 5;
BA_ "SPN" SG_ 2566745086 RarDriveAxleGroupWeightAvailable 5934;
BA_ "SigType" SG_ 2566745086 RarDriveAxleGroupWeightAvailable 5;
BA_ "SPN" SG_ 2566745086 RarSteerAxleGroupWeightAvailable 5933;
BA_ "SigType" SG_ 2566745086 RarSteerAxleGroupWeightAvailable 5;
BA_ "SPN" SG_ 2566745086 AddtnlTrlrAxlGrupWeightAvailable 4072;
BA_ "SigType" SG_ 2566745086 AddtnlTrlrAxlGrupWeightAvailable 5;
BA_ "SPN" SG_ 2566745086 TrailerHAxleGroupWeightAvailable 4071;
BA_ "SigType" SG_ 2566745086 TrailerHAxleGroupWeightAvailable 5;
BA_ "SPN" SG_ 2566745086 TrailerGAxleGroupWeightAvailable 4070;
BA_ "SigType" SG_ 2566745086 TrailerGAxleGroupWeightAvailable 5;
BA_ "SPN" SG_ 2566745086 TrailerFAxleGroupWeightAvailable 4069;
BA_ "SigType" SG_ 2566745086 TrailerFAxleGroupWeightAvailable 5;
BA_ "SPN" SG_ 2566745086 TrailerEAxleGroupWeightAvailable 4068;
BA_ "SigType" SG_ 2566745086 TrailerEAxleGroupWeightAvailable 5;
BA_ "SPN" SG_ 2566745086 TrailerDAxleGroupWeightAvailable 4067;
BA_ "SigType" SG_ 2566745086 TrailerDAxleGroupWeightAvailable 5;
BA_ "SPN" SG_ 2566745086 TrailerCAxleGroupWeightAvailable 4066;
BA_ "SigType" SG_ 2566745086 TrailerCAxleGroupWeightAvailable 5;
BA_ "SPN" SG_ 2566745086 TrailerBAxleGroupWeightAvailable 4065;
BA_ "SigType" SG_ 2566745086 TrailerBAxleGroupWeightAvailable 5;
BA_ "SPN" SG_ 2566745086 TrailerAAxleGroupWeightAvailable 4064;
BA_ "SigType" SG_ 2566745086 TrailerAAxleGroupWeightAvailable 5;
BA_ "SPN" SG_ 2566745086 AddtnlTrctrAxlGrpWeightAvailable 4063;
BA_ "SigType" SG_ 2566745086 AddtnlTrctrAxlGrpWeightAvailable 5;
BA_ "SPN" SG_ 2566745086 TagAxleGroupWeightAvailable 4062;
BA_ "SigType" SG_ 2566745086 TagAxleGroupWeightAvailable 5;
BA_ "SPN" SG_ 2566745086 DriveAxleGroupWeightAvailable 4061;
BA_ "SigType" SG_ 2566745086 DriveAxleGroupWeightAvailable 5;
BA_ "SPN" SG_ 2566745086 LiftAxleGroupWeightAvailable 4060;
BA_ "SigType" SG_ 2566745086 LiftAxleGroupWeightAvailable 5;
BA_ "SPN" SG_ 2566745086 SteerAxleGroupWeightAvailable 4059;
BA_ "SigType" SG_ 2566745086 SteerAxleGroupWeightAvailable 5;
BA_ "SPN" SG_ 2566739198 FlashRedStopLamp 3039;
BA_ "SigType" SG_ 2566739198 FlashRedStopLamp 5;
BA_ "SPN" SG_ 2566739198 FlashProtectLamp 3041;
BA_ "SigType" SG_ 2566739198 FlashProtectLamp 5;
BA_ "SPN" SG_ 2566739198 FlashMalfuncIndicatorLamp 3038;
BA_ "SigType" SG_ 2566739198 FlashMalfuncIndicatorLamp 5;
BA_ "SPN" SG_ 2566739198 FlashAmberWarningLamp 3040;
BA_ "SigType" SG_ 2566739198 FlashAmberWarningLamp 5;
BA_ "SPN" SG_ 2566739198 MalfunctionIndicatorLampStatus 1213;
BA_ "SigType" SG_ 2566739198 MalfunctionIndicatorLampStatus 5;
BA_ "SPN" SG_ 2566739198 AmberWarningLampStatus 624;
BA_ "SigType" SG_ 2566739198 AmberWarningLampStatus 5;
BA_ "SPN" SG_ 2566739198 RedStopLampState 623;
BA_ "SigType" SG_ 2566739198 RedStopLampState 4;
BA_ "SPN" SG_ 2566739198 ProtectLampStatus 987;
BA_ "SigType" SG_ 2566739198 ProtectLampStatus 5;
BA_ "SigType" SG_ 2566739198 DTC5 7;
BA_ "SigType" SG_ 2566739198 DTC4 7;
BA_ "SigType" SG_ 2566739198 DTC3 7;
BA_ "SigType" SG_ 2566739198 DTC2 7;
BA_ "SigType" SG_ 2566739198 DTC1 7;
BA_ "SPN" SG_ 2566739454 FlashRedStopLamp 3039;
BA_ "SigType" SG_ 2566739454 FlashRedStopLamp 5;
BA_ "SPN" SG_ 2566739454 FlashProtectLamp 3041;
BA_ "SigType" SG_ 2566739454 FlashProtectLamp 5;
BA_ "SPN" SG_ 2566739454 FlashMalfuncIndicatorLamp 3038;
BA_ "SigType" SG_ 2566739454 FlashMalfuncIndicatorLamp 5;
BA_ "SPN" SG_ 2566739454 FlashAmberWarningLamp 3040;
BA_ "SigType" SG_ 2566739454 FlashAmberWarningLamp 5;
BA_ "SPN" SG_ 2566739454 MalfunctionIndicatorLampStatus 1213;
BA_ "SigType" SG_ 2566739454 MalfunctionIndicatorLampStatus 5;
BA_ "SPN" SG_ 2566739454 AmberWarningLampStatus 624;
BA_ "SigType" SG_ 2566739454 AmberWarningLampStatus 5;
BA_ "SPN" SG_ 2566739454 RedStopLampState 623;
BA_ "SigType" SG_ 2566739454 RedStopLampState 4;
BA_ "SPN" SG_ 2566739454 ProtectLampStatus 987;
BA_ "SigType" SG_ 2566739454 ProtectLampStatus 5;
BA_ "SigType" SG_ 2566739454 DTC5 7;
BA_ "SigType" SG_ 2566739454 DTC4 7;
BA_ "SigType" SG_ 2566739454 DTC3 7;
BA_ "SigType" SG_ 2566739454 DTC2 7;
BA_ "SigType" SG_ 2566739454 DTC1 7;
BA_ "SPN" SG_ 2566739710 FlashRedStopLamp 3039;
BA_ "SigType" SG_ 2566739710 FlashRedStopLamp 5;
BA_ "SPN" SG_ 2566739710 FlashProtectLamp 3041;
BA_ "SigType" SG_ 2566739710 FlashProtectLamp 5;
BA_ "SPN" SG_ 2566739710 FlashMalfuncIndicatorLamp 3038;
BA_ "SigType" SG_ 2566739710 FlashMalfuncIndicatorLamp 5;
BA_ "SPN" SG_ 2566739710 FlashAmberWarningLamp 3040;
BA_ "SigType" SG_ 2566739710 FlashAmberWarningLamp 5;
BA_ "SPN" SG_ 2566739710 MalfunctionIndicatorLampStatus 1213;
BA_ "SigType" SG_ 2566739710 MalfunctionIndicatorLampStatus 5;
BA_ "SPN" SG_ 2566739710 AmberWarningLampStatus 624;
BA_ "SigType" SG_ 2566739710 AmberWarningLampStatus 5;
BA_ "SPN" SG_ 2566739710 RedStopLampState 623;
BA_ "SigType" SG_ 2566739710 RedStopLampState 4;
BA_ "SPN" SG_ 2566739710 ProtectLampStatus 987;
BA_ "SigType" SG_ 2566739710 ProtectLampStatus 5;
BA_ "SigType" SG_ 2566739710 DTC5 7;
BA_ "SigType" SG_ 2566739710 DTC4 7;
BA_ "SigType" SG_ 2566739710 DTC3 7;
BA_ "SigType" SG_ 2566739710 DTC2 7;
BA_ "SigType" SG_ 2566739710 DTC1 7;
BA_ "SPN" SG_ 2566739966 FlashRedStopLamp 3039;
BA_ "SigType" SG_ 2566739966 FlashRedStopLamp 5;
BA_ "SPN" SG_ 2566739966 FlashProtectLamp 3041;
BA_ "SigType" SG_ 2566739966 FlashProtectLamp 5;
BA_ "SPN" SG_ 2566739966 FlashMalfuncIndicatorLamp 3038;
BA_ "SigType" SG_ 2566739966 FlashMalfuncIndicatorLamp 5;
BA_ "SPN" SG_ 2566739966 FlashAmberWarningLamp 3040;
BA_ "SigType" SG_ 2566739966 FlashAmberWarningLamp 5;
BA_ "SPN" SG_ 2566739966 MalfunctionIndicatorLampStatus 1213;
BA_ "SigType" SG_ 2566739966 MalfunctionIndicatorLampStatus 5;
BA_ "SPN" SG_ 2566739966 AmberWarningLampStatus 624;
BA_ "SigType" SG_ 2566739966 AmberWarningLampStatus 5;
BA_ "SPN" SG_ 2566739966 RedStopLampState 623;
BA_ "SigType" SG_ 2566739966 RedStopLampState 4;
BA_ "SPN" SG_ 2566739966 ProtectLampStatus 987;
BA_ "SigType" SG_ 2566739966 ProtectLampStatus 5;
BA_ "SigType" SG_ 2566739966 DTC5 7;
BA_ "SigType" SG_ 2566739966 DTC4 7;
BA_ "SigType" SG_ 2566739966 DTC3 7;
BA_ "SigType" SG_ 2566739966 DTC2 7;
BA_ "SigType" SG_ 2566739966 DTC1 7;
BA_ "SPN" SG_ 2566740222 FlashRedStopLamp 3039;
BA_ "SigType" SG_ 2566740222 FlashRedStopLamp 5;
BA_ "SPN" SG_ 2566740222 FlashProtectLamp 3041;
BA_ "SigType" SG_ 2566740222 FlashProtectLamp 5;
BA_ "SPN" SG_ 2566740222 FlashMalfuncIndicatorLamp 3038;
BA_ "SigType" SG_ 2566740222 FlashMalfuncIndicatorLamp 5;
BA_ "SPN" SG_ 2566740222 FlashAmberWarningLamp 3040;
BA_ "SigType" SG_ 2566740222 FlashAmberWarningLamp 5;
BA_ "SPN" SG_ 2566740222 MalfunctionIndicatorLampStatus 1213;
BA_ "SigType" SG_ 2566740222 MalfunctionIndicatorLampStatus 5;
BA_ "SPN" SG_ 2566740222 AmberWarningLampStatus 624;
BA_ "SigType" SG_ 2566740222 AmberWarningLampStatus 5;
BA_ "SPN" SG_ 2566740222 RedStopLampState 623;
BA_ "SigType" SG_ 2566740222 RedStopLampState 4;
BA_ "SPN" SG_ 2566740222 ProtectLampStatus 987;
BA_ "SigType" SG_ 2566740222 ProtectLampStatus 5;
BA_ "SigType" SG_ 2566740222 DTC5 7;
BA_ "SigType" SG_ 2566740222 DTC4 7;
BA_ "SigType" SG_ 2566740222 DTC3 7;
BA_ "SigType" SG_ 2566740222 DTC2 7;
BA_ "SigType" SG_ 2566740222 DTC1 7;
BA_ "SPN" SG_ 2566740478 FlashRedStopLamp 3039;
BA_ "SigType" SG_ 2566740478 FlashRedStopLamp 5;
BA_ "SPN" SG_ 2566740478 FlashProtectLamp 3041;
BA_ "SigType" SG_ 2566740478 FlashProtectLamp 5;
BA_ "SPN" SG_ 2566740478 FlashMalfuncIndicatorLamp 3038;
BA_ "SigType" SG_ 2566740478 FlashMalfuncIndicatorLamp 5;
BA_ "SPN" SG_ 2566740478 FlashAmberWarningLamp 3040;
BA_ "SigType" SG_ 2566740478 FlashAmberWarningLamp 5;
BA_ "SPN" SG_ 2566740478 MalfunctionIndicatorLampStatus 1213;
BA_ "SigType" SG_ 2566740478 MalfunctionIndicatorLampStatus 5;
BA_ "SPN" SG_ 2566740478 AmberWarningLampStatus 624;
BA_ "SigType" SG_ 2566740478 AmberWarningLampStatus 5;
BA_ "SPN" SG_ 2566740478 RedStopLampState 623;
BA_ "SigType" SG_ 2566740478 RedStopLampState 4;
BA_ "SPN" SG_ 2566740478 ProtectLampStatus 987;
BA_ "SigType" SG_ 2566740478 ProtectLampStatus 5;
BA_ "SigType" SG_ 2566740478 DTC5 7;
BA_ "SigType" SG_ 2566740478 DTC4 7;
BA_ "SigType" SG_ 2566740478 DTC3 7;
BA_ "SigType" SG_ 2566740478 DTC2 7;
BA_ "SigType" SG_ 2566740478 DTC1 7;
BA_ "SPN" SG_ 2566740734 FlashRedStopLamp 3039;
BA_ "SigType" SG_ 2566740734 FlashRedStopLamp 5;
BA_ "SPN" SG_ 2566740734 FlashProtectLamp 3041;
BA_ "SigType" SG_ 2566740734 FlashProtectLamp 5;
BA_ "SPN" SG_ 2566740734 FlashMalfuncIndicatorLamp 3038;
BA_ "SigType" SG_ 2566740734 FlashMalfuncIndicatorLamp 5;
BA_ "SPN" SG_ 2566740734 FlashAmberWarningLamp 3040;
BA_ "SigType" SG_ 2566740734 FlashAmberWarningLamp 5;
BA_ "SPN" SG_ 2566740734 MalfunctionIndicatorLampStatus 1213;
BA_ "SigType" SG_ 2566740734 MalfunctionIndicatorLampStatus 5;
BA_ "SPN" SG_ 2566740734 AmberWarningLampStatus 624;
BA_ "SigType" SG_ 2566740734 AmberWarningLampStatus 5;
BA_ "SPN" SG_ 2566740734 RedStopLampState 623;
BA_ "SigType" SG_ 2566740734 RedStopLampState 4;
BA_ "SPN" SG_ 2566740734 ProtectLampStatus 987;
BA_ "SigType" SG_ 2566740734 ProtectLampStatus 5;
BA_ "SigType" SG_ 2566740734 DTC5 7;
BA_ "SigType" SG_ 2566740734 DTC4 7;
BA_ "SigType" SG_ 2566740734 DTC3 7;
BA_ "SigType" SG_ 2566740734 DTC2 7;
BA_ "SigType" SG_ 2566740734 DTC1 7;
BA_ "SPN" SG_ 2566740990 FlashRedStopLamp 3039;
BA_ "SigType" SG_ 2566740990 FlashRedStopLamp 5;
BA_ "SPN" SG_ 2566740990 FlashProtectLamp 3041;
BA_ "SigType" SG_ 2566740990 FlashProtectLamp 5;
BA_ "SPN" SG_ 2566740990 FlashMalfuncIndicatorLamp 3038;
BA_ "SigType" SG_ 2566740990 FlashMalfuncIndicatorLamp 5;
BA_ "SPN" SG_ 2566740990 FlashAmberWarningLamp 3040;
BA_ "SigType" SG_ 2566740990 FlashAmberWarningLamp 5;
BA_ "SPN" SG_ 2566740990 MalfunctionIndicatorLampStatus 1213;
BA_ "SigType" SG_ 2566740990 MalfunctionIndicatorLampStatus 5;
BA_ "SPN" SG_ 2566740990 AmberWarningLampStatus 624;
BA_ "SigType" SG_ 2566740990 AmberWarningLampStatus 5;
BA_ "SPN" SG_ 2566740990 RedStopLampState 623;
BA_ "SigType" SG_ 2566740990 RedStopLampState 4;
BA_ "SPN" SG_ 2566740990 ProtectLampStatus 987;
BA_ "SigType" SG_ 2566740990 ProtectLampStatus 5;
BA_ "SigType" SG_ 2566740990 DTC5 7;
BA_ "SigType" SG_ 2566740990 DTC4 7;
BA_ "SigType" SG_ 2566740990 DTC3 7;
BA_ "SigType" SG_ 2566740990 DTC2 7;
BA_ "SigType" SG_ 2566740990 DTC1 7;
BA_ "SPN" SG_ 2566741246 FlashRedStopLamp 3039;
BA_ "SigType" SG_ 2566741246 FlashRedStopLamp 5;
BA_ "SPN" SG_ 2566741246 FlashProtectLamp 3041;
BA_ "SigType" SG_ 2566741246 FlashProtectLamp 5;
BA_ "SPN" SG_ 2566741246 FlashMalfuncIndicatorLamp 3038;
BA_ "SigType" SG_ 2566741246 FlashMalfuncIndicatorLamp 5;
BA_ "SPN" SG_ 2566741246 FlashAmberWarningLamp 3040;
BA_ "SigType" SG_ 2566741246 FlashAmberWarningLamp 5;
BA_ "SPN" SG_ 2566741246 MalfunctionIndicatorLampStatus 1213;
BA_ "SigType" SG_ 2566741246 MalfunctionIndicatorLampStatus 5;
BA_ "SPN" SG_ 2566741246 AmberWarningLampStatus 624;
BA_ "SigType" SG_ 2566741246 AmberWarningLampStatus 5;
BA_ "SPN" SG_ 2566741246 RedStopLampState 623;
BA_ "SigType" SG_ 2566741246 RedStopLampState 4;
BA_ "SPN" SG_ 2566741246 ProtectLampStatus 987;
BA_ "SigType" SG_ 2566741246 ProtectLampStatus 5;
BA_ "SigType" SG_ 2566741246 DTC5 7;
BA_ "SigType" SG_ 2566741246 DTC4 7;
BA_ "SigType" SG_ 2566741246 DTC3 7;
BA_ "SigType" SG_ 2566741246 DTC2 7;
BA_ "SigType" SG_ 2566741246 DTC1 7;
BA_ "SPN" SG_ 2566741502 FlashRedStopLamp 3039;
BA_ "SigType" SG_ 2566741502 FlashRedStopLamp 5;
BA_ "SPN" SG_ 2566741502 FlashProtectLamp 3041;
BA_ "SigType" SG_ 2566741502 FlashProtectLamp 5;
BA_ "SPN" SG_ 2566741502 FlashMalfuncIndicatorLamp 3038;
BA_ "SigType" SG_ 2566741502 FlashMalfuncIndicatorLamp 5;
BA_ "SPN" SG_ 2566741502 FlashAmberWarningLamp 3040;
BA_ "SigType" SG_ 2566741502 FlashAmberWarningLamp 5;
BA_ "SPN" SG_ 2566741502 MalfunctionIndicatorLampStatus 1213;
BA_ "SigType" SG_ 2566741502 MalfunctionIndicatorLampStatus 5;
BA_ "SPN" SG_ 2566741502 AmberWarningLampStatus 624;
BA_ "SigType" SG_ 2566741502 AmberWarningLampStatus 5;
BA_ "SPN" SG_ 2566741502 RedStopLampState 623;
BA_ "SigType" SG_ 2566741502 RedStopLampState 4;
BA_ "SPN" SG_ 2566741502 ProtectLampStatus 987;
BA_ "SigType" SG_ 2566741502 ProtectLampStatus 5;
BA_ "SigType" SG_ 2566741502 DTC5 7;
BA_ "SigType" SG_ 2566741502 DTC4 7;
BA_ "SigType" SG_ 2566741502 DTC3 7;
BA_ "SigType" SG_ 2566741502 DTC2 7;
BA_ "SigType" SG_ 2566741502 DTC1 7;
BA_ "SPN" SG_ 2566741758 FlashRedStopLamp 3039;
BA_ "SigType" SG_ 2566741758 FlashRedStopLamp 5;
BA_ "SPN" SG_ 2566741758 FlashProtectLamp 3041;
BA_ "SigType" SG_ 2566741758 FlashProtectLamp 5;
BA_ "SPN" SG_ 2566741758 FlashMalfuncIndicatorLamp 3038;
BA_ "SigType" SG_ 2566741758 FlashMalfuncIndicatorLamp 5;
BA_ "SPN" SG_ 2566741758 FlashAmberWarningLamp 3040;
BA_ "SigType" SG_ 2566741758 FlashAmberWarningLamp 5;
BA_ "SPN" SG_ 2566741758 MalfunctionIndicatorLampStatus 1213;
BA_ "SigType" SG_ 2566741758 MalfunctionIndicatorLampStatus 5;
BA_ "SPN" SG_ 2566741758 AmberWarningLampStatus 624;
BA_ "SigType" SG_ 2566741758 AmberWarningLampStatus 5;
BA_ "SPN" SG_ 2566741758 RedStopLampState 623;
BA_ "SigType" SG_ 2566741758 RedStopLampState 4;
BA_ "SPN" SG_ 2566741758 ProtectLampStatus 987;
BA_ "SigType" SG_ 2566741758 ProtectLampStatus 5;
BA_ "SigType" SG_ 2566741758 DTC5 7;
BA_ "SigType" SG_ 2566741758 DTC4 7;
BA_ "SigType" SG_ 2566741758 DTC3 7;
BA_ "SigType" SG_ 2566741758 DTC2 7;
BA_ "SigType" SG_ 2566741758 DTC1 7;
VAL_ 2566834942 FlashRedStopLamp 3 "Unavailable / Do Not Flash" 2 "Reserved" 1 "Fast Flash" 0 "Slow Flash" ;
VAL_ 2566834942 FlashProtectLamp 3 "Unavailable / Do Not Flash" 2 "Reserved" 1 "Fast Flash" 0 "Slow Flash" ;
VAL_ 2566834942 FlashMalfuncIndicatorLamp 3 "Unavailable / Do Not Flash" 2 "Class C DTC  " 1 "Fast Flash" 0 "Slow Flash" ;
VAL_ 2566834942 FlashAmberWarningLamp 3 "Unavailable / Do Not Flash" 2 "Reserved" 1 "Fast Flash" 0 "Slow Flash" ;
VAL_ 2566834942 MalfunctionIndicatorLampStatus 3 "Not available" 2 "Short MIL for WWH OBD" 1 "Lamp On" 0 "Lamp Off" ;
VAL_ 2566834942 AmberWarningLampStatus 3 "Not available" 2 "Reserved" 1 "Lamp On" 0 "Lamp Off" ;
VAL_ 2566834942 RedStopLampState 3 "Not available" 2 "Reserved" 1 "Lamp On" 0 "Lamp Off" ;
VAL_ 2566834942 ProtectLampStatus 3 "Not available" 2 "Reserved" 1 "Lamp On" 0 "Lamp Off" ;
VAL_ 2365454334 UtlityOverallPowerFactorLagging 3 "Not Available or Not Installed" 2 "Error" 1 "Lagging" 0 "Leading" ;
VAL_ 2365452030 UtilityPhaseCPowerFactorLagging 3 "Not Available or Not Installed" 2 "Error" 1 "Lagging" 0 "Leading" ;
VAL_ 2365452798 UtilityPhaseBPowerFactorLagging 3 "Not Available or Not Installed" 2 "Error" 1 "Lagging" 0 "Leading" ;
VAL_ 2365453566 UtilityPhaseAPowerFactorLagging 3 "Not Available or Not Installed" 2 "Error" 1 "Lagging" 0 "Leading" ;
VAL_ 2365457662 GnrtorOverallPowerFactorLagging 3 "Not Available or Not Installed" 2 "Error" 1 "Lagging" 0 "Leading" ;
VAL_ 2365455358 GnratorPhaseCPowerFactorLagging 3 "Not Available or Not Installed" 2 "Error" 1 "Lagging" 0 "Leading" ;
VAL_ 2365456126 GnratorPhaseBPowerFactorLagging 3 "Not Available or Not Installed" 2 "Error" 1 "Lagging" 0 "Leading" ;
VAL_ 2365456894 GnratorPhaseAPowerFactorLagging 3 "Not Available or Not Installed" 2 "Error" 1 "Lagging" 0 "Leading" ;
VAL_ 2365450238 Bus1_UtilityInSync 3 "Not Available or Not Installed" 2 "Error" 1 "Synchronized" 0 "Not synchronized" ;
VAL_ 2365450238 Bus1_UtilityVoltageMatch 3 "Not Available or Not Installed" 2 "Error" 1 "Voltages match" 0 "Voltages do not match" ;
VAL_ 2365450238 Bus1_UtilityFrequencyMatch 3 "Not Available or Not Installed" 2 "Error" 1 "Frequencies match" 0 "Frequencies do not match" ;
VAL_ 2365450238 Bus1_UtilityPhaseMatch 3 "Not Available or Not Installed" 2 "Error" 1 "Phases match" 0 "Phases do not match" ;
VAL_ 2365450238 Bus1_UtilityDeadBus 3 "Not Available or Not Installed" 2 "Error" 1 "Bus is dead" 0 "Bus is not dead" ;
VAL_ 2365450494 Bus1_GeneratorInSync 3 "Not Available or Not Installed" 2 "Error" 1 "Synchronized" 0 "Not synchronized" ;
VAL_ 2365450494 Bus1_GeneratorVoltageMatch 3 "Not Available or Not Installed" 2 "Error" 1 "Voltages match" 0 "Voltages do not match" ;
VAL_ 2365450494 Bus1_GeneratorFrequencyMatch 3 "Not Available or Not Installed" 2 "Error" 1 "Frequencies match" 0 "Frequencies do not match" ;
VAL_ 2365450494 Bus1_GeneratorPhaseMatch 3 "Not Available or Not Installed" 2 "Error" 1 "Phases match" 0 "Phases do not match" ;
VAL_ 2365450494 Bus1_GeneratorDeadBus 3 "Not Available or Not Installed" 2 "Error" 1 "Bus is dead" 0 "Bus is not dead" ;
VAL_ 2566838526 IndustryGroup 6 "Reserved for SAE" 7 "Reserved for SAE" 5 "IndustrialProcessCtrlStationary" 4 "Marine" 3 "Construction" 2 "Agricultural and Forestry" 1 "On-Highway" 0 "Global" ;
VAL_ 2566838526 Function 127 "Reserved" 126 "Reserved" 125 "Reserved" 124 "Reserved" 123 "Reserved" 122 "Reserved" 121 "Reserved" 120 "Reserved" 119 "Reserved" 118 "Reserved" 117 "Reserved" 116 "Reserved" 115 "Reserved" 114 "Reserved" 113 "Reserved" 112 "Reserved" 111 "Reserved" 110 "Reserved" 109 "Reserved" 108 "Reserved" 107 "Reserved" 106 "Reserved" 105 "Reserved" 104 "Reserved" 103 "Reserved" 102 "Reserved" 101 "Reserved" 42 "Water Pump Control" 41 "Lighting - Operator Controls" 40 "Seat Control" 39 "Ignition Control Module" 38 "Tire Pressure Control" 37 "Cab Controller" 36 "Pneumatic - System Controller" 35 "Suspension - System Controller" 34 "Hydraulic Pump Controller" 33 "System Monitor" 32 "Headway Controller" 31 "Propulsion Battery Charger" 30 "Management Computer" 29 "Virtual Terminal (in cab)" 28 "Off Vehicle Gateway" 27 "Power TakeOff (Secondary or Front)" 26 "Body Controller" 25 "Network Interconnect ECU" 24 "Vehicle Security" 23 "Vehicle Navigation" 22 "Aerodynamic Control" 21 "Cab Climate Control" 20 "Trip Recorder" 19 "Instrument Cluster" 18 "Suspension - Drive Axle" 17 "Suspension - Steer Axle" 16 "Steering Controller" 15 "Fuel System" 14 "Cruise Control" 13 "Retarder - Driveline" 12 "Retarder - Engine" 11 "Brakes - Drive Axle" 10 "Brakes - Steer Axle" 9 "Brakes - System Controller" 8 "Axle - Drive" 7 "Axle - Steering" 6 "Power TakeOff - (Main or Rear)" 5 "Shift Control/Console" 4 "Battery Pack Monitor" 3 "Transmission" 2 "Electric Propulsion Control" 1 "Auxiliary Power Unit (APU)" 0 "Engine" 100 "Reserved" 99 "Reserved" 98 "Reserved" 97 "Reserved" 96 "Reserved" 95 "Reserved" 94 "Reserved" 93 "Reserved" 92 "Reserved" 91 "Reserved" 90 "Reserved" 89 "Reserved" 88 "Reserved" 87 "Reserved" 86 "Reserved" 85 "Reserved" 84 "Reserved" 83 "Reserved" 82 "Reserved" 81 "Reserved" 80 "Reserved" 79 "Reserved" 78 "Fire Suppression System" 77 "Fuel Properties Sensor" 76 "Temperature Sensor" 75 "Supplemental Fan" 74 "Lubrication System" 73 "Rollover Detection Control" 72 "Coolant Valve Controller" 71 "Transfer Case Control" 70 "Auxiliary Regeneration Device" 69 "Engine Emission Aftertreatement System" 68 "Aftertreatment system gas measurement" 67 "Electrical System Controller" 66 "I/O Controller" 65 "Gas Flow Measurement" 64 "Endurance Braking" 63 "Engine Valve Controller" 62 "On-Board Diagnostic Unit" 61 "File Server/Printer" 60 "Cab Display" 59 "Starter" 58 "Fan Drive Control" 57 "Steering Column Unit" 56 "Communications Unit, Radio" 55 "Communications Unit, Satellite" 54 "Communications Unit, Cellular" 53 "Alternator/Charging System" 52 "Chassis Controller" 51 "Forward-Looking Collision Warning System" 50 "Auxiliary Heater" 49 "Clutch/Converter Control" 48 "Ramp Control" 47 "Information System Controller" 46 "Oil Sensor Unit" 45 "Vehicle Dynamic Stability Control" 44 "Exhaust Emission Control" 43 "Transmission Display" ;
VAL_ 2566838526 VehicleSystem 0 "Non-specific System" 127 "Not Available" ;
VAL_ 2566838526 ManufacturerCode 139 "Caterpillar Trimble Control Technologies (CTCT), LLC" 138 "Georg Fritzmeier GmbH & Co. KG" 137 "Maretron" 136 "Komatsu Ltd" 135 "Airmar Technology Corporation" 134 "Iris Technology Ltd" 133 "Bucher Schoerling GmbH" 132 "Mulag-Fahrzeugwerk" 131 "ITT Industries" 130 "Nido - Universal Machines B.V." 129 "OMNEX Control Systems Inc." 128 "Gerhard Duecker GmbH & Co. KG" 1863 "Thomas G. Faria Co." 1862 "Sanshin" 1861 "Vector North America (formerly Vector Cantech)" 1860 "MMP" 1859 "Kvasar AB" 1858 "Litton" 1857 "Simrad" 1856 "Trimble" 1855 "Furuno USA" 1854 "Northstar Technologies" 1853 "Japan Radio Co" 1852 "Navionics" 1851 "RayMarine" 1850 "Seastar Solutions (formerly Teleflex)" 896 "NextFour Solutions Ltd" 895 "Peloton Technology" 894 "Rhodan Marine Systems of Florida LLC" 893 "KlinkTechnics Ltd." 892 "Mectronx Corp" 891 "CarrierWeb" 890 "L3 Technologies, Inc." 889 "SANY America Inc" 888 "Carma Systems Inc" 887 "Hyperdrive Innovation Limited" 886 "Hitachi Zosen Corporation" 885 "SICK Stegmann GmbH" 884 "Sure Grip Controls Inc." 883 "Swift Navigation, Inc." 882 "BHTronik GmbH & Co. KG" 881 "Sovema" 880 "Revision Military" 879 "PG쟕rionic,쟅nc." 878 "FOTON" 877 "SICK ATech GmbH" 876 "SUCO Robert Scheuffele GmbH & Co. KG" 875 "Salvarani S.r.l." 874 "MTA S.p.A." 873 "Garnet Instruments Ltd." 872 "K�hlig Antriebstechnik GmbH" 871 "Superior Tech Inc" 870 "Textron Fleet Management" 869 "Intercomp" 868 "Data Panel Corp" 867 "Skeleton Technologies" 866 "Netradyne, Inc." 865 "MyEasyFarm" 864 "Streamline Transportation Technologies Inc." 863 "SMAG" 862 "Prospec Electronics" 861 "Adel System S.r.l." 860 "Michelin" 859 "Valor" 858 "Littelfuse" 857 "Zoomlion Heavy Industry NA, Inc" 856 "FarmFacts GmbH" 855 "Toshiba Infrastructure Systems & Solutions Corporation" 854 "GEMAC Chemnitz GmbH" 853 "Teledyne RESON BV" 852 "Velvac Inc" 851 "Novotechnik Messwertaufnehmer OHG" 850 "Geoprospectors GmbH" 849 "MTS Maschinentechnik Schrode AG" 848 "ningupex" 847 "Oceanvolt" 846 "L3 Magnet-Motor" 845 "GMB G�strower Maschinenbau GmbH" 844 "FELL AS" 843 "Hendrickson Truck Commercial Vehicle Systems" 842 "DigiDevice Srl" 841 "Agra-GPS" 840 "E.S.T.E. srl" 839 "Indexator Rotator Systems AB" 838 "Teamsurv Ltd" 837 "Famic Technologies Inc." 836 "Signature4" 835 "PetTrack Ltd." 834 "Pioneer Microsystems, Inc." 833 "Electrum Automation AB" 832 "Heizomat Ger�tebau-Energiesysteme GmbH" 831 "DOK-ING Ltd." 830 "Ultra Motion LLC" 829 "Drov Technologies, Inc." 828 "AgriBrink Inc." 827 "INmatix Technology Group Ltd" 826 "Lewmar Marine Inc" 825 "BPW Hung�ria" 824 "Undheim Systems AS" 823 "ACEINNA, Inc (formerly MEMSIC, Inc)" 822 "Bren-Tronics, Inc." 821 "Thorsen Teknik A/S" 820 "DIaLOGIKa Gesellschaft fuer angewandte Informatik mbH" 819 "Preco Electronics" 818 "HGNSS" 817 "TE Connectivity Sensor Solutions" 816 "UniStrong" 815 "FLIR Systems, Inc." 814 "Soltec Soluzioni Tecnologiche Srl" 813 "Thales Suisse SA" 812 "Torch Technologies" 811 "Blue Water Desalination" 810 "Dutch Power Company" 809 "HMS Industrial Networks AB" 808 "RIMEX Supply Ltd." 807 "Schneider-Electric" 806 "Charge Automotive Ltd" 805 "Gundersen & L�ken AS" 804 "ASA Electronics" 803 "Gill Sensors & Controls Limited" 802 "SPBI (Bj Technologie)" 801 "LOR Manufacturing Company Inc." 800 "Delta-Q Technologies" 799 "Stillwater Designs and Audio, Inc. - KICKER" 798 "Lumishore Ltd" 797 "Tides Marine" 796 "Canadian Automotive Industries Ltd" 795 "Broyda Enterprises Pty Ltd" 794 "Shihlin Electric & Engineering Corporation" 793 "James Fisher Prolec" 792 "Kostal Mexicana" 791 "AUTEC" 790 "VACALL" 789 "GRADALL" 788 "MoTeC Pty Ltd" 787 "Abertax Technologies Limited" 786 "Johnson Matthey Battery Systems" 785 "Fischer Panda GmbH" 784 "CM Automotive Systems, Inc." 783 "Loup Electronics Inc." 782 "AVR bvba" 781 "Poly-Planar LLC" 780 "AVID Technology Ltd" 779 "RLC Electronic Systems" 778 "Seakeeper Inc." 777 "Ocean Signal Ltd" 776 "HMI Systems LLC" 775 "ZIEHL-ABEGG Automotive GmbH" 774 "Taisho Corporation" 773 "Clarion Corporation of America" 772 "Blink Marine" 771 "Shaw Development, LLC" 770 "MONOSEM" 769 "Trombetta" 768 "Flores Automation, LLC" 767 "Alliance Wireless Technologies Inc." 766 "Epec Oy" 765 "GIGAVAC" 764 "Bednar FMT s.r.o." 763 "AT-Systems BVBA" 762 "ROJ s.r.l." 761 "MITA OLEODINAMICA S.p.A." 760 "Bernecker + Rainer Industrie Elektronik GmbH" 759 "Hydro-Gear" 758 "Banner Engineering Corp." 757 "IMPCO Technologies" 756 "Maschio Gaspardo S.P.A." 755 "Firefly Integrations" 754 "Parker Hannifin Corp., Automation Group" 753 "AIROD Technologies" 752 "Deep Sea Electronics Plc" 751 "Pacific Track" 750 "Joskin SA" 749 "Chart Inc." 748 "ISOTTA" 747 "Agratronix" 746 "SureFire Ag Systems, Inc." 745 "Cidra Corporate Services Inc." 744 "Woosung Engineering Co., Ltd." 743 "Daemyung Elevator Co., Ltd." 742 "EROAD" 741 "Carling Technologies" 740 "e-Traction" 739 "LXNAV d.o.o." 738 "Blue Ink Technologies" 737 "Balluff GmbH" 736 "Terex Aerial Work Platforms - Genie" 735 "AEM Performance Electronics" 734 "REAPsystems" 733 "Intendia S.L." 732 "Gefran S.p.A." 731 "Modine Manufacturing Company" 730 "BERTHOUD AGRICOLE" 729 "Liebherr" 728 "Streumaster / Panien" 727 "Dhoot Transmission Pvt Ltd." 726 "MIDORI PRECISIONS" 725 "Hitachi Construction Machinery Co., Ltd." 724 "Electronic Applications, Inc." 723 "Jabil Inc." 722 "Contelec AG" 721 "Hypro" 720 "WITZ Corporation" 719 "Cojali S. L." 718 "Micronet Inc" 717 "Yacht Devices Ltd" 716 "Eaton Control & Power Conversion Division (CPCD)" 715 "Autonnic Research Ltd" 714 "Kobashi Kogyo Co., Ltd." 713 "US Hybrid Corporation" 712 "LOR Manufacturing Company Inc." 711 "DAS Co., LTD" 710 "Greentronics Ltd." 709 "Marquardt GmbH" 708 "Lars Thrane A/S" 707 "Rochester Gauges Inc" 706 "Shanghai Diesel Engine Corporation Limited" 705 "SVAB Hydraulik AB" 704 "JL Audio, Inc." 703 "Hydro Tab Marine Engineering" 702 "Weichai Power Co., Ltd." 701 "BigRoad Inc." 700 "K-Tec Earthmovers Inc." 651 "Takakita Co, Ltd." 650 "Seiko Epson Corp." 649 "Control-Q BV" 648 "OJSC Ekran" 647 "Siloking" 646 "Veenhuis Machines BV" 645 "esd electronic system design gmbh" 644 "KUS USA" 643 "Bogballe A/S" 642 "Moog / Aspen Motion Technologies" 641 "Diverse Yacht Services" 640 "Power Solutions International" 639 "Startec s.r.l." 638 "KVH Industries, Inc." 637 "Bavaria Yachtbau GmbH" 636 "Divelbiss Corporation" 635 "Argo Tractors S.p.A." 634 "Rocky Research" 633 "TORC Robotics" 632 "Pepperl+Fuchs GmbH" 631 "Reltima" 630 "SmartDrive Systems Inc." 629 "Agri Info Design, Ltd." 628 "Falck Schmidt Defence Systems" 627 "Radio Ocean" 626 "AVL DiTEST GmbH" 625 "Global MRV Inc." 624 "Blackbox Machine Control Pty Ltd" 623 "Xirgo Technologies" 622 "Floyd Bell Inc" 621 "Hagie Manufacturing Company" 620 "Sevcon Ltd." 619 "Right Weigh Load Scales" 618 "Evrard SA" 617 "Zero Emission Vehicles" 616 "SMART-TEC s.r.o." 615 "Networkfleet, Verizon Telematics" 614 "ARLT Technologies GmbH" 613 "HKS Co., Ltd." 612 "Samwon IT" 611 "Esterline" 610 "Trail Tech" 609 "Walvoil S.p.A." 608 "Gale Banks Engineering" 607 "Knappco/Civacon" 606 "Intellian Technologies" 605 "Aventics GmbH" 604 "Indexator Rototilt Systems AB" 603 "Kereval" 602 "Nomad Digital Ltd." 601 "Navitas Systems" 600 "Aquatic AV" 599 "Spudnik Equipment Co, LLC" 598 "ABB Turbo Systems Ltd" 597 "Hydac Filter Systems GmbH" 699 "Harman International Industries" 698 "Scorpion Technologies Ltd." 697 "흈� AB" 696 "DRS Network & Imaging Systems, LLC (DRS Technologies)" 695 "Weldon Technologies" 694 "GasTOPS Ltd." 693 "Agility Fuel Solutions (formerly Agility Fuel Systems)" 692 "Tanhay Corporation" 691 "Digitroll Agricultural Electronics" 690 "LINAK A/S" 689 "Aarcomm Systems Inc" 688 "Rockford Corp" 687 "Flight Systems, Inc." 686 "Taigene Electric Machinery Corp." 685 "ANEDO Ltd." 684 "KEB" 683 "Fosen Elektro" 682 "Eckelmann AG" 681 "BEDIA Motorentechnik GmbH & Co. KG" 680 "AMVAC Chemical Corporation" 679 "Cimco Marine AB" 678 "KeepTruckin, Inc." 677 "DSA Daten- und Systemtechnik GmbH" 676 "Danfoss IXA A/S" 675 "Kawasaki Motors Corp., USA" 674 "Yara International ASA" 673 "Caruelle Nicolas" 672 "OPTIMA Concept" 671 "Innovative Controls Inc." 670 "STEMCO LP" 669 "Quantum Fuel Systems Technologies Worldwide, Inc" 668 "MacDon Industries Ltd." 667 "Bartec" 666 "Schaeffler Technologies AG & Co., KG" 665 "Gebr. Bode GmbH & Co. KG" 664 "Level Developments Ltd" 663 "Delta Systems, Inc" 662 "Kissling Elektrotechnik GmbH" 661 "SPAL Automotive S.r.l." 660 "Auto-Gaz Centrum" 659 "Data Panel Corp." 658 "Shenzhen Jiuzhou Himunication Technology Co., Ltd" 657 "Terzo Power Systems" 656 "PRO SOLUS do Brasil" 655 "Genge & Thoma AG" 654 "Kohler Power Systems, Detroit Engine Development Center (DEDC)" 653 "AEV, spol. s r. o." 652 "MicroControl GmbH & Co. KG" 596 "Brunelco Electronic Innovators B.V." 595 "CustomWare" 594 "Kongsberg Automotive" 593 "Sensata Technologies" 592 "tecsis GmbH" 591 "United States Coast Guard" 590 "ARGO-HYTOS GMBH" 589 "MICO, Inc." 588 "Vignal Systems" 587 "JCA Electronics" 586 "Suzuki Motor Corp" 585 "Industrial Electronic Controls" 584 "CarMedialab GmbH" 583 "Yachtcontrol" 582 "Innovative Software Engineering" 581 "V�derstad - Verken AB" 580 "San Jose Technology, Inc." 579 "KVH Industries, Inc." 578 "advanSea" 577 "Denchi Power Ltd  (formerly ABSL Power Solutions Limited)" 576 "Vectia" 575 "Lytx" 574 "Vishay Precision Group" 573 "Orolia Ltd" 572 "Fasse Valves" 571 "Marinecraft Co., Ltd." 570 "frenzel + berg electronic GmbH & Co. KG" 569 "LORD MicroStrain Sensing Systems" 568 "Makersan Ltd. Co." 567 "Lithiumstart LLC" 566 "Geode Technology, Inc." 565 "Micro-Trak Systems, Inc." 564 "Auto Power Electronic" 563 "LOHR Sistemas Eletronicos LTDA" 562 "Bombardier Transportation GmbH" 561 "b-plus GmbH" 560 "Iowa State University, Agricultural and Biosystems Engineering" 559 "Four Peaks Navigation" 558 "Davis Instruments Corp." 557 "Rockson Automation GmbH" 556 "Doosan Infracore Norway" 555 "Sasaki Corporation" 554 "iris-GmbH infrared & intelligent sensors" 553 "KIB Electronics" 552 "Matsuyama Plow Mfg Co, Ltd" 551 "Wexler CSD Ltd." 550 "SUN-A Corporation" 549 "ROAD Deutschland GmbH" 548 "TM4 Inc." 547 "Thomson Linear LLC" 546 "Maruyama Mfg Co, Inc." 545 "GS Hydraulics" 544 "Au Group Electronics" 543 "BAUER Maschinen GmbH" 542 "Dinamica Generale s.p.a." 541 "Total Fire Systems, Inc." 540 "Dinex A/S" 539 "Mobileview" 538 "Crop Ventures, Inc." 537 "Schrader Electronics Ltd." 536 "SSI Technologies" 535 "MOTORPAL, a.s." 534 "Webasto Thermo & Comfort SE" 533 "Doran Manufacturing, LLC" 532 "Onwa Marine Electronics Co Ltd." 531 "Genge & Thoma AG" 530 "NMEA" 529 "National Instruments Korea" 528 "Hoganas AB, Electric Drive Systems" 527 "GKN Walterscheid GmbH" 526 "LOFA Industries, Inc" 525 "Rust Sales INC" 524 "Vomax Instrumentation Pty. Ltd." 523 "Reggio Emilia Innovazione" 522 "Nebraska Tractor Test Laboratory" 521 "Clever Devices Ltd." 520 "Trapeze" 519 "Peeters Landbouwmachines b.v." 518 "Transas USA Inc." 517 "Noland Engineering" 516 "AVAT Automation GmbH" 515 "GINAF Trucks Nederland B.V." 514 "DISTek Integration, Inc." 513 "FarmscanAg" 512 "Inpower LLC" 511 "Sulky" 510 "Marinesoft Co. Ltd" 509 "MOTORTECH GmbH" 508 "Transtech Innovations" 507 "ISOBUS Test Center" 506 "IHI STAR Machinery Corporation" 505 "Yetter Farm Equipment" 504 "Vesper Marine" 503 "Naviop S.R.L." 502 "Attwood Corporation" 501 "Agrotronix S.A." 500 "Oxbo International Corporation" 499 "LCJ Capteurs" 498 "Innovative Design Solutions, Inc." 497 "SENTRON Sistemas Embarcados" 496 "W. Gessmann GmbH" 495 "HOLMER Maschinenbau GmbH" 388 "Innomatix, LLC" 387 "Orscheln Products, LLC" 386 "JLG Automation BVBA" 385 "Johnson Outdoor Marine Electronics" 384 "Camano Light" 383 "MCL Industries" 382 "National Agriculture and Food Research Organization" 381 "B & G" 380 "Suntech International Ltd." 379 "Yamabiko Corporation" 378 "Glendinning Marine Products" 377 "ifm electronic gmbh" 376 "Quake Global" 375 "Williams Controls Inc." 374 "Northern Lights, Inc." 373 "Electronic Design Inc." 372 "Delphi" 371 "Heinzmann GmbH & Co. KG" 370 "Rolls-Royce Marine AS" 369 "Power Torque Engineering Ltd" 368 "HANSENHOF_electronic" 367 "Fliegl Agrartechnik" 366 "Viewnyx Corp." 365 "Digi-Star, LLC" 364 "OEM Controls Inc." 363 "BEI Duncan" 362 "Poettinger Landtechnik GmbH (formerly Alois Poettinger Maschinenfabrik GmbH)" 361 "InMach" 360 "HJS Emission Technology GmbH & Co KG   (formerly HJS Fahrzeugtechnik GmbH & Co KG)" 359 "Ludwig Bergmann GmbH" 358 "Victron Energy BV" 357 "Hardi International A/S" 356 "Fischer Panda Generators, Inc" 355 "Mastervolt International B.V." 354 "Junkkari OY" 353 "Hegemon Electronics, Inc." 352 "SAME DEUTZ-FAHR GROUP S.p.A." 351 "Thrane & Thrane" 350 "Noris Marine Systems GmbH & Co KG" 349 "Suonentieto" 348 "Amazonen Werke H. Dreyer" 347 "Honeywell" 346 "Control Solutions" 345 "Korean Maritime University" 344 "Parvus Corporation" 343 "Baumer Group" 342 "THOMAS MAGNETE GmbH" 341 "Boning GmbH & Co" 340 "Continental AG" 234 "Mondial electronic GmbH" 233 "Yacht Monitoring Solutions Inc." 232 "TSD Integrated Controls" 231 "Topcon Positioning Systems, Inc." 230 "Saucon Technologies" 229 "Garmin International Inc." 228 "Unused (formerly ZF Marine Electronics)" 227 "Lykketronic A/S" 226 "Monaco Coach Corporation" 225 "SKF" 224 "EMMI Network, S.L." 223 "Vaueo Retarder Co., Ltd." 222 "Generac Power Systems, Inc." 221 "SiE" 220 "Beede Electrical Instrument Company, Inc" 219 "Cat OEM Solutions" 218 "Gits Manufacturing Company" 217 "RM Michaelides Software & Elektronik GmbH" 216 "Paneltronics Inc." 215 "Aetna Engineering/Fireboy-Xintex" 214 "MC elettronica Srl" 213 "CNH Belgium N.V." 212 "Sure Power Industries, Inc" 211 "DNA Group" 210 "Iteris, Inc." 209 "Bell Equip. Co. SA (PTY) LTD" 208 "Drew Technologies, Inc" 207 "Otto Engineering" 206 "port GmbH" 205 "SmarTire Systems Inc" 204 "The Morey Corporation" 203 "MILtronik GmbH" 202 "Curtis Instruments, Inc" 201 "Disenos y Tecnologia S.A." 200 "MGM Brakes" 199 "ACTIA Group (formerly Actia Corp)" 198 "Mystic Valley Communications" 197 "Mechron Power Systems" 196 "LEMKEN GmbH & Co KG" 195 "General Engine Products" 194 "TriMark Corporation" 193 "Jeppesen Marine" 192 "Floscan" 191 "XRS Corporation (formerly XATA Corporation)" 190 "Hella KGaA Hueck & Co" 189 "QUALCOMM" 188 "EMP Corp" 187 "Air-Weigh" 186 "Altronic, Inc" 185 "Beede Electrical Instrument Company" 494 "Synerject" 493 "Watcheye" 492 "Inergy Automotive Systems" 491 "Penny and Giles Ltd" 490 "QuikQ" 489 "Appareo Systems, LLC" 488 "The Charles Machine Works, Inc." 487 "DSE Test Solutions A/S" 486 "Westport Innovations Inc." 485 "MATT automotive" 484 "Headsight Inc." 483 "Valeo" 482 "Tricon Electronics" 481 "Chetco Digital Instruments" 480 "EnerDel, Inc." 479 "Vapor Bus International" 478 "OceanSat BV" 477 "OilQuick AB" 476 "Hummingbird Marine Electronics" 475 "GME" 474 "Persen Technologies Inc." 473 "Boss Industries, Inc." 472 "Tenneco Inc." 471 "Sea Cross Marine AB" 470 "SI-TEX Marine Electronics" 469 "RA Consulting GmbH" 468 "Tyco Fire Protection Products" 467 "Lely Industries N.V." 466 "Veethree Electronics and Marine LLC" 465 "Ashcroft Inc" 464 "Leach International Corporation" 463 "PROBOTIQ" 462 "IHI Shibaura Machinery Corporation" 461 "HAWE Hydraulik SE" 460 "San Giorgio S.E.I.N." 459 "Alltek Marine Electronics Corp" 458 "Control Solutions, Inc." 457 "RUSELPROM-ElectricDrive Ltd" 456 "General Kinetics" 455 "ADZ NAGANO GmbH" 454 "NGK Spark Plug Co. Ltd" 453 "Cooper Bussmann" 452 "WIKA Alexander Wiegand SE & Co. KG" 451 "Parker Hannifin Corp" 450 "Dycor Technologies Ltd." 449 "Polaris Industries Inc" 448 "Stanadyne Corporation, Electronics Systems" 447 "Great Plains Mfg." 446 "CertTech, L.L.C." 445 "KAT MECHATRONIC, Electronic Product Division" 444 "ITT Power Solutions" 443 "SignalQuest, Inc." 442 "Horsch Maschinen GmbH" 441 "PTG Reifendruckregelsysteme GmbH" 440 "Cummins Power Generation" 439 "Hyundai Heavy Industries" 438 "Comar Systems Ltd" 437 "Digital Yacht Limited" 436 "Kinze Manufacturing" 435 "Zunhammer GmbH" 434 "Stored Energy Systems" 433 "Rowe Electronics" 432 "S&A Systems, Inc." 431 "Tohatsu Corporation" 430 "Auteq Telematica S.A." 429 "Rota Engineering Ltd." 425 "Methode Electronics Inc, MDI" 424 "Odyne LLC" 423 "BSM Wireless, Inc." 422 "True Heading AB" 421 "Vertex Standard Co, Ltd" 420 "Vermeer Corporation, ACS Group" 419 "Fusion Electronics Ltd" 418 "Intellistick Inc" 417 "KZValve" 416 "Kubota Corporation" 415 "Valid Manufacturing Ltd." 414 "Cattron Group International" 413 "Datapross Nijbroek bv" 412 "WebTech Wireless Inc." 411 "Hy-Drive Technologies Ltd." 410 "COBO S.p.A. Divisione 3B6" 409 "Transfluid S.r.L." 408 "Corvus Energy Ltd." 407 "Comtech Mobile Datacom" 406 "Vecima Networks Inc." 405 "Wema System AS" 404 "Com Nav Marine Ltd" 403 "Trackwell ADS, Inc." 402 "Simma Software, Inc." 401 "Torqeedo GmbH" 400 "Livorsi Marine" 399 "ISEKI & Co., Ltd." 398 "Hilite International" 397 "Sanyo-kiki Co Ltd." 396 "Beyond Measure" 395 "GENTEC S.R.L." 394 "Capi 2 Nederland BV" 393 "Harvest Tec, Inc" 392 "Tianyuan Technology Co Ltd." 391 "Electronic Design for Industry, Inc" 390 "Partech Inc." 389 "Benchmark Electronics, Minnesota Division" 339 "Competence Center ISOBUS e.V." 338 "GRAF-SYTECO" 337 "Carraro S.p.A." 336 "APE s.r.o." 335 "Evo Electric Ltd" 334 "Takata-Petri AG" 333 "Hadley Products Corporation" 332 "HWH Corporation" 331 "Horton, Inc." 330 "Kidde Aerospace and Defense" 329 "Deif A/S" 328 "Qwerty Electronik AB" 327 "Sonceboz SA" 326 "Akron Brass Company" 325 "ASM Automation Sensorik Messtechnik GmbH" 324 "Snap-on Diagnostics" 323 "Mobileye Vision Technologies Ltd." 322 "MICHENKA s.r.o." 321 "Ultra Electronics, Electrics" 320 "Miedema Landbouwwerktuigenfabriek B.V." 319 "Cadec Global" 318 "SAT Plan" 317 "Navtronics Bvba" 316 "ITT Flow Control" 315 "Icom Incorporated" 314 "CSM GmbH" 313 "Ilmor Engineering, Inc." 312 "Lectronix, Inc." 311 "Patrick Power Products" 310 "TECNORD srl" 309 "Krauss-Maffei Wegmann GmbH & Co. KG" 308 "Cyntrx" 307 "MAS Technologies" 306 "Sleipner Motor AB" 305 "NovAtel Inc" 304 "EmpirBus AB" 303 "CTS Corporation" 302 "Nissin Kogyo Co., LTD" 301 "Parker Hannifin (UK) Ltd FDE group" 300 "Systron Donner Automotive" 299 "Rauch" 298 "Holley Performance" 297 "Zonar Systems Inc" 296 "micro dynamics GmbH" 295 "BEP Marine" 294 "Grayhill Inc." 293 "Spyder Controls Corp." 292 "IKUSI - Angel Iglesias S.A." 291 "Groeneveld Transport Efficiency BV" 290 "Kuebler GmbH" 289 "Watlow" 288 "Mitsubishi FUSO Truck & Bus Corp." 287 "NTech Industries, Inc" 286 "Coelmo srl" 285 "Sea Recovery Corp" 284 "Mobile Tech Chile" 283 "CWF Hamilton & Co Ltd" 282 "Medallion Instrumentation Systems" 281 "Precision Governors LLC" 280 "Leica Geosystems Pty Ltd" 279 "Geometris LP" 278 "Takata Electronics" 277 "LHP Telematics" 276 "Aqua-Hot Heating Systems" 275 "Navico Egersund AS" 274 "LTW Technology Co., LTD" 273 "Active Research Limited" 272 "Gross Mechanical Laboratories, Inc" 271 "Cole Hersee" 270 "Tennant" 269 "Saft America Inc.,  Space & Defense Division" 268 "Accurate Technologies" 267 "Red Lion Controls, Inc" 266 "International Thermal Research Ltd" 265 "MTS Sensor Technologie GmbH" 264 "Autolync" 263 "IMMI" 262 "HydraForce, Inc" 261 "Red Dot Corporation" 260 "Reichhardt GmbH Steuerungstechnik" 259 "Jetter AG" 258 "ARAG" 257 "Honda Motor Co., Ltd" 256 "Tyco Electronics AMP" 255 "MEAS France" 254 "GE Sensing" 253 "Mobile Control Systems" 252 "Sensor-Technik Wiedemann GmbH" 251 "German Agricultural Society, Test Center (DLG)" 250 "Kuhn Group" 249 "Schaltbau GmbH" 248 "Cooper Standard Automotive Active Systems Group" 247 "ePULSE" 246 "Class 1, Inc" 245 "Capstan Ag Systems, Inc." 244 "Techno-Matic" 243 "eRide, Inc." 242 "Kokusandenki Co. Ltd" 241 "Schneider Automation SAS" 240 "Vanair Mfg" 239 "May & Scofield Ltd" 238 "ZF Friedrichshafen AG" 237 "Agtron Enterprises Inc" 236 "NORAC Systems International Inc" 235 "SailorMade Marine Telemetry - Tetra Technology Ltd." 184 "EIA Electronics" 183 "KDS Controls, Inc" 182 "Vehicle Systems Engineering B.V." 181 "Coretronics, Inc." 180 "Smart Power Systems" 179 "TeeJet Technologies Springfield (formerly Midwest Technologies Illinois, LLC)" 178 "Continental Automotive GmbH (formerly Siemens VDO Automotive AG)" 177 "Diagnostic Systems Associates" 176 "Moritz Aerospace" 175 "Veris Technologies, Inc." 174 "AB Volvo Penta" 173 "Ryeso, Inc." 172 "Yanmar Co., Ltd. (formerly Yanmar Marine USA)" 171 "Wachendorff Elektronik GmbH & Co. KG" 170 "Computronics Corporation Ltd." 169 "Marlin Technologies Inc." 168 "Xantrex" 167 "JLG Industries Inc" 166 "John Deere Electronic Solutions (formerly Phoenix International)" 165 "CPAC Systems AB" 164 "MTU Friedrichshafen GmbH (formerly DaimlerChrysler Off-Highway)" 163 "BRP Inc." 162 "Axiomatic Technologies" 161 "Offshore Systems (UK) Ltd" 160 "Nido" 159 "NTech Industries Inc" 158 "Firestone Industrial Products Company" 157 "ISSPRO Inc." 156 "ITT Industries - Cannon" 155 "Vetronix Corporation" 154 "Westerbeke Corporation" 153 "Woodward, Industrial Controls Division" 152 "elobau GmbH & Co. KG" 151 "Raven Industries, Inc." 150 "Fleetguard" 149 "Holset" 148 "Blue Water Data, Inc." 147 "Nautibus electronic GmbH" 146 "Maxima Technologies" 145 "MurCal Controls" 144 "Mercury Marine" 143 "W. Gmeiner GmbH & Co." 142 "TRW Automotive (Commercial Steering Systems)" 141 "Thales Navigation Ltd." 140 "Lowrance Electronics, Inc." 127 "Holland USA" 126 "Driver Tech" 125 "Nevada Automotive Test Center" 124 "Hydac Electronic" 123 "Basler Electric" 122 "FG Wilson (Engineering) Limited" 121 "HED (Hydro Electronic Devices, Inc.)" 120 "RDS Technology Ltd" 119 "IntegriNautics젨" 118 "Intron GmbH" 117 "HUSCO International" 116 "BEELINE Technologies" 115 "NACCO Materials Handling Group, Inc." 114 "EControls, Inc." 113 "Stress-Tek, Inc." 112 "MECALAC" 111 "Maschinenfabrik Bernard Krone GmbH" 110 "EPIQ Sensor-Nite" 109 "TeeJet Technologies Denmark (formerly LH Technologies ApS)" 108 "WTK-Elecktronik GmbH" 107 "Grimme Landmaschinen GmbH & Co. KG" 106 "BAE Systems Controls, Inc." 105 "Kiepe Elektrik GmbH & Co. KG" 104 "CLAAS KGaA mbH (formerly CLAAS Selbstfahrende Erntemaschinen GmbH)" 103 "CLAAS E-Systems KGaA mbH & Co. KG (formerly CLAAS Agrosystems GmbH & Co. KG)" 102 "AGCO (formerly AGCO GmbH & Co.)" 101 "Sensoria" 100 "VDO Technik AG" 99 "International Transmissions Ltd (ITL)" 98 "Mueller-Elektronik GmbH & Co" 97 "Ag Leader Technology, Inc." 96 "Mech@tronic IT GmbH" 95 "Pacific Insight Electronics Corp." 94 "CNH Industrial N.V. (formerly CNH Global N.V.)" 93 "Perkins Engines Company Ltd." 92 "Ag-Chem Equipment Co., Inc." 91 "BSG Bodensee Steuergeraete GmbH" 90 "Knorr-Bremse SfN GmbH" 89 "Kverneland Group, Electronics Division" 88 "Hemisphere GPS Inc (formerly Satloc Precision GPS)" 87 "J.C. Bamford Excavators Ltd (JCB)" 86 "C. E. Niehoff & Company" 85 "Kohler Co" 84 "New Holland UK Limited" 83 "Bendix VORAD Technologies (formerly Eaton VORAD Technologies)" 82 "Bobcat/Ingersoll-Rand (formerly Melroe/Ingersoll-Rand)" 81 "Fire Research Corp." 80 "Twin Disc, Inc." 79 "Daimler Benz AG - Engine Division (PBM)" 78 "Frank W. Murphy Manufacturing, Inc" 77 "Deere Power Systems Group" 76 "unused (formerly Deere & Co, Construction Division)" 75 "Deere & Co, Agricultural Division" 74 "Eaton Axle-Brake Division" 73 "LeTourneau, Inc." 72 "Sisu Corporation" 71 "Vansco Electronics Ltd." 70 "Flex-coil Limited" 69 "Trimble Navigation" 68 "Scania" 67 "John Deere Coffeyville Works (formerly Funk Manufacturing Company)" 66 "John Deere Construction Equipment Division" 65 "MAN Nutzfahrzeuge AG" 64 "Unused (formerly SpectraPrecision Laserplane, then SpectraPhysics)" 63 "ZF Industries Inc." 62 "Wabco" 61 "Volvo Truck Corp." 60 "Volvo Trucks North America Inc." 59 "VES Inc." 58 "SPX Corporation, OTC Div" 57 "Danfoss  (formerly Sauer Sundstrand Co, then Sauer-Danfoss Co)" 56 "SAIC" 55 "Ryder System Inc." 54 "Meritor Wabco" 53 "Continental Automotive Systems US, Inc. (formerly Rockwell Land Transportation)" 52 "Meritor Automotive, Inc. (formerly Rockwell Automotive)" 51 "Robert Bosch GmbH" 50 "Robert Bosch Corp" 49 "RE America Inc." 48 "Pollak Alphabet" 47 "Phillips Semiconductor" 46 "Noregon Systems, Inc  (formerly Parasoft Computing Solutions)" 45 "PACCAR" 44 "Nippondenso Co. Ltd." 43 "International Truck and Engine Corporation - Vehicle Electronics (formerly Navistar Intl Trans Corp.)" 42 "International Truck and Engine Corporation - Engine Electronics  (formerly Navistar Intl Trans Co., Engine Electronics)" 41 "Motorola Inc." 40 "Motorola AIEG Inc." 39 "Microfirm Inc." 38 "Micro Processor Systems Inc." 37 "Mack Trucks Inc." 36 "Lucas Ind." 35 "Kenworth Truck Co." 34 "Kelsey Hayes Co." 33 "John Deere" 32 "Jacobs Vehicle Systems" 31 "J Pollak Corp" 30 "Isuzu Motors Ltd" 29 "Hino Motors Ltd." 28 "Grote Ind. Inc." 27 "GMC" 26 "General Motors Corp, Service Technology Grp" 25 "Daimler Trucks North America LLC (formerly Freightliner LLC)" 24 "Ford Motor Co., Vehicle Controls" 23 "Ford Motor Co., Heavy Truck" 22 "Ford Motor Co., Electronic Concepts & Systems" 21 "Echlin Inc., Midland Brake Inc." 20 "Eaton Ltd" 19 "Eaton Corp. Trucking Info Services" 18 "Eaton Corp, Transmission Div." 17 "Eaton Corp, Corp Res & Dev" 16 "Eaton Corp" 15 "DICKEY-john Corporation" 14 "Detroit Diesel Corporation" 13 "Delco Electronics" 12 "Deere & Company, Precision Farming" 11 "Dearborn Group Inc." 10 "Cummins Inc (formerly Cummins Engine Co)" 9 "Chrysler Corp." 8 "Caterpillar Inc." 7 "Case Corp." 6 "Berifors Electronics AB" 5 "AMP Inc." 4 "Ametek-Dixson" 3 "Ametek, US Gauge Division" 2 "Allison Transmission, Inc." 1 "Bendix Commercial Vehicle Systems LLC (formerly Allied Signal Inc.)" 0 "Reserved" ;
VAL_ 2566838526 VehicleSystem5 127 "Not Available" 0 "Ind. Process Control Stationary" ;
VAL_ 2566838526 VehicleSystem4 125 "Entertainment" 120 "Display" 85 "External Environment" 75 "Sensor Communication Interface" 35 "Electrical Generation" 100 "Deck, Cargo and Fishing Equipment" 90 "Internal Environment" 80 "Instrumentation/General Systems (deprecate)" 70 "Communications" 60 "Navigation" 50 "Propulsion" 40 "Steering and Control Surfaces" 30 "Electrical Distribution" 25 "Inter/Intranetwork Device" 20 "Safety Systems" 10 "System Tools" 127 "Not Available" 0 "Non-specific System" ;
VAL_ 2566838526 VehicleSystem3 8 "Grader" 7 "Four Wheel Drive Loader" 6 "Forklift" 5 "Excavator" 4 "Crawler" 3 "Backhoe" 2 "Articulated Dump Truck" 1 "Skid Steer Loader" 127 "Not Available" 0 "Non-specific System" ;
VAL_ 2566838526 VehicleSystem2 25 "Slurry Applicators" 24 "Utility Vehicles" 23 "Mulchers" 22 "Timber Processing Machines" 21 "Timber loaders" 20 "Forwarders" 19 "Timber Harvesters" 17 "Sensor Systems" 16 "Skidder" 15 "Earth Work" 14 "Special Crops" 13 "Powered Auxiliary Device" 12 "Farm Yard Operations" 11 "Transport/Trailer" 10 "Irrigation" 9 "Forage" 8 "Root Harvesters" 7 "Harvesters" 6 "Sprayers" 5 "Fertilizers" 4 "Planters/Seeders" 3 "Secondary Tillage" 2 "Tillage" 1 "Tractor" 127 "Not Available" 0 "Non-specific System" ;
VAL_ 2566838526 VehicleSystem1 2 "Trailer" 1 "Tractor" 127 "Not Available" 0 "Non-specific System" ;
VAL_ 2565799678 IndustryGroup 6 "Reserved for SAE" 7 "Reserved for SAE" 5 "IndustrialProcessCtrlStationary" 4 "Marine" 3 "Construction" 2 "Agricultural and Forestry" 1 "On-Highway" 0 "Global" ;
VAL_ 2565799678 Function 127 "Reserved" 126 "Reserved" 125 "Reserved" 124 "Reserved" 123 "Reserved" 122 "Reserved" 121 "Reserved" 120 "Reserved" 119 "Reserved" 118 "Reserved" 117 "Reserved" 116 "Reserved" 115 "Reserved" 114 "Reserved" 113 "Reserved" 112 "Reserved" 111 "Reserved" 110 "Reserved" 109 "Reserved" 108 "Reserved" 107 "Reserved" 106 "Reserved" 105 "Reserved" 104 "Reserved" 103 "Reserved" 102 "Reserved" 101 "Reserved" 42 "Water Pump Control" 41 "Lighting - Operator Controls" 40 "Seat Control" 39 "Ignition Control Module" 38 "Tire Pressure Control" 37 "Cab Controller" 36 "Pneumatic - System Controller" 35 "Suspension - System Controller" 34 "Hydraulic Pump Controller" 33 "System Monitor" 32 "Headway Controller" 31 "Propulsion Battery Charger" 30 "Management Computer" 29 "Virtual Terminal (in cab)" 28 "Off Vehicle Gateway" 27 "Power TakeOff (Secondary or Front)" 26 "Body Controller" 25 "Network Interconnect ECU" 24 "Vehicle Security" 23 "Vehicle Navigation" 22 "Aerodynamic Control" 21 "Cab Climate Control" 20 "Trip Recorder" 19 "Instrument Cluster" 18 "Suspension - Drive Axle" 17 "Suspension - Steer Axle" 16 "Steering Controller" 15 "Fuel System" 14 "Cruise Control" 13 "Retarder - Driveline" 12 "Retarder - Engine" 11 "Brakes - Drive Axle" 10 "Brakes - Steer Axle" 9 "Brakes - System Controller" 8 "Axle - Drive" 7 "Axle - Steering" 6 "Power TakeOff - (Main or Rear)" 5 "Shift Control/Console" 4 "Battery Pack Monitor" 3 "Transmission" 2 "Electric Propulsion Control" 1 "Auxiliary Power Unit (APU)" 0 "Engine" 100 "Reserved" 99 "Reserved" 98 "Reserved" 97 "Reserved" 96 "Reserved" 95 "Reserved" 94 "Reserved" 93 "Reserved" 92 "Reserved" 91 "Reserved" 90 "Reserved" 89 "Reserved" 88 "Reserved" 87 "Reserved" 86 "Reserved" 85 "Reserved" 84 "Reserved" 83 "Reserved" 82 "Reserved" 81 "Reserved" 80 "Reserved" 79 "Reserved" 78 "Fire Suppression System" 77 "Fuel Properties Sensor" 76 "Temperature Sensor" 75 "Supplemental Fan" 74 "Lubrication System" 73 "Rollover Detection Control" 72 "Coolant Valve Controller" 71 "Transfer Case Control" 70 "Auxiliary Regeneration Device" 69 "Engine Emission Aftertreatement System" 68 "Aftertreatment system gas measurement" 67 "Electrical System Controller" 66 "I/O Controller" 65 "Gas Flow Measurement" 64 "Endurance Braking" 63 "Engine Valve Controller" 62 "On-Board Diagnostic Unit" 61 "File Server/Printer" 60 "Cab Display" 59 "Starter" 58 "Fan Drive Control" 57 "Steering Column Unit" 56 "Communications Unit, Radio" 55 "Communications Unit, Satellite" 54 "Communications Unit, Cellular" 53 "Alternator/Charging System" 52 "Chassis Controller" 51 "Forward-Looking Collision Warning System" 50 "Auxiliary Heater" 49 "Clutch/Converter Control" 48 "Ramp Control" 47 "Information System Controller" 46 "Oil Sensor Unit" 45 "Vehicle Dynamic Stability Control" 44 "Exhaust Emission Control" 43 "Transmission Display" ;
VAL_ 2565799678 ManufacturerCode 139 "Caterpillar Trimble Control Technologies (CTCT), LLC" 138 "Georg Fritzmeier GmbH & Co. KG" 137 "Maretron" 136 "Komatsu Ltd" 135 "Airmar Technology Corporation" 134 "Iris Technology Ltd" 133 "Bucher Schoerling GmbH" 132 "Mulag-Fahrzeugwerk" 131 "ITT Industries" 130 "Nido - Universal Machines B.V." 129 "OMNEX Control Systems Inc." 128 "Gerhard Duecker GmbH & Co. KG" 1863 "Thomas G. Faria Co." 1862 "Sanshin" 1861 "Vector North America (formerly Vector Cantech)" 1860 "MMP" 1859 "Kvasar AB" 1858 "Litton" 1857 "Simrad" 1856 "Trimble" 1855 "Furuno USA" 1854 "Northstar Technologies" 1853 "Japan Radio Co" 1852 "Navionics" 1851 "RayMarine" 1850 "Seastar Solutions (formerly Teleflex)" 896 "NextFour Solutions Ltd" 895 "Peloton Technology" 894 "Rhodan Marine Systems of Florida LLC" 893 "KlinkTechnics Ltd." 892 "Mectronx Corp" 891 "CarrierWeb" 890 "L3 Technologies, Inc." 889 "SANY America Inc" 888 "Carma Systems Inc" 887 "Hyperdrive Innovation Limited" 886 "Hitachi Zosen Corporation" 885 "SICK Stegmann GmbH" 884 "Sure Grip Controls Inc." 883 "Swift Navigation, Inc." 882 "BHTronik GmbH & Co. KG" 881 "Sovema" 880 "Revision Military" 879 "PG쟕rionic,쟅nc." 878 "FOTON" 877 "SICK ATech GmbH" 876 "SUCO Robert Scheuffele GmbH & Co. KG" 875 "Salvarani S.r.l." 874 "MTA S.p.A." 873 "Garnet Instruments Ltd." 872 "K�hlig Antriebstechnik GmbH" 871 "Superior Tech Inc" 870 "Textron Fleet Management" 869 "Intercomp" 868 "Data Panel Corp" 867 "Skeleton Technologies" 866 "Netradyne, Inc." 865 "MyEasyFarm" 864 "Streamline Transportation Technologies Inc." 863 "SMAG" 862 "Prospec Electronics" 861 "Adel System S.r.l." 860 "Michelin" 859 "Valor" 858 "Littelfuse" 857 "Zoomlion Heavy Industry NA, Inc" 856 "FarmFacts GmbH" 855 "Toshiba Infrastructure Systems & Solutions Corporation" 854 "GEMAC Chemnitz GmbH" 853 "Teledyne RESON BV" 852 "Velvac Inc" 851 "Novotechnik Messwertaufnehmer OHG" 850 "Geoprospectors GmbH" 849 "MTS Maschinentechnik Schrode AG" 848 "ningupex" 847 "Oceanvolt" 846 "L3 Magnet-Motor" 845 "GMB G�strower Maschinenbau GmbH" 844 "FELL AS" 843 "Hendrickson Truck Commercial Vehicle Systems" 842 "DigiDevice Srl" 841 "Agra-GPS" 840 "E.S.T.E. srl" 839 "Indexator Rotator Systems AB" 838 "Teamsurv Ltd" 837 "Famic Technologies Inc." 836 "Signature4" 835 "PetTrack Ltd." 834 "Pioneer Microsystems, Inc." 833 "Electrum Automation AB" 832 "Heizomat Ger�tebau-Energiesysteme GmbH" 831 "DOK-ING Ltd." 830 "Ultra Motion LLC" 829 "Drov Technologies, Inc." 828 "AgriBrink Inc." 827 "INmatix Technology Group Ltd" 826 "Lewmar Marine Inc" 825 "BPW Hung�ria" 824 "Undheim Systems AS" 823 "ACEINNA, Inc (formerly MEMSIC, Inc)" 822 "Bren-Tronics, Inc." 821 "Thorsen Teknik A/S" 820 "DIaLOGIKa Gesellschaft fuer angewandte Informatik mbH" 819 "Preco Electronics" 818 "HGNSS" 817 "TE Connectivity Sensor Solutions" 816 "UniStrong" 815 "FLIR Systems, Inc." 814 "Soltec Soluzioni Tecnologiche Srl" 813 "Thales Suisse SA" 812 "Torch Technologies" 811 "Blue Water Desalination" 810 "Dutch Power Company" 809 "HMS Industrial Networks AB" 808 "RIMEX Supply Ltd." 807 "Schneider-Electric" 806 "Charge Automotive Ltd" 805 "Gundersen & L�ken AS" 804 "ASA Electronics" 803 "Gill Sensors & Controls Limited" 802 "SPBI (Bj Technologie)" 801 "LOR Manufacturing Company Inc." 800 "Delta-Q Technologies" 799 "Stillwater Designs and Audio, Inc. - KICKER" 798 "Lumishore Ltd" 797 "Tides Marine" 796 "Canadian Automotive Industries Ltd" 795 "Broyda Enterprises Pty Ltd" 794 "Shihlin Electric & Engineering Corporation" 793 "James Fisher Prolec" 792 "Kostal Mexicana" 791 "AUTEC" 790 "VACALL" 789 "GRADALL" 788 "MoTeC Pty Ltd" 787 "Abertax Technologies Limited" 786 "Johnson Matthey Battery Systems" 785 "Fischer Panda GmbH" 784 "CM Automotive Systems, Inc." 783 "Loup Electronics Inc." 782 "AVR bvba" 781 "Poly-Planar LLC" 780 "AVID Technology Ltd" 779 "RLC Electronic Systems" 778 "Seakeeper Inc." 777 "Ocean Signal Ltd" 776 "HMI Systems LLC" 775 "ZIEHL-ABEGG Automotive GmbH" 774 "Taisho Corporation" 773 "Clarion Corporation of America" 772 "Blink Marine" 771 "Shaw Development, LLC" 770 "MONOSEM" 769 "Trombetta" 768 "Flores Automation, LLC" 767 "Alliance Wireless Technologies Inc." 766 "Epec Oy" 765 "GIGAVAC" 764 "Bednar FMT s.r.o." 763 "AT-Systems BVBA" 762 "ROJ s.r.l." 761 "MITA OLEODINAMICA S.p.A." 760 "Bernecker + Rainer Industrie Elektronik GmbH" 759 "Hydro-Gear" 758 "Banner Engineering Corp." 757 "IMPCO Technologies" 756 "Maschio Gaspardo S.P.A." 755 "Firefly Integrations" 754 "Parker Hannifin Corp., Automation Group" 753 "AIROD Technologies" 752 "Deep Sea Electronics Plc" 751 "Pacific Track" 750 "Joskin SA" 749 "Chart Inc." 748 "ISOTTA" 747 "Agratronix" 746 "SureFire Ag Systems, Inc." 745 "Cidra Corporate Services Inc." 744 "Woosung Engineering Co., Ltd." 743 "Daemyung Elevator Co., Ltd." 742 "EROAD" 741 "Carling Technologies" 740 "e-Traction" 739 "LXNAV d.o.o." 738 "Blue Ink Technologies" 737 "Balluff GmbH" 736 "Terex Aerial Work Platforms - Genie" 735 "AEM Performance Electronics" 734 "REAPsystems" 733 "Intendia S.L." 732 "Gefran S.p.A." 731 "Modine Manufacturing Company" 730 "BERTHOUD AGRICOLE" 729 "Liebherr" 728 "Streumaster / Panien" 727 "Dhoot Transmission Pvt Ltd." 726 "MIDORI PRECISIONS" 725 "Hitachi Construction Machinery Co., Ltd." 724 "Electronic Applications, Inc." 723 "Jabil Inc." 722 "Contelec AG" 721 "Hypro" 720 "WITZ Corporation" 719 "Cojali S. L." 718 "Micronet Inc" 717 "Yacht Devices Ltd" 716 "Eaton Control & Power Conversion Division (CPCD)" 715 "Autonnic Research Ltd" 714 "Kobashi Kogyo Co., Ltd." 713 "US Hybrid Corporation" 712 "LOR Manufacturing Company Inc." 711 "DAS Co., LTD" 710 "Greentronics Ltd." 709 "Marquardt GmbH" 708 "Lars Thrane A/S" 707 "Rochester Gauges Inc" 706 "Shanghai Diesel Engine Corporation Limited" 705 "SVAB Hydraulik AB" 704 "JL Audio, Inc." 703 "Hydro Tab Marine Engineering" 702 "Weichai Power Co., Ltd." 701 "BigRoad Inc." 700 "K-Tec Earthmovers Inc." 651 "Takakita Co, Ltd." 650 "Seiko Epson Corp." 649 "Control-Q BV" 648 "OJSC Ekran" 647 "Siloking" 646 "Veenhuis Machines BV" 645 "esd electronic system design gmbh" 644 "KUS USA" 643 "Bogballe A/S" 642 "Moog / Aspen Motion Technologies" 641 "Diverse Yacht Services" 640 "Power Solutions International" 639 "Startec s.r.l." 638 "KVH Industries, Inc." 637 "Bavaria Yachtbau GmbH" 636 "Divelbiss Corporation" 635 "Argo Tractors S.p.A." 634 "Rocky Research" 633 "TORC Robotics" 632 "Pepperl+Fuchs GmbH" 631 "Reltima" 630 "SmartDrive Systems Inc." 629 "Agri Info Design, Ltd." 628 "Falck Schmidt Defence Systems" 627 "Radio Ocean" 626 "AVL DiTEST GmbH" 625 "Global MRV Inc." 624 "Blackbox Machine Control Pty Ltd" 623 "Xirgo Technologies" 622 "Floyd Bell Inc" 621 "Hagie Manufacturing Company" 620 "Sevcon Ltd." 619 "Right Weigh Load Scales" 618 "Evrard SA" 617 "Zero Emission Vehicles" 616 "SMART-TEC s.r.o." 615 "Networkfleet, Verizon Telematics" 614 "ARLT Technologies GmbH" 613 "HKS Co., Ltd." 612 "Samwon IT" 611 "Esterline" 610 "Trail Tech" 609 "Walvoil S.p.A." 608 "Gale Banks Engineering" 607 "Knappco/Civacon" 606 "Intellian Technologies" 605 "Aventics GmbH" 604 "Indexator Rototilt Systems AB" 603 "Kereval" 602 "Nomad Digital Ltd." 601 "Navitas Systems" 600 "Aquatic AV" 599 "Spudnik Equipment Co, LLC" 598 "ABB Turbo Systems Ltd" 597 "Hydac Filter Systems GmbH" 699 "Harman International Industries" 698 "Scorpion Technologies Ltd." 697 "흈� AB" 696 "DRS Network & Imaging Systems, LLC (DRS Technologies)" 695 "Weldon Technologies" 694 "GasTOPS Ltd." 693 "Agility Fuel Solutions (formerly Agility Fuel Systems)" 692 "Tanhay Corporation" 691 "Digitroll Agricultural Electronics" 690 "LINAK A/S" 689 "Aarcomm Systems Inc" 688 "Rockford Corp" 687 "Flight Systems, Inc." 686 "Taigene Electric Machinery Corp." 685 "ANEDO Ltd." 684 "KEB" 683 "Fosen Elektro" 682 "Eckelmann AG" 681 "BEDIA Motorentechnik GmbH & Co. KG" 680 "AMVAC Chemical Corporation" 679 "Cimco Marine AB" 678 "KeepTruckin, Inc." 677 "DSA Daten- und Systemtechnik GmbH" 676 "Danfoss IXA A/S" 675 "Kawasaki Motors Corp., USA" 674 "Yara International ASA" 673 "Caruelle Nicolas" 672 "OPTIMA Concept" 671 "Innovative Controls Inc." 670 "STEMCO LP" 669 "Quantum Fuel Systems Technologies Worldwide, Inc" 668 "MacDon Industries Ltd." 667 "Bartec" 666 "Schaeffler Technologies AG & Co., KG" 665 "Gebr. Bode GmbH & Co. KG" 664 "Level Developments Ltd" 663 "Delta Systems, Inc" 662 "Kissling Elektrotechnik GmbH" 661 "SPAL Automotive S.r.l." 660 "Auto-Gaz Centrum" 659 "Data Panel Corp." 658 "Shenzhen Jiuzhou Himunication Technology Co., Ltd" 657 "Terzo Power Systems" 656 "PRO SOLUS do Brasil" 655 "Genge & Thoma AG" 654 "Kohler Power Systems, Detroit Engine Development Center (DEDC)" 653 "AEV, spol. s r. o." 652 "MicroControl GmbH & Co. KG" 596 "Brunelco Electronic Innovators B.V." 595 "CustomWare" 594 "Kongsberg Automotive" 593 "Sensata Technologies" 592 "tecsis GmbH" 591 "United States Coast Guard" 590 "ARGO-HYTOS GMBH" 589 "MICO, Inc." 588 "Vignal Systems" 587 "JCA Electronics" 586 "Suzuki Motor Corp" 585 "Industrial Electronic Controls" 584 "CarMedialab GmbH" 583 "Yachtcontrol" 582 "Innovative Software Engineering" 581 "V�derstad - Verken AB" 580 "San Jose Technology, Inc." 579 "KVH Industries, Inc." 578 "advanSea" 577 "Denchi Power Ltd  (formerly ABSL Power Solutions Limited)" 576 "Vectia" 575 "Lytx" 574 "Vishay Precision Group" 573 "Orolia Ltd" 572 "Fasse Valves" 571 "Marinecraft Co., Ltd." 570 "frenzel + berg electronic GmbH & Co. KG" 569 "LORD MicroStrain Sensing Systems" 568 "Makersan Ltd. Co." 567 "Lithiumstart LLC" 566 "Geode Technology, Inc." 565 "Micro-Trak Systems, Inc." 564 "Auto Power Electronic" 563 "LOHR Sistemas Eletronicos LTDA" 562 "Bombardier Transportation GmbH" 561 "b-plus GmbH" 560 "Iowa State University, Agricultural and Biosystems Engineering" 559 "Four Peaks Navigation" 558 "Davis Instruments Corp." 557 "Rockson Automation GmbH" 556 "Doosan Infracore Norway" 555 "Sasaki Corporation" 554 "iris-GmbH infrared & intelligent sensors" 553 "KIB Electronics" 552 "Matsuyama Plow Mfg Co, Ltd" 551 "Wexler CSD Ltd." 550 "SUN-A Corporation" 549 "ROAD Deutschland GmbH" 548 "TM4 Inc." 547 "Thomson Linear LLC" 546 "Maruyama Mfg Co, Inc." 545 "GS Hydraulics" 544 "Au Group Electronics" 543 "BAUER Maschinen GmbH" 542 "Dinamica Generale s.p.a." 541 "Total Fire Systems, Inc." 540 "Dinex A/S" 539 "Mobileview" 538 "Crop Ventures, Inc." 537 "Schrader Electronics Ltd." 536 "SSI Technologies" 535 "MOTORPAL, a.s." 534 "Webasto Thermo & Comfort SE" 533 "Doran Manufacturing, LLC" 532 "Onwa Marine Electronics Co Ltd." 531 "Genge & Thoma AG" 530 "NMEA" 529 "National Instruments Korea" 528 "Hoganas AB, Electric Drive Systems" 527 "GKN Walterscheid GmbH" 526 "LOFA Industries, Inc" 525 "Rust Sales INC" 524 "Vomax Instrumentation Pty. Ltd." 523 "Reggio Emilia Innovazione" 522 "Nebraska Tractor Test Laboratory" 521 "Clever Devices Ltd." 520 "Trapeze" 519 "Peeters Landbouwmachines b.v." 518 "Transas USA Inc." 517 "Noland Engineering" 516 "AVAT Automation GmbH" 515 "GINAF Trucks Nederland B.V." 514 "DISTek Integration, Inc." 513 "FarmscanAg" 512 "Inpower LLC" 511 "Sulky" 510 "Marinesoft Co. Ltd" 509 "MOTORTECH GmbH" 508 "Transtech Innovations" 507 "ISOBUS Test Center" 506 "IHI STAR Machinery Corporation" 505 "Yetter Farm Equipment" 504 "Vesper Marine" 503 "Naviop S.R.L." 502 "Attwood Corporation" 501 "Agrotronix S.A." 500 "Oxbo International Corporation" 499 "LCJ Capteurs" 498 "Innovative Design Solutions, Inc." 497 "SENTRON Sistemas Embarcados" 496 "W. Gessmann GmbH" 495 "HOLMER Maschinenbau GmbH" 388 "Innomatix, LLC" 387 "Orscheln Products, LLC" 386 "JLG Automation BVBA" 385 "Johnson Outdoor Marine Electronics" 384 "Camano Light" 383 "MCL Industries" 382 "National Agriculture and Food Research Organization" 381 "B & G" 380 "Suntech International Ltd." 379 "Yamabiko Corporation" 378 "Glendinning Marine Products" 377 "ifm electronic gmbh" 376 "Quake Global" 375 "Williams Controls Inc." 374 "Northern Lights, Inc." 373 "Electronic Design Inc." 372 "Delphi" 371 "Heinzmann GmbH & Co. KG" 370 "Rolls-Royce Marine AS" 369 "Power Torque Engineering Ltd" 368 "HANSENHOF_electronic" 367 "Fliegl Agrartechnik" 366 "Viewnyx Corp." 365 "Digi-Star, LLC" 364 "OEM Controls Inc." 363 "BEI Duncan" 362 "Poettinger Landtechnik GmbH (formerly Alois Poettinger Maschinenfabrik GmbH)" 361 "InMach" 360 "HJS Emission Technology GmbH & Co KG   (formerly HJS Fahrzeugtechnik GmbH & Co KG)" 359 "Ludwig Bergmann GmbH" 358 "Victron Energy BV" 357 "Hardi International A/S" 356 "Fischer Panda Generators, Inc" 355 "Mastervolt International B.V." 354 "Junkkari OY" 353 "Hegemon Electronics, Inc." 352 "SAME DEUTZ-FAHR GROUP S.p.A." 351 "Thrane & Thrane" 350 "Noris Marine Systems GmbH & Co KG" 349 "Suonentieto" 348 "Amazonen Werke H. Dreyer" 347 "Honeywell" 346 "Control Solutions" 345 "Korean Maritime University" 344 "Parvus Corporation" 343 "Baumer Group" 342 "THOMAS MAGNETE GmbH" 341 "Boning GmbH & Co" 340 "Continental AG" 234 "Mondial electronic GmbH" 233 "Yacht Monitoring Solutions Inc." 232 "TSD Integrated Controls" 231 "Topcon Positioning Systems, Inc." 230 "Saucon Technologies" 229 "Garmin International Inc." 228 "Unused (formerly ZF Marine Electronics)" 227 "Lykketronic A/S" 226 "Monaco Coach Corporation" 225 "SKF" 224 "EMMI Network, S.L." 223 "Vaueo Retarder Co., Ltd." 222 "Generac Power Systems, Inc." 221 "SiE" 220 "Beede Electrical Instrument Company, Inc" 219 "Cat OEM Solutions" 218 "Gits Manufacturing Company" 217 "RM Michaelides Software & Elektronik GmbH" 216 "Paneltronics Inc." 215 "Aetna Engineering/Fireboy-Xintex" 214 "MC elettronica Srl" 213 "CNH Belgium N.V." 212 "Sure Power Industries, Inc" 211 "DNA Group" 210 "Iteris, Inc." 209 "Bell Equip. Co. SA (PTY) LTD" 208 "Drew Technologies, Inc" 207 "Otto Engineering" 206 "port GmbH" 205 "SmarTire Systems Inc" 204 "The Morey Corporation" 203 "MILtronik GmbH" 202 "Curtis Instruments, Inc" 201 "Disenos y Tecnologia S.A." 200 "MGM Brakes" 199 "ACTIA Group (formerly Actia Corp)" 198 "Mystic Valley Communications" 197 "Mechron Power Systems" 196 "LEMKEN GmbH & Co KG" 195 "General Engine Products" 194 "TriMark Corporation" 193 "Jeppesen Marine" 192 "Floscan" 191 "XRS Corporation (formerly XATA Corporation)" 190 "Hella KGaA Hueck & Co" 189 "QUALCOMM" 188 "EMP Corp" 187 "Air-Weigh" 186 "Altronic, Inc" 185 "Beede Electrical Instrument Company" 494 "Synerject" 493 "Watcheye" 492 "Inergy Automotive Systems" 491 "Penny and Giles Ltd" 490 "QuikQ" 489 "Appareo Systems, LLC" 488 "The Charles Machine Works, Inc." 487 "DSE Test Solutions A/S" 486 "Westport Innovations Inc." 485 "MATT automotive" 484 "Headsight Inc." 483 "Valeo" 482 "Tricon Electronics" 481 "Chetco Digital Instruments" 480 "EnerDel, Inc." 479 "Vapor Bus International" 478 "OceanSat BV" 477 "OilQuick AB" 476 "Hummingbird Marine Electronics" 475 "GME" 474 "Persen Technologies Inc." 473 "Boss Industries, Inc." 472 "Tenneco Inc." 471 "Sea Cross Marine AB" 470 "SI-TEX Marine Electronics" 469 "RA Consulting GmbH" 468 "Tyco Fire Protection Products" 467 "Lely Industries N.V." 466 "Veethree Electronics and Marine LLC" 465 "Ashcroft Inc" 464 "Leach International Corporation" 463 "PROBOTIQ" 462 "IHI Shibaura Machinery Corporation" 461 "HAWE Hydraulik SE" 460 "San Giorgio S.E.I.N." 459 "Alltek Marine Electronics Corp" 458 "Control Solutions, Inc." 457 "RUSELPROM-ElectricDrive Ltd" 456 "General Kinetics" 455 "ADZ NAGANO GmbH" 454 "NGK Spark Plug Co. Ltd" 453 "Cooper Bussmann" 452 "WIKA Alexander Wiegand SE & Co. KG" 451 "Parker Hannifin Corp" 450 "Dycor Technologies Ltd." 449 "Polaris Industries Inc" 448 "Stanadyne Corporation, Electronics Systems" 447 "Great Plains Mfg." 446 "CertTech, L.L.C." 445 "KAT MECHATRONIC, Electronic Product Division" 444 "ITT Power Solutions" 443 "SignalQuest, Inc." 442 "Horsch Maschinen GmbH" 441 "PTG Reifendruckregelsysteme GmbH" 440 "Cummins Power Generation" 439 "Hyundai Heavy Industries" 438 "Comar Systems Ltd" 437 "Digital Yacht Limited" 436 "Kinze Manufacturing" 435 "Zunhammer GmbH" 434 "Stored Energy Systems" 433 "Rowe Electronics" 432 "S&A Systems, Inc." 431 "Tohatsu Corporation" 430 "Auteq Telematica S.A." 429 "Rota Engineering Ltd." 425 "Methode Electronics Inc, MDI" 424 "Odyne LLC" 423 "BSM Wireless, Inc." 422 "True Heading AB" 421 "Vertex Standard Co, Ltd" 420 "Vermeer Corporation, ACS Group" 419 "Fusion Electronics Ltd" 418 "Intellistick Inc" 417 "KZValve" 416 "Kubota Corporation" 415 "Valid Manufacturing Ltd." 414 "Cattron Group International" 413 "Datapross Nijbroek bv" 412 "WebTech Wireless Inc." 411 "Hy-Drive Technologies Ltd." 410 "COBO S.p.A. Divisione 3B6" 409 "Transfluid S.r.L." 408 "Corvus Energy Ltd." 407 "Comtech Mobile Datacom" 406 "Vecima Networks Inc." 405 "Wema System AS" 404 "Com Nav Marine Ltd" 403 "Trackwell ADS, Inc." 402 "Simma Software, Inc." 401 "Torqeedo GmbH" 400 "Livorsi Marine" 399 "ISEKI & Co., Ltd." 398 "Hilite International" 397 "Sanyo-kiki Co Ltd." 396 "Beyond Measure" 395 "GENTEC S.R.L." 394 "Capi 2 Nederland BV" 393 "Harvest Tec, Inc" 392 "Tianyuan Technology Co Ltd." 391 "Electronic Design for Industry, Inc" 390 "Partech Inc." 389 "Benchmark Electronics, Minnesota Division" 339 "Competence Center ISOBUS e.V." 338 "GRAF-SYTECO" 337 "Carraro S.p.A." 336 "APE s.r.o." 335 "Evo Electric Ltd" 334 "Takata-Petri AG" 333 "Hadley Products Corporation" 332 "HWH Corporation" 331 "Horton, Inc." 330 "Kidde Aerospace and Defense" 329 "Deif A/S" 328 "Qwerty Electronik AB" 327 "Sonceboz SA" 326 "Akron Brass Company" 325 "ASM Automation Sensorik Messtechnik GmbH" 324 "Snap-on Diagnostics" 323 "Mobileye Vision Technologies Ltd." 322 "MICHENKA s.r.o." 321 "Ultra Electronics, Electrics" 320 "Miedema Landbouwwerktuigenfabriek B.V." 319 "Cadec Global" 318 "SAT Plan" 317 "Navtronics Bvba" 316 "ITT Flow Control" 315 "Icom Incorporated" 314 "CSM GmbH" 313 "Ilmor Engineering, Inc." 312 "Lectronix, Inc." 311 "Patrick Power Products" 310 "TECNORD srl" 309 "Krauss-Maffei Wegmann GmbH & Co. KG" 308 "Cyntrx" 307 "MAS Technologies" 306 "Sleipner Motor AB" 305 "NovAtel Inc" 304 "EmpirBus AB" 303 "CTS Corporation" 302 "Nissin Kogyo Co., LTD" 301 "Parker Hannifin (UK) Ltd FDE group" 300 "Systron Donner Automotive" 299 "Rauch" 298 "Holley Performance" 297 "Zonar Systems Inc" 296 "micro dynamics GmbH" 295 "BEP Marine" 294 "Grayhill Inc." 293 "Spyder Controls Corp." 292 "IKUSI - Angel Iglesias S.A." 291 "Groeneveld Transport Efficiency BV" 290 "Kuebler GmbH" 289 "Watlow" 288 "Mitsubishi FUSO Truck & Bus Corp." 287 "NTech Industries, Inc" 286 "Coelmo srl" 285 "Sea Recovery Corp" 284 "Mobile Tech Chile" 283 "CWF Hamilton & Co Ltd" 282 "Medallion Instrumentation Systems" 281 "Precision Governors LLC" 280 "Leica Geosystems Pty Ltd" 279 "Geometris LP" 278 "Takata Electronics" 277 "LHP Telematics" 276 "Aqua-Hot Heating Systems" 275 "Navico Egersund AS" 274 "LTW Technology Co., LTD" 273 "Active Research Limited" 272 "Gross Mechanical Laboratories, Inc" 271 "Cole Hersee" 270 "Tennant" 269 "Saft America Inc.,  Space & Defense Division" 268 "Accurate Technologies" 267 "Red Lion Controls, Inc" 266 "International Thermal Research Ltd" 265 "MTS Sensor Technologie GmbH" 264 "Autolync" 263 "IMMI" 262 "HydraForce, Inc" 261 "Red Dot Corporation" 260 "Reichhardt GmbH Steuerungstechnik" 259 "Jetter AG" 258 "ARAG" 257 "Honda Motor Co., Ltd" 256 "Tyco Electronics AMP" 255 "MEAS France" 254 "GE Sensing" 253 "Mobile Control Systems" 252 "Sensor-Technik Wiedemann GmbH" 251 "German Agricultural Society, Test Center (DLG)" 250 "Kuhn Group" 249 "Schaltbau GmbH" 248 "Cooper Standard Automotive Active Systems Group" 247 "ePULSE" 246 "Class 1, Inc" 245 "Capstan Ag Systems, Inc." 244 "Techno-Matic" 243 "eRide, Inc." 242 "Kokusandenki Co. Ltd" 241 "Schneider Automation SAS" 240 "Vanair Mfg" 239 "May & Scofield Ltd" 238 "ZF Friedrichshafen AG" 237 "Agtron Enterprises Inc" 236 "NORAC Systems International Inc" 235 "SailorMade Marine Telemetry - Tetra Technology Ltd." 184 "EIA Electronics" 183 "KDS Controls, Inc" 182 "Vehicle Systems Engineering B.V." 181 "Coretronics, Inc." 180 "Smart Power Systems" 179 "TeeJet Technologies Springfield (formerly Midwest Technologies Illinois, LLC)" 178 "Continental Automotive GmbH (formerly Siemens VDO Automotive AG)" 177 "Diagnostic Systems Associates" 176 "Moritz Aerospace" 175 "Veris Technologies, Inc." 174 "AB Volvo Penta" 173 "Ryeso, Inc." 172 "Yanmar Co., Ltd. (formerly Yanmar Marine USA)" 171 "Wachendorff Elektronik GmbH & Co. KG" 170 "Computronics Corporation Ltd." 169 "Marlin Technologies Inc." 168 "Xantrex" 167 "JLG Industries Inc" 166 "John Deere Electronic Solutions (formerly Phoenix International)" 165 "CPAC Systems AB" 164 "MTU Friedrichshafen GmbH (formerly DaimlerChrysler Off-Highway)" 163 "BRP Inc." 162 "Axiomatic Technologies" 161 "Offshore Systems (UK) Ltd" 160 "Nido" 159 "NTech Industries Inc" 158 "Firestone Industrial Products Company" 157 "ISSPRO Inc." 156 "ITT Industries - Cannon" 155 "Vetronix Corporation" 154 "Westerbeke Corporation" 153 "Woodward, Industrial Controls Division" 152 "elobau GmbH & Co. KG" 151 "Raven Industries, Inc." 150 "Fleetguard" 149 "Holset" 148 "Blue Water Data, Inc." 147 "Nautibus electronic GmbH" 146 "Maxima Technologies" 145 "MurCal Controls" 144 "Mercury Marine" 143 "W. Gmeiner GmbH & Co." 142 "TRW Automotive (Commercial Steering Systems)" 141 "Thales Navigation Ltd." 140 "Lowrance Electronics, Inc." 127 "Holland USA" 126 "Driver Tech" 125 "Nevada Automotive Test Center" 124 "Hydac Electronic" 123 "Basler Electric" 122 "FG Wilson (Engineering) Limited" 121 "HED (Hydro Electronic Devices, Inc.)" 120 "RDS Technology Ltd" 119 "IntegriNautics젨" 118 "Intron GmbH" 117 "HUSCO International" 116 "BEELINE Technologies" 115 "NACCO Materials Handling Group, Inc." 114 "EControls, Inc." 113 "Stress-Tek, Inc." 112 "MECALAC" 111 "Maschinenfabrik Bernard Krone GmbH" 110 "EPIQ Sensor-Nite" 109 "TeeJet Technologies Denmark (formerly LH Technologies ApS)" 108 "WTK-Elecktronik GmbH" 107 "Grimme Landmaschinen GmbH & Co. KG" 106 "BAE Systems Controls, Inc." 105 "Kiepe Elektrik GmbH & Co. KG" 104 "CLAAS KGaA mbH (formerly CLAAS Selbstfahrende Erntemaschinen GmbH)" 103 "CLAAS E-Systems KGaA mbH & Co. KG (formerly CLAAS Agrosystems GmbH & Co. KG)" 102 "AGCO (formerly AGCO GmbH & Co.)" 101 "Sensoria" 100 "VDO Technik AG" 99 "International Transmissions Ltd (ITL)" 98 "Mueller-Elektronik GmbH & Co" 97 "Ag Leader Technology, Inc." 96 "Mech@tronic IT GmbH" 95 "Pacific Insight Electronics Corp." 94 "CNH Industrial N.V. (formerly CNH Global N.V.)" 93 "Perkins Engines Company Ltd." 92 "Ag-Chem Equipment Co., Inc." 91 "BSG Bodensee Steuergeraete GmbH" 90 "Knorr-Bremse SfN GmbH" 89 "Kverneland Group, Electronics Division" 88 "Hemisphere GPS Inc (formerly Satloc Precision GPS)" 87 "J.C. Bamford Excavators Ltd (JCB)" 86 "C. E. Niehoff & Company" 85 "Kohler Co" 84 "New Holland UK Limited" 83 "Bendix VORAD Technologies (formerly Eaton VORAD Technologies)" 82 "Bobcat/Ingersoll-Rand (formerly Melroe/Ingersoll-Rand)" 81 "Fire Research Corp." 80 "Twin Disc, Inc." 79 "Daimler Benz AG - Engine Division (PBM)" 78 "Frank W. Murphy Manufacturing, Inc" 77 "Deere Power Systems Group" 76 "unused (formerly Deere & Co, Construction Division)" 75 "Deere & Co, Agricultural Division" 74 "Eaton Axle-Brake Division" 73 "LeTourneau, Inc." 72 "Sisu Corporation" 71 "Vansco Electronics Ltd." 70 "Flex-coil Limited" 69 "Trimble Navigation" 68 "Scania" 67 "John Deere Coffeyville Works (formerly Funk Manufacturing Company)" 66 "John Deere Construction Equipment Division" 65 "MAN Nutzfahrzeuge AG" 64 "Unused (formerly SpectraPrecision Laserplane, then SpectraPhysics)" 63 "ZF Industries Inc." 62 "Wabco" 61 "Volvo Truck Corp." 60 "Volvo Trucks North America Inc." 59 "VES Inc." 58 "SPX Corporation, OTC Div" 57 "Danfoss  (formerly Sauer Sundstrand Co, then Sauer-Danfoss Co)" 56 "SAIC" 55 "Ryder System Inc." 54 "Meritor Wabco" 53 "Continental Automotive Systems US, Inc. (formerly Rockwell Land Transportation)" 52 "Meritor Automotive, Inc. (formerly Rockwell Automotive)" 51 "Robert Bosch GmbH" 50 "Robert Bosch Corp" 49 "RE America Inc." 48 "Pollak Alphabet" 47 "Phillips Semiconductor" 46 "Noregon Systems, Inc  (formerly Parasoft Computing Solutions)" 45 "PACCAR" 44 "Nippondenso Co. Ltd." 43 "International Truck and Engine Corporation - Vehicle Electronics (formerly Navistar Intl Trans Corp.)" 42 "International Truck and Engine Corporation - Engine Electronics  (formerly Navistar Intl Trans Co., Engine Electronics)" 41 "Motorola Inc." 40 "Motorola AIEG Inc." 39 "Microfirm Inc." 38 "Micro Processor Systems Inc." 37 "Mack Trucks Inc." 36 "Lucas Ind." 35 "Kenworth Truck Co." 34 "Kelsey Hayes Co." 33 "John Deere" 32 "Jacobs Vehicle Systems" 31 "J Pollak Corp" 30 "Isuzu Motors Ltd" 29 "Hino Motors Ltd." 28 "Grote Ind. Inc." 27 "GMC" 26 "General Motors Corp, Service Technology Grp" 25 "Daimler Trucks North America LLC (formerly Freightliner LLC)" 24 "Ford Motor Co., Vehicle Controls" 23 "Ford Motor Co., Heavy Truck" 22 "Ford Motor Co., Electronic Concepts & Systems" 21 "Echlin Inc., Midland Brake Inc." 20 "Eaton Ltd" 19 "Eaton Corp. Trucking Info Services" 18 "Eaton Corp, Transmission Div." 17 "Eaton Corp, Corp Res & Dev" 16 "Eaton Corp" 15 "DICKEY-john Corporation" 14 "Detroit Diesel Corporation" 13 "Delco Electronics" 12 "Deere & Company, Precision Farming" 11 "Dearborn Group Inc." 10 "Cummins Inc (formerly Cummins Engine Co)" 9 "Chrysler Corp." 8 "Caterpillar Inc." 7 "Case Corp." 6 "Berifors Electronics AB" 5 "AMP Inc." 4 "Ametek-Dixson" 3 "Ametek, US Gauge Division" 2 "Allison Transmission, Inc." 1 "Bendix Commercial Vehicle Systems LLC (formerly Allied Signal Inc.)" 0 "Reserved" ;
VAL_ 2565799678 VehicleSystem 0 "Non-specific System" 127 "Not Available" ;
VAL_ 2565799678 VehicleSystem5 127 "Not Available" 0 "Ind. Process Control Stationary" ;
VAL_ 2565799678 VehicleSystem4 125 "Entertainment" 120 "Display" 85 "External Environment" 75 "Sensor Communication Interface" 35 "Electrical Generation" 100 "Deck, Cargo and Fishing Equipment" 90 "Internal Environment" 80 "Instrumentation/General Systems (deprecate)" 70 "Communications" 60 "Navigation" 50 "Propulsion" 40 "Steering and Control Surfaces" 30 "Electrical Distribution" 25 "Inter/Intranetwork Device" 20 "Safety Systems" 10 "System Tools" 127 "Not Available" 0 "Non-specific System" ;
VAL_ 2565799678 VehicleSystem3 8 "Grader" 7 "Four Wheel Drive Loader" 6 "Forklift" 5 "Excavator" 4 "Crawler" 3 "Backhoe" 2 "Articulated Dump Truck" 1 "Skid Steer Loader" 127 "Not Available" 0 "Non-specific System" ;
VAL_ 2565799678 VehicleSystem2 25 "Slurry Applicators" 24 "Utility Vehicles" 23 "Mulchers" 22 "Timber Processing Machines" 21 "Timber loaders" 20 "Forwarders" 19 "Timber Harvesters" 17 "Sensor Systems" 16 "Skidder" 15 "Earth Work" 14 "Special Crops" 13 "Powered Auxiliary Device" 12 "Farm Yard Operations" 11 "Transport/Trailer" 10 "Irrigation" 9 "Forage" 8 "Root Harvesters" 7 "Harvesters" 6 "Sprayers" 5 "Fertilizers" 4 "Planters/Seeders" 3 "Secondary Tillage" 2 "Tillage" 1 "Tractor" 127 "Not Available" 0 "Non-specific System" ;
VAL_ 2565799678 VehicleSystem1 2 "Trailer" 1 "Tractor" 127 "Not Available" 0 "Non-specific System" ;
VAL_ 2565668606 ConnectionAbortReason 255 "Not available" 254 "Error indicator" 250 "Connection Abort reason is not listed" 9 "Total Message Size is greater than 1785 bytes" 8 "Duplicate sequence number (software cannot recover)" 7 "Bad sequence number (software cannot recover)" 6 "Unexpected data transfer packet" 5 "Maximum retransmit request limit reached" 4 "CTS messages received when data transfer is in progress." 3 "A timeout occurred and this is the connection abort to close the session." 2 "System resources were needed for another task so this connection managed session was terminated." 1 "Already in one or more connection managed sessions and cannot support another." ;
VAL_ 2565668606 PGNumber 255 "NotAvailable" ;
VAL_ 2565668606 ControlByte 255 "Abort" 32 "BAM" 19 "EoMA" 17 "CTS" 16 "RTS" ;
VAL_ 2563374846 UseTransferMode 3 "NA" 2 "Undefined" 1 "Yes" 0 "No" ;
VAL_ 2499635966 AdditionalAxleGroupLocation 2 "Rear Drive axle group" 1 "Rear Steer axle group" 0 "Reserved" ;
VAL_ 2499635966 AxleGroupLocation 15 "Reserved" 14 "Additional trailer axle group" 13 "Trailer H axle group" 12 "Trailer G axle group" 11 "Trailer F axle group" 10 "Trailer E axle group" 9 "Trailer D axle group" 8 "Trailer C axle group" 7 "Trailer B axle group" 6 "Trailer A axle group" 5 "Additional tractor axle group" 4 "Tag axle group" 3 "Sole or Forward-most Drive axle group" 2 "Lift axle group" 1 "Sole or Forward-most Steer axle group" 0 "Reserved" ;
VAL_ 2633853438 AdditionalAxleGroupLocation 2 "Rear Drive axle group" 1 "Rear Steer axle group" 0 "Reserved" ;
VAL_ 2633853438 AxleGroupLocation 15 "Reserved" 14 "Additional trailer axle group" 13 "Trailer H axle group" 12 "Trailer G axle group" 11 "Trailer F axle group" 10 "Trailer E axle group" 9 "Trailer D axle group" 8 "Trailer C axle group" 7 "Trailer B axle group" 6 "Trailer A axle group" 5 "Additional tractor axle group" 4 "Tag axle group" 3 "Sole or Forward-most Drive axle group" 2 "Lift axle group" 1 "Sole or Forward-most Steer axle group" 0 "Reserved" ;
VAL_ 2432520702 AftercoolerCoolantThermostatMode 3 "don't care/reserved" 2 "reserved" 1 "position control mode" 0 "temperature control mode" ;
VAL_ 2566745086 RarDriveAxleGroupWeightAvailable 3 "Not available / not applicable" 2 "Reserved" 1 "Rear drive axle group present" 0 "Rear drive axle group not present" ;
VAL_ 2566745086 RarSteerAxleGroupWeightAvailable 3 "Not available / not applicable" 2 "Reserved" 1 "Rear Steer axle group present" 0 "Rear Steer axle group not present" ;
VAL_ 2566745086 AddtnlTrlrAxlGrupWeightAvailable 3 "Not available / not applicable" 2 "Reserved" 1 "Additional trailer axle group present" 0 "Additional trailer axle group not present" ;
VAL_ 2566745086 TrailerHAxleGroupWeightAvailable 3 "Not available / not applicable" 2 "Reserved" 1 "Trailer H axle group present" 0 "Trailer H axle group not present" ;
VAL_ 2566745086 TrailerGAxleGroupWeightAvailable 3 "Not available / not applicable" 2 "Reserved" 1 "Trailer G axle group present" 0 "Trailer G axle group not present" ;
VAL_ 2566745086 TrailerFAxleGroupWeightAvailable 3 "Not available / not applicable" 2 "Reserved" 1 "Trailer F axle group present" 0 "Trailer F axle group not present" ;
VAL_ 2566745086 TrailerEAxleGroupWeightAvailable 3 "Not available / not applicable" 2 "Reserved" 1 "Trailer E axle group present" 0 "Trailer E axle group not present" ;
VAL_ 2566745086 TrailerDAxleGroupWeightAvailable 3 "Not available / not applicable" 2 "Reserved" 1 "Trailer D axle group present" 0 "Trailer D axle group not present" ;
VAL_ 2566745086 TrailerCAxleGroupWeightAvailable 3 "Not available / not applicable" 2 "Reserved" 1 "Trailer C axle group present" 0 "Trailer C axle group not present" ;
VAL_ 2566745086 TrailerBAxleGroupWeightAvailable 3 "Not available / not applicable" 2 "Reserved" 1 "Trailer B axle group present" 0 "Trailer B axle group not present" ;
VAL_ 2566745086 TrailerAAxleGroupWeightAvailable 3 "Not available / not applicable" 2 "Reserved" 1 "Trailer A axle group present" 0 "Trailer A axle group not present" ;
VAL_ 2566745086 AddtnlTrctrAxlGrpWeightAvailable 3 "Not available / not applicable" 2 "Reserved" 1 "Additional tractor axle group present" 0 "Additional tractor axle group not present" ;
VAL_ 2566745086 TagAxleGroupWeightAvailable 3 "Not available / not applicable" 2 "Reserved" 1 "Tag axle group present" 0 "Tag axle group not present" ;
VAL_ 2566745086 DriveAxleGroupWeightAvailable 3 "Not available / not applicable" 2 "Reserved" 1 "Drive axle group present" 0 "Drive axle group not present" ;
VAL_ 2566745086 LiftAxleGroupWeightAvailable 3 "Not available / not applicable" 2 "Reserved" 1 "Lift axle group present" 0 "Lift axle group not present" ;
VAL_ 2566745086 SteerAxleGroupWeightAvailable 3 "Not available / not applicable" 2 "Reserved" 1 "Steer axle group present" 0 "Steer axle group not present" ;
VAL_ 2566739198 FlashRedStopLamp 3 "Unavailable / Do Not Flash" 2 "Reserved" 1 "Fast Flash" 0 "Slow Flash" ;
VAL_ 2566739198 FlashProtectLamp 3 "Unavailable / Do Not Flash" 2 "Reserved" 1 "Fast Flash" 0 "Slow Flash" ;
VAL_ 2566739198 FlashMalfuncIndicatorLamp 3 "Unavailable / Do Not Flash" 2 "Class C DTC  " 1 "Fast Flash" 0 "Slow Flash" ;
VAL_ 2566739198 FlashAmberWarningLamp 3 "Unavailable / Do Not Flash" 2 "Reserved" 1 "Fast Flash" 0 "Slow Flash" ;
VAL_ 2566739198 MalfunctionIndicatorLampStatus 3 "Not available" 2 "Short MIL for WWH OBD" 1 "Lamp On" 0 "Lamp Off" ;
VAL_ 2566739198 AmberWarningLampStatus 3 "Not available" 2 "Reserved" 1 "Lamp On" 0 "Lamp Off" ;
VAL_ 2566739198 RedStopLampState 3 "Not available" 2 "Reserved" 1 "Lamp On" 0 "Lamp Off" ;
VAL_ 2566739198 ProtectLampStatus 3 "Not available" 2 "Reserved" 1 "Lamp On" 0 "Lamp Off" ;
VAL_ 2566739454 FlashRedStopLamp 3 "Unavailable / Do Not Flash" 2 "Reserved" 1 "Fast Flash" 0 "Slow Flash" ;
VAL_ 2566739454 FlashProtectLamp 3 "Unavailable / Do Not Flash" 2 "Reserved" 1 "Fast Flash" 0 "Slow Flash" ;
VAL_ 2566739454 FlashMalfuncIndicatorLamp 3 "Unavailable / Do Not Flash" 2 "Class C DTC  " 1 "Fast Flash" 0 "Slow Flash" ;
VAL_ 2566739454 FlashAmberWarningLamp 3 "Unavailable / Do Not Flash" 2 "Reserved" 1 "Fast Flash" 0 "Slow Flash" ;
VAL_ 2566739454 MalfunctionIndicatorLampStatus 3 "Not available" 2 "Short MIL for WWH OBD" 1 "Lamp On" 0 "Lamp Off" ;
VAL_ 2566739454 AmberWarningLampStatus 3 "Not available" 2 "Reserved" 1 "Lamp On" 0 "Lamp Off" ;
VAL_ 2566739454 RedStopLampState 3 "Not available" 2 "Reserved" 1 "Lamp On" 0 "Lamp Off" ;
VAL_ 2566739454 ProtectLampStatus 3 "Not available" 2 "Reserved" 1 "Lamp On" 0 "Lamp Off" ;
VAL_ 2566739710 FlashRedStopLamp 3 "Unavailable / Do Not Flash" 2 "Reserved" 1 "Fast Flash" 0 "Slow Flash" ;
VAL_ 2566739710 FlashProtectLamp 3 "Unavailable / Do Not Flash" 2 "Reserved" 1 "Fast Flash" 0 "Slow Flash" ;
VAL_ 2566739710 FlashMalfuncIndicatorLamp 3 "Unavailable / Do Not Flash" 2 "Class C DTC  " 1 "Fast Flash" 0 "Slow Flash" ;
VAL_ 2566739710 FlashAmberWarningLamp 3 "Unavailable / Do Not Flash" 2 "Reserved" 1 "Fast Flash" 0 "Slow Flash" ;
VAL_ 2566739710 MalfunctionIndicatorLampStatus 3 "Not available" 2 "Short MIL for WWH OBD" 1 "Lamp On" 0 "Lamp Off" ;
VAL_ 2566739710 AmberWarningLampStatus 3 "Not available" 2 "Reserved" 1 "Lamp On" 0 "Lamp Off" ;
VAL_ 2566739710 RedStopLampState 3 "Not available" 2 "Reserved" 1 "Lamp On" 0 "Lamp Off" ;
VAL_ 2566739710 ProtectLampStatus 3 "Not available" 2 "Reserved" 1 "Lamp On" 0 "Lamp Off" ;
VAL_ 2566739966 FlashRedStopLamp 3 "Unavailable / Do Not Flash" 2 "Reserved" 1 "Fast Flash" 0 "Slow Flash" ;
VAL_ 2566739966 FlashProtectLamp 3 "Unavailable / Do Not Flash" 2 "Reserved" 1 "Fast Flash" 0 "Slow Flash" ;
VAL_ 2566739966 FlashMalfuncIndicatorLamp 3 "Unavailable / Do Not Flash" 2 "Class C DTC  " 1 "Fast Flash" 0 "Slow Flash" ;
VAL_ 2566739966 FlashAmberWarningLamp 3 "Unavailable / Do Not Flash" 2 "Reserved" 1 "Fast Flash" 0 "Slow Flash" ;
VAL_ 2566739966 MalfunctionIndicatorLampStatus 3 "Not available" 2 "Short MIL for WWH OBD" 1 "Lamp On" 0 "Lamp Off" ;
VAL_ 2566739966 AmberWarningLampStatus 3 "Not available" 2 "Reserved" 1 "Lamp On" 0 "Lamp Off" ;
VAL_ 2566739966 RedStopLampState 3 "Not available" 2 "Reserved" 1 "Lamp On" 0 "Lamp Off" ;
VAL_ 2566739966 ProtectLampStatus 3 "Not available" 2 "Reserved" 1 "Lamp On" 0 "Lamp Off" ;
VAL_ 2566740222 FlashRedStopLamp 3 "Unavailable / Do Not Flash" 2 "Reserved" 1 "Fast Flash" 0 "Slow Flash" ;
VAL_ 2566740222 FlashProtectLamp 3 "Unavailable / Do Not Flash" 2 "Reserved" 1 "Fast Flash" 0 "Slow Flash" ;
VAL_ 2566740222 FlashMalfuncIndicatorLamp 3 "Unavailable / Do Not Flash" 2 "Class C DTC  " 1 "Fast Flash" 0 "Slow Flash" ;
VAL_ 2566740222 FlashAmberWarningLamp 3 "Unavailable / Do Not Flash" 2 "Reserved" 1 "Fast Flash" 0 "Slow Flash" ;
VAL_ 2566740222 MalfunctionIndicatorLampStatus 3 "Not available" 2 "Short MIL for WWH OBD" 1 "Lamp On" 0 "Lamp Off" ;
VAL_ 2566740222 AmberWarningLampStatus 3 "Not available" 2 "Reserved" 1 "Lamp On" 0 "Lamp Off" ;
VAL_ 2566740222 RedStopLampState 3 "Not available" 2 "Reserved" 1 "Lamp On" 0 "Lamp Off" ;
VAL_ 2566740222 ProtectLampStatus 3 "Not available" 2 "Reserved" 1 "Lamp On" 0 "Lamp Off" ;
VAL_ 2566740478 FlashRedStopLamp 3 "Unavailable / Do Not Flash" 2 "Reserved" 1 "Fast Flash" 0 "Slow Flash" ;
VAL_ 2566740478 FlashProtectLamp 3 "Unavailable / Do Not Flash" 2 "Reserved" 1 "Fast Flash" 0 "Slow Flash" ;
VAL_ 2566740478 FlashMalfuncIndicatorLamp 3 "Unavailable / Do Not Flash" 2 "Class C DTC  " 1 "Fast Flash" 0 "Slow Flash" ;
VAL_ 2566740478 FlashAmberWarningLamp 3 "Unavailable / Do Not Flash" 2 "Reserved" 1 "Fast Flash" 0 "Slow Flash" ;
VAL_ 2566740478 MalfunctionIndicatorLampStatus 3 "Not available" 2 "Short MIL for WWH OBD" 1 "Lamp On" 0 "Lamp Off" ;
VAL_ 2566740478 AmberWarningLampStatus 3 "Not available" 2 "Reserved" 1 "Lamp On" 0 "Lamp Off" ;
VAL_ 2566740478 RedStopLampState 3 "Not available" 2 "Reserved" 1 "Lamp On" 0 "Lamp Off" ;
VAL_ 2566740478 ProtectLampStatus 3 "Not available" 2 "Reserved" 1 "Lamp On" 0 "Lamp Off" ;
VAL_ 2566740734 FlashRedStopLamp 3 "Unavailable / Do Not Flash" 2 "Reserved" 1 "Fast Flash" 0 "Slow Flash" ;
VAL_ 2566740734 FlashProtectLamp 3 "Unavailable / Do Not Flash" 2 "Reserved" 1 "Fast Flash" 0 "Slow Flash" ;
VAL_ 2566740734 FlashMalfuncIndicatorLamp 3 "Unavailable / Do Not Flash" 2 "Class C DTC  " 1 "Fast Flash" 0 "Slow Flash" ;
VAL_ 2566740734 FlashAmberWarningLamp 3 "Unavailable / Do Not Flash" 2 "Reserved" 1 "Fast Flash" 0 "Slow Flash" ;
VAL_ 2566740734 MalfunctionIndicatorLampStatus 3 "Not available" 2 "Short MIL for WWH OBD" 1 "Lamp On" 0 "Lamp Off" ;
VAL_ 2566740734 AmberWarningLampStatus 3 "Not available" 2 "Reserved" 1 "Lamp On" 0 "Lamp Off" ;
VAL_ 2566740734 RedStopLampState 3 "Not available" 2 "Reserved" 1 "Lamp On" 0 "Lamp Off" ;
VAL_ 2566740734 ProtectLampStatus 3 "Not available" 2 "Reserved" 1 "Lamp On" 0 "Lamp Off" ;
VAL_ 2566740990 FlashRedStopLamp 3 "Unavailable / Do Not Flash" 2 "Reserved" 1 "Fast Flash" 0 "Slow Flash" ;
VAL_ 2566740990 FlashProtectLamp 3 "Unavailable / Do Not Flash" 2 "Reserved" 1 "Fast Flash" 0 "Slow Flash" ;
VAL_ 2566740990 FlashMalfuncIndicatorLamp 3 "Unavailable / Do Not Flash" 2 "Class C DTC  " 1 "Fast Flash" 0 "Slow Flash" ;
VAL_ 2566740990 FlashAmberWarningLamp 3 "Unavailable / Do Not Flash" 2 "Reserved" 1 "Fast Flash" 0 "Slow Flash" ;
VAL_ 2566740990 MalfunctionIndicatorLampStatus 3 "Not available" 2 "Short MIL for WWH OBD" 1 "Lamp On" 0 "Lamp Off" ;
VAL_ 2566740990 AmberWarningLampStatus 3 "Not available" 2 "Reserved" 1 "Lamp On" 0 "Lamp Off" ;
VAL_ 2566740990 RedStopLampState 3 "Not available" 2 "Reserved" 1 "Lamp On" 0 "Lamp Off" ;
VAL_ 2566740990 ProtectLampStatus 3 "Not available" 2 "Reserved" 1 "Lamp On" 0 "Lamp Off" ;
VAL_ 2566741246 FlashRedStopLamp 3 "Unavailable / Do Not Flash" 2 "Reserved" 1 "Fast Flash" 0 "Slow Flash" ;
VAL_ 2566741246 FlashProtectLamp 3 "Unavailable / Do Not Flash" 2 "Reserved" 1 "Fast Flash" 0 "Slow Flash" ;
VAL_ 2566741246 FlashMalfuncIndicatorLamp 3 "Unavailable / Do Not Flash" 2 "Class C DTC  " 1 "Fast Flash" 0 "Slow Flash" ;
VAL_ 2566741246 FlashAmberWarningLamp 3 "Unavailable / Do Not Flash" 2 "Reserved" 1 "Fast Flash" 0 "Slow Flash" ;
VAL_ 2566741246 MalfunctionIndicatorLampStatus 3 "Not available" 2 "Short MIL for WWH OBD" 1 "Lamp On" 0 "Lamp Off" ;
VAL_ 2566741246 AmberWarningLampStatus 3 "Not available" 2 "Reserved" 1 "Lamp On" 0 "Lamp Off" ;
VAL_ 2566741246 RedStopLampState 3 "Not available" 2 "Reserved" 1 "Lamp On" 0 "Lamp Off" ;
VAL_ 2566741246 ProtectLampStatus 3 "Not available" 2 "Reserved" 1 "Lamp On" 0 "Lamp Off" ;
VAL_ 2566741502 FlashRedStopLamp 3 "Unavailable / Do Not Flash" 2 "Reserved" 1 "Fast Flash" 0 "Slow Flash" ;
VAL_ 2566741502 FlashProtectLamp 3 "Unavailable / Do Not Flash" 2 "Reserved" 1 "Fast Flash" 0 "Slow Flash" ;
VAL_ 2566741502 FlashMalfuncIndicatorLamp 3 "Unavailable / Do Not Flash" 2 "Class C DTC  " 1 "Fast Flash" 0 "Slow Flash" ;
VAL_ 2566741502 FlashAmberWarningLamp 3 "Unavailable / Do Not Flash" 2 "Reserved" 1 "Fast Flash" 0 "Slow Flash" ;
VAL_ 2566741502 MalfunctionIndicatorLampStatus 3 "Not available" 2 "Short MIL for WWH OBD" 1 "Lamp On" 0 "Lamp Off" ;
VAL_ 2566741502 AmberWarningLampStatus 3 "Not available" 2 "Reserved" 1 "Lamp On" 0 "Lamp Off" ;
VAL_ 2566741502 RedStopLampState 3 "Not available" 2 "Reserved" 1 "Lamp On" 0 "Lamp Off" ;
VAL_ 2566741502 ProtectLampStatus 3 "Not available" 2 "Reserved" 1 "Lamp On" 0 "Lamp Off" ;
VAL_ 2566741758 FlashRedStopLamp 3 "Unavailable / Do Not Flash" 2 "Reserved" 1 "Fast Flash" 0 "Slow Flash" ;
VAL_ 2566741758 FlashProtectLamp 3 "Unavailable / Do Not Flash" 2 "Reserved" 1 "Fast Flash" 0 "Slow Flash" ;
VAL_ 2566741758 FlashMalfuncIndicatorLamp 3 "Unavailable / Do Not Flash" 2 "Class C DTC  " 1 "Fast Flash" 0 "Slow Flash" ;
VAL_ 2566741758 FlashAmberWarningLamp 3 "Unavailable / Do Not Flash" 2 "Reserved" 1 "Fast Flash" 0 "Slow Flash" ;
VAL_ 2566741758 MalfunctionIndicatorLampStatus 3 "Not available" 2 "Short MIL for WWH OBD" 1 "Lamp On" 0 "Lamp Off" ;
VAL_ 2566741758 AmberWarningLampStatus 3 "Not available" 2 "Reserved" 1 "Lamp On" 0 "Lamp Off" ;
VAL_ 2566741758 RedStopLampState 3 "Not available" 2 "Reserved" 1 "Lamp On" 0 "Lamp Off" ;
VAL_ 2566741758 ProtectLampStatus 3 "Not available" 2 "Reserved" 1 "Lamp On" 0 "Lamp Off" ;
